VERSION ""

NS_ :

BS_:

BU_: GWM SCMB_PSM HVAC_RCCM GENERIC_GWMWakeup SOBDMD_AHCM_FOH TRM _delete SODL RTM PDM SCMH SCMG RSM SODR DDM RGTM DSM SCME TSTR

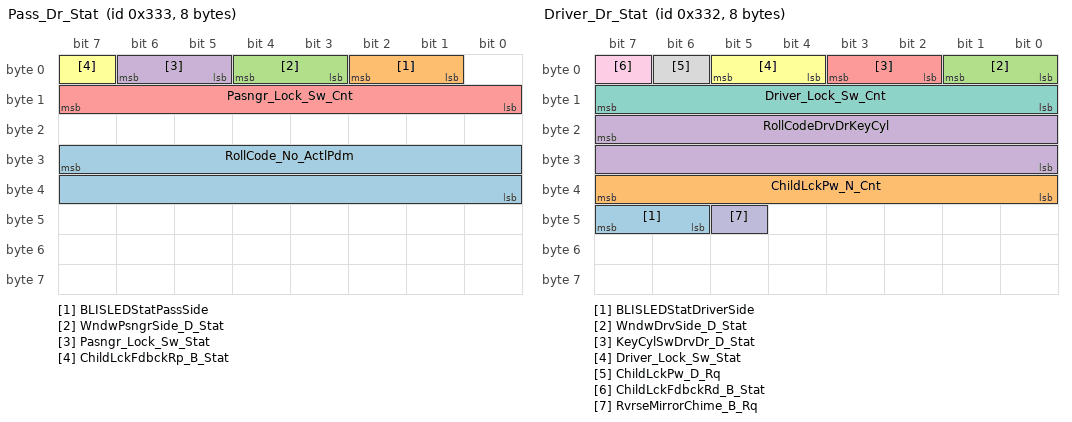
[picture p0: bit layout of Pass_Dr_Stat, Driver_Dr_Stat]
BO_ 819 Pass_Dr_Stat: 8 PDM
 SG_ RollCode_No_ActlPdm : 31|16@0+ (1,0) [0|65535] "Unitless"  GWM
 SG_ BLISLEDStatPassSide : 2|2@0+ (1,0) [0|3] "SED"  GWM,SODL,SODR
 SG_ WndwPsngrSide_D_Stat : 4|2@0+ (1,0) [0|3] "SED"  GWM
 SG_ Pasngr_Lock_Sw_Stat : 6|2@0+ (1,0) [0|3] "SED"  GWM
 SG_ Pasngr_Lock_Sw_Cnt : 15|8@0+ (1,0) [0|255] "Cnt"  GWM
 SG_ ChildLckFdbckRp_B_Stat : 7|1@0+ (1,0) [0|1] "SED"  GWM

BO_ 818 Driver_Dr_Stat: 8 DDM
 SG_ BLISLEDStatDriverSide : 47|2@0+ (1,0) [0|3] "SED"  GWM,SODL,SODR
 SG_ ChildLckPw_N_Cnt : 39|8@0+ (1,0) [0|255] "unitless"  GWM
 SG_ WndwDrvSide_D_Stat : 1|2@0+ (1,0) [0|3] "SED"  GWM
 SG_ RollCodeDrvDrKeyCyl : 23|16@0+ (1,0) [0|65535] "Unitless"  GWM
 SG_ KeyCylSwDrvDr_D_Stat : 3|2@0+ (1,0) [0|3] "SED"  GWM
 SG_ Driver_Lock_Sw_Stat : 5|2@0+ (1,0) [0|3] "SED"  GWM
 SG_ Driver_Lock_Sw_Cnt : 15|8@0+ (1,0) [0|255] "Cnt"  GWM
 SG_ ChildLckPw_D_Rq : 6|1@0+ (1,0) [0|1] "SED"  GWM
 SG_ ChildLckFdbckRd_B_Stat : 7|1@0+ (1,0) [0|1] "SED"  GWM
 SG_ RvrseMirrorChime_B_Rq : 45|1@0+ (1,0) [0|1] "SED"  DSM,GWM

BO_ 817 Locking_Systems_2_MS1: 8 GWM
 SG_ ChildLckMde_B_Stat : 56|1@0+ (1,0) [0|1] "SED" Vector__XXX
 SG_ VehLckInd_D_Rq : 58|2@0+ (1,0) [0|3] "SED"  DDM,PDM
 SG_ DrTgateOpen_B_Rq : 59|1@0+ (1,0) [0|1] "SED"  RGTM
 SG_ DrTgateExtSwMde_B_Stat : 32|1@0+ (1,0) [0|1] "SED"  RGTM
 SG_ Remote_Device_Feedback : 50|3@0+ (1,0) [0|7] "SED"  RSM,RTM
 SG_ Power_Liftgate_Rqst : 0|1@0+ (1,0) [0|1] "SED"  RGTM
 SG_ Power_Decklid_Rqst : 1|1@0+ (1,0) [0|1] "SED"  RGTM
 SG_ Keyfob_Pad_Msg_Count : 15|8@0+ (1,0) [0|255] "Counts"  RGTM
 SG_ Veh_Lock_Requestor : 55|5@0+ (1,0) [0|31] "SED"  HVAC_RCCM,RSM,DDM,PDM
 SG_ Veh_Lock_EvNum : 47|8@0+ (1,0) [0|255] "unitless"  HVAC_RCCM,RSM,DDM,PDM
 SG_ Veh_Lock_Sub_Id : 63|4@0+ (1,0) [0|15] "SED"  RSM,DDM,PDM
 SG_ ChildLck_D_Dsply : 7|2@0+ (1,0) [0|3] "SED"  DDM
 SG_ RollCodeUnlock : 23|16@0+ (1,0) [0|65535] "Unitless"  PDM,RSM,DDM
 SG_ Lockmsgtxt_D_Rq : 39|3@0+ (1,0) [0|7] "SED" Vector__XXX
 SG_ LockInhibit : 2|1@0+ (1,0) [0|1] "SED"  RGTM
 SG_ Veh_Lock_Status : 34|2@0+ (1,0) [0|3] "SED"  HVAC_RCCM,RSM,DDM,PDM,RGTM
 SG_ FobComm_D_Stat : 5|2@0+ (1,0) [0|3] "SED"  RTM
 SG_ WindowLockout_B_Stat : 35|1@0+ (1,0) [0|1] "SED"  SCMG,SCMH,SCMB_PSM,DDM

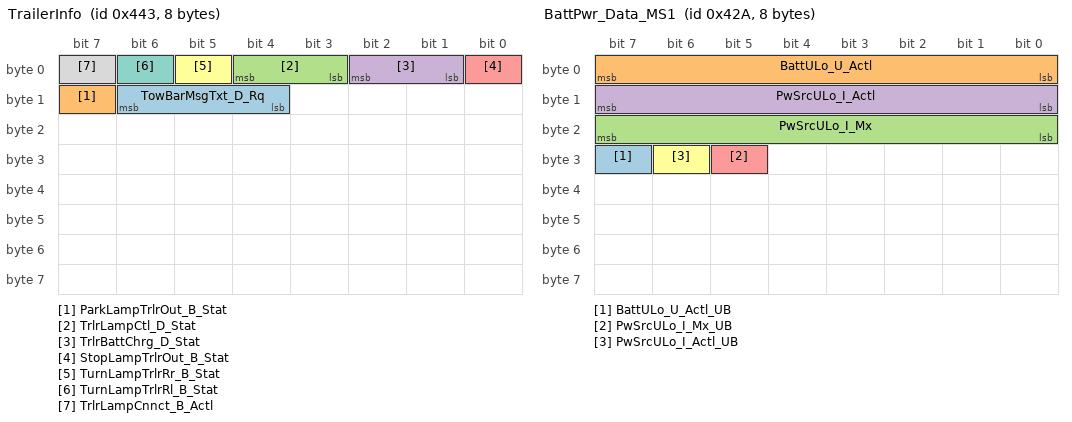
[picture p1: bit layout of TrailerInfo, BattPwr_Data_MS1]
BO_ 1091 TrailerInfo: 8 TRM
 SG_ TowBarMsgTxt_D_Rq : 14|3@0+ (1,0) [0|7] "SED"  GWM
 SG_ ParkLampTrlrOut_B_Stat : 15|1@0+ (1,0) [0|1] "SED"  GWM
 SG_ TrlrLampCtl_D_Stat : 4|2@0+ (1,0) [0|3] "SED"  GWM
 SG_ TrlrBattChrg_D_Stat : 2|2@0+ (1,0) [0|3] "SED"  GWM
 SG_ StopLampTrlrOut_B_Stat : 0|1@0+ (1,0) [0|1] "SED"  GWM
 SG_ TurnLampTrlrRr_B_Stat : 5|1@0+ (1,0) [0|1] "SED"  GWM
 SG_ TurnLampTrlrRl_B_Stat : 6|1@0+ (1,0) [0|1] "SED"  GWM
 SG_ TrlrLampCnnct_B_Actl : 7|1@0+ (1,0) [0|1] "SED"  SODR,SODL,GWM

BO_ 1865 TesterPhysicalResPDM: 8 PDM
 SG_ TesterPhysicalResPDM : 7|64@0+ (1,0) [0|1.84467E+019] "unitless"  TSTR

BO_ 1857 TesterPhysicalReqPDM: 8 TSTR
 SG_ TesterPhysicalReqPDM : 7|64@0+ (1,0) [0|1.84467E+019] "unitless"  PDM

BO_ 1819 TesterPhysicalResSCMH: 8 SCMH
 SG_ TesterPhysicalResSCMH : 7|64@0+ (1,0) [0|1.84467E+019] "unitless"  TSTR

BO_ 1818 TesterPhysicalResSCMG: 8 SCMG
 SG_ TesterPhysicalResSCMG : 7|64@0+ (1,0) [0|1.84467E+019] "unitless"  TSTR

BO_ 1811 TesterPhysicalReqSCMH: 8 TSTR
 SG_ TesterPhysicalReqSCMH : 7|64@0+ (1,0) [0|1.84467E+019] "unitless"  SCMH

BO_ 1810 TesterPhysicalReqSCMG: 8 TSTR
 SG_ TesterPhysicalReqSCMG : 7|64@0+ (1,0) [0|1.84467E+019] "unitless"  SCMG

BO_ 1310 GWM_Network_MgmtM_MS1: 8 GWM
 SG_ GWM_Network_Mgmt_MS1 : 7|64@0+ (1,0) [0|1.844674407371E+019] "unitless"  RSM,DDM

BO_ 1066 BattPwr_Data_MS1: 8 GWM
 SG_ BattULo_U_Actl_UB : 31|1@0+ (1,0) [0|1] "SED"  HVAC_RCCM
 SG_ BattULo_U_Actl : 7|8@0+ (0.0625,0) [0|15.875] "volt"  HVAC_RCCM
 SG_ PwSrcULo_I_Mx : 23|8@0+ (1,0) [0|254] "ampere"  HVAC_RCCM
 SG_ PwSrcULo_I_Actl : 15|8@0+ (1,0) [0|254] "ampere"  HVAC_RCCM
 SG_ PwSrcULo_I_Mx_UB : 29|1@0+ (1,0) [0|1] "SED"  HVAC_RCCM
 SG_ PwSrcULo_I_Actl_UB : 30|1@0+ (1,0) [0|1] "SED"  HVAC_RCCM

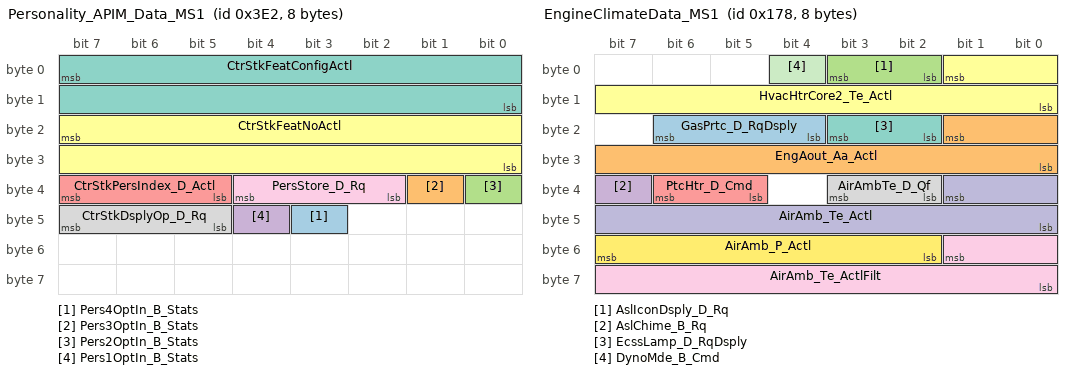
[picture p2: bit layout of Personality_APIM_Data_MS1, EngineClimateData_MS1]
BO_ 994 Personality_APIM_Data_MS1: 8 GWM
 SG_ Pers4OptIn_B_Stats : 43|1@0+ (1,0) [0|1] "SED" Vector__XXX
 SG_ Pers3OptIn_B_Stats : 33|1@0+ (1,0) [0|1] "SED" Vector__XXX
 SG_ Pers2OptIn_B_Stats : 32|1@0+ (1,0) [0|1] "SED" Vector__XXX
 SG_ Pers1OptIn_B_Stats : 44|1@0+ (1,0) [0|1] "SED" Vector__XXX
 SG_ CtrStkPersIndex_D_Actl : 39|3@0+ (1,0) [0|7] "SED"  HVAC_RCCM,PDM,DDM,DSM,SCMG,SCMH
 SG_ CtrStkFeatNoActl : 23|16@0+ (1,0) [0|65535] "Undefined"  HVAC_RCCM,PDM,DDM,DSM
 SG_ CtrStkFeatConfigActl : 7|16@0+ (1,0) [0|65535] "Undefined"  HVAC_RCCM,PDM,DDM,DSM
 SG_ CtrStkDsplyOp_D_Rq : 47|3@0+ (1,0) [0|7] "SED"  HVAC_RCCM,PDM,DDM,DSM,SCMG,SCMH
 SG_ PersStore_D_Rq : 36|3@0+ (1,0) [0|7] "SED"  DSM

BO_ 376 EngineClimateData_MS1: 8 GWM
 SG_ GasPrtc_D_RqDsply : 22|3@0+ (1,0) [0|7] "SED" Vector__XXX
 SG_ EngAout_Aa_Actl : 17|10@0+ (0.05,-25.6) [-25.6|25.55] "rpm/ms" Vector__XXX
 SG_ AslIconDsply_D_Rq : 3|2@0+ (1,0) [0|3] "SED" Vector__XXX
 SG_ AslChime_B_Rq : 39|1@0+ (1,0) [0|1] "SED" Vector__XXX
 SG_ PtcHtr_D_Cmd : 38|2@0+ (1,0) [0|3] "SED" Vector__XXX
 SG_ HvacHtrCore2_Te_Actl : 1|10@0+ (0.25,-50) [-50|205.5] "degC"  HVAC_RCCM
 SG_ EcssLamp_D_RqDsply : 19|2@0+ (1,0) [0|3] "SED" Vector__XXX
 SG_ AirAmbTe_D_Qf : 35|2@0+ (1,0) [0|3] "SED"  HVAC_RCCM
 SG_ AirAmb_Te_ActlFilt : 49|10@0+ (0.25,-128) [-128|127.75] "deg C"  HVAC_RCCM
 SG_ AirAmb_Te_Actl : 33|10@0+ (0.25,-128) [-128|127.75] "degC"  HVAC_RCCM
 SG_ DynoMde_B_Cmd : 4|1@0+ (1,0) [0|1] "SED" Vector__XXX
 SG_ AirAmb_P_Actl : 55|6@0+ (10,500) [500|1110] "mbar"  SOBDMD_AHCM_FOH

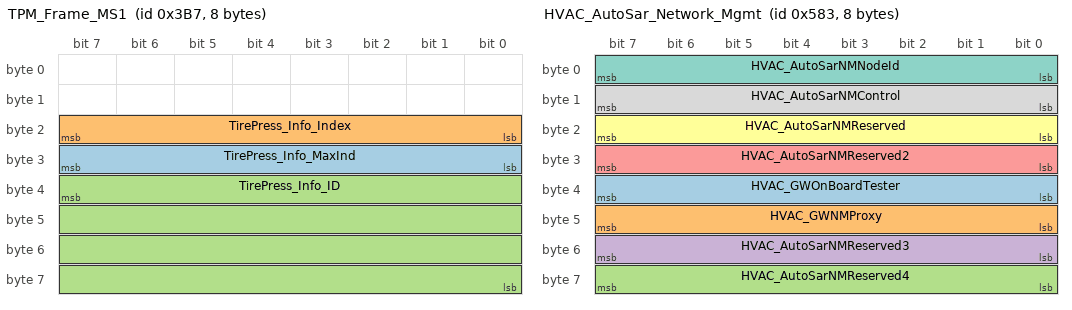
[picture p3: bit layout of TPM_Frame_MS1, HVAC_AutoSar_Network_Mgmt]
BO_ 951 TPM_Frame_MS1: 8 GWM
 SG_ TirePress_Info_MaxInd : 31|8@0+ (1,0) [0|255] "Unitless"  RTM
 SG_ TirePress_Info_Index : 23|8@0+ (1,0) [0|255] "Unitless"  RTM
 SG_ TirePress_Info_ID : 39|32@0+ (1,0) [0|4294967295] "Unitless"  RTM

BO_ 1068 Batt_Mgmt_Data_MS1: 8 GWM
 SG_ HvacAirFullOut_B_Rq_UB : 60|1@0+ (1,0) [0|1] "SED"  HVAC_RCCM
 SG_ HvacAirFullOut_B_Rq : 61|1@0+ (1,0) [0|1] "SED"  HVAC_RCCM
 SG_ HvacCmprLim_D_Stat_UB : 56|1@0+ (1,0) [0|1] "SED"  HVAC_RCCM
 SG_ HvacCmprLim_D_Stat : 59|3@0+ (1,0) [0|7] "SED"  HVAC_RCCM
 SG_ HvacAirFlw_B_RqBatt_UB : 62|1@0+ (1,0) [0|1] "SED"  HVAC_RCCM
 SG_ HvacAirFlw_B_RqBatt : 63|1@0+ (1,0) [0|1] "SED"  HVAC_RCCM
 SG_ HvacRec_D_RqMxBatt_UB : 21|1@0+ (1,0) [0|1] "SED"  HVAC_RCCM
 SG_ HvacRec_D_RqMxBatt : 20|4@0+ (1,0) [0|15] "SED"  HVAC_RCCM
 SG_ Batt_Lo_SoC_B_UB : 22|1@0+ (1,0) [0|1] "SED"  HVAC_RCCM,TRM
 SG_ Batt_Lo_SoC_B : 23|1@0+ (1,0) [0|1] "SED"  HVAC_RCCM,TRM
 SG_ Batt_Crit_SoC_B_UB : 14|1@0+ (1,0) [0|1] "SED"  HVAC_RCCM,TRM
 SG_ Batt_Crit_SoC_B : 15|1@0+ (1,0) [0|1] "SED"  HVAC_RCCM,TRM
 SG_ Shed_T_Eng_Off_B_UB : 12|1@0+ (1,0) [0|1] "SED"  HVAC_RCCM,TRM
 SG_ Shed_T_Eng_Off_B : 13|1@0+ (1,0) [0|1] "SED"  HVAC_RCCM,TRM
 SG_ Shed_Level_Req_UB : 8|1@0+ (1,0) [0|1] "SED"  HVAC_RCCM,DDM,PDM,TRM
 SG_ Shed_Level_Req : 11|3@0+ (1,0) [0|7] "SED"  HVAC_RCCM,DDM,PDM,TRM
 SG_ Shed_Feature_Group_ID_UB : 2|1@0+ (1,0) [0|1] "SED"  HVAC_RCCM,TRM
 SG_ Shed_Feature_Group_ID : 7|5@0+ (1,0) [0|31] "SED"  HVAC_RCCM,TRM
 SG_ Shed_Drain_Eng_Off_B_UB : 0|1@0+ (1,0) [0|1] "SED"  HVAC_RCCM,TRM
 SG_ Shed_Drain_Eng_Off_B : 1|1@0+ (1,0) [0|1] "SED"  HVAC_RCCM,TRM
 SG_ AirCondRec_B_Rq_UB : 44|1@0+ (1,0) [0|1] "SED"  HVAC_RCCM
 SG_ AirCondFluidHi_P_Actl_UB : 45|1@0+ (1,0) [0|1] "SED"  HVAC_RCCM
 SG_ AirCondFluidHi_P_Actl : 39|8@0+ (0.125,0) [0|31.625] "bar"  HVAC_RCCM
 SG_ AirCondClutch_B_Stats : 46|1@0+ (1,0) [0|1] "SED"  HVAC_RCCM
 SG_ AirCondClutch_B_Stats_UB : 43|1@0+ (1,0) [0|1] "SED"  HVAC_RCCM
 SG_ AirCondRec_B_Rq : 47|1@0+ (1,0) [0|1] "SED"  HVAC_RCCM

BO_ 963 BCM_Lamp_Stat_MS1: 8 GWM
 SG_ Illuminated_Entry_Stat : 63|2@0+ (1,0) [0|3] "SED" Vector__XXX
 SG_ Dr_Courtesy_Light_Stat : 49|2@0+ (1,0) [0|3] "SED" Vector__XXX
 SG_ ImpactEvntFdbck_D_Stat : 53|2@0+ (1,0) [0|3] "SED" Vector__XXX
 SG_ PudLampPsngr_D_Rq : 57|2@0+ (1,0) [0|3] "SED"  PDM
 SG_ HeadLampLoOut_B_Stat : 32|1@0+ (1,0) [0|1] "SED" Vector__XXX
 SG_ CrnrLghtRight_Pc_Rq : 47|7@0+ (1,0) [0|100] "percent" Vector__XXX
 SG_ CrnrLghtLeft_Pc_Rq : 39|7@0+ (1,0) [0|100] "percent" Vector__XXX
 SG_ HeadLghtHiFdbck_D_Stat : 55|2@0+ (1,0) [0|3] "SED" Vector__XXX
 SG_ PrkLightChime_B_Rq : 25|1@0+ (1,0) [0|1] "SED" Vector__XXX
 SG_ TrnNotInPrkChime_B_Rq : 24|1@0+ (1,0) [0|1] "SED" Vector__XXX
 SG_ HomeSafeLtChime_B_Rq : 28|1@0+ (1,0) [0|1] "SED" Vector__XXX
 SG_ StopLghtOn_B_Stat : 8|1@0+ (1,0) [0|1] "SED"  RSM,TRM
 SG_ RvrseLghtOn_B_Stat : 9|1@0+ (1,0) [0|1] "SED"  TRM
 SG_ PrkLght_D_Stat : 13|2@0+ (1,0) [0|3] "SED"  TRM
 SG_ HeadLghtSwtch_D_Stat : 15|2@0+ (1,0) [0|3] "SED" Vector__XXX
 SG_ KeyInIgnWarn_B_Cmd : 27|1@0+ (1,0) [0|1] "SED" Vector__XXX
 SG_ HeadLampLoFrOn_B_Stat : 2|1@0+ (1,0) [0|1] "SED" Vector__XXX
 SG_ HeadLampLoFlOn_B_Stat : 3|1@0+ (1,0) [0|1] "SED" Vector__XXX
 SG_ Headlamp_On_Wrning_Cmd : 29|1@0+ (1,0) [0|1] "SED" Vector__XXX
 SG_ HeadLampLoActv_B_Stat : 4|1@0+ (1,0) [0|1] "SED" Vector__XXX
 SG_ HeadLghtHiOn_B_Stat : 1|1@0+ (1,0) [0|1] "SED" Vector__XXX
 SG_ Park_Brake_Chime_Rqst : 26|1@0+ (1,0) [0|1] "SED" Vector__XXX
 SG_ BrkWarnInd_B_Rq : 20|1@0+ (1,0) [0|1] "SED" Vector__XXX
 SG_ Brk_Fluid_Lvl_Low : 31|2@0+ (1,0) [0|3] "SED" Vector__XXX
 SG_ ReducedGuard_D_Stat : 19|2@0+ (1,0) [0|3] "SED" Vector__XXX
 SG_ Courtesy_BSave_Stat : 7|2@0+ (1,0) [0|3] "SED"  DDM,PDM
 SG_ DayRnngLampOn_B_Stat : 5|1@0+ (1,0) [0|1] "SED" Vector__XXX
 SG_ PerimeterAlarmChimeRq : 0|1@0+ (1,0) [0|1] "SED" Vector__XXX
 SG_ PudLampDrv_D_Rq : 59|2@0+ (1,0) [0|3] "SED"  DDM
 SG_ Courtesy_Delay_Status : 51|2@0+ (1,0) [0|3] "SED" Vector__XXX
 SG_ Perimeter_Alarm_Status : 17|2@0+ (1,0) [0|3] "SED"  RSM
 SG_ WndwGlbl_D_Cmd : 23|3@0+ (1,0) [0|7] "SED"  DDM,PDM
 SG_ PudLamp_D_Rq : 11|2@0+ (1,0) [0|3] "SED"  DDM,PDM

BO_ 964 BodyInfo_MS1: 8 GWM
 SG_ FohEng_D_Rq_UB : 60|1@0+ (1,0) [0|1] "SED"  SOBDMD_AHCM_FOH
 SG_ FohEng_D_Rq : 62|2@0+ (1,0) [0|3] "SED"  SOBDMD_AHCM_FOH
 SG_ EcoMode_B_Stat_UB : 56|1@0+ (1,0) [0|1] "SED" Vector__XXX
 SG_ Cta_D_Rq_UB : 57|1@0+ (1,0) [0|1] "SED"  SODL,SODR
 SG_ Cta_D_Rq : 59|2@0+ (1,0) [0|3] "SED"  SODL,SODR
 SG_ GearRvrse_D_Actl_UB : 48|1@0+ (1,0) [0|1] "SED"  PDM,SODL,SODR,DDM
 SG_ GearRvrse_D_Actl : 51|3@0+ (1,0) [0|7] "SED"  PDM,SODL,SODR,DDM
 SG_ TurnLghtSwtch_D_Stat_UB : 52|1@0+ (1,0) [0|1] "SED"  SODL,SODR
 SG_ TurnLghtSwtch_D_Stat : 54|2@0+ (1,0) [0|3] "SED"  SODL,SODR
 SG_ Power_Liftgate_Mode_Cmd_UB : 6|1@0+ (1,0) [0|1] "SED"  RGTM
 SG_ Power_Liftgate_Mode_Cmd : 7|1@0+ (1,0) [0|1] "SED"  RGTM
 SG_ EcoMode_B_Stat : 20|1@0+ (1,0) [0|1] "SED" Vector__XXX
 SG_ MetricActvTe_B_Actl_UB : 2|1@0+ (1,0) [0|1] "SED"  HVAC_RCCM
 SG_ MetricActvTe_B_Actl : 3|1@0+ (1,0) [0|1] "SED"  HVAC_RCCM
 SG_ EngClntTe_D_Qf : 22|2@0+ (1,0) [0|3] "SED"  HVAC_RCCM
 SG_ Sod_D_Rq : 1|2@0+ (1,0) [0|3] "SED"  SODL,SODR
 SG_ MetricActv_B_Actl : 5|1@0+ (1,0) [0|1] "SED"  HVAC_RCCM
 SG_ EngClnt_Te_Actl : 15|8@0+ (1,-60) [-60|195] "degC"  HVAC_RCCM,SOBDMD_AHCM_FOH
 SG_ MetricActv_B_Actl_UB : 4|1@0+ (1,0) [0|1] "SED"  HVAC_RCCM
 SG_ EngClnt_Te_Actl_UB : 23|1@0+ (1,0) [0|1] "SED"  HVAC_RCCM,SOBDMD_AHCM_FOH
 SG_ OCSSensrDataUpperLim_UB : 28|1@0+ (1,0) [0|1] "SED"  HVAC_RCCM,SCMG,SCMH
 SG_ OCSSensrDataUpperLim : 47|8@0+ (1,0) [0|254] "SED"  HVAC_RCCM,SCMG,SCMH
 SG_ OCSSensrDataLowerLim_UB : 29|1@0+ (1,0) [0|1] "SED"  HVAC_RCCM,SCMG,SCMH
 SG_ PrkAid_D_Falt : 18|3@0+ (1,0) [0|7] "SED" Vector__XXX
 SG_ OCSSensrDataLowerLim : 39|8@0+ (1,0) [0|254] "SED"  HVAC_RCCM,SCMG,SCMH
 SG_ PrkAid_D_Falt_UB : 63|1@0+ (1,0) [0|1] "SED" Vector__XXX
 SG_ WiprFront_D_Stat_UB : 55|1@0+ (1,0) [0|1] "SED"  HVAC_RCCM,SODL,SODR
 SG_ WiprFront_D_Stat : 27|4@0+ (1,0) [0|15] "SED"  HVAC_RCCM,SODL,SODR
 SG_ CamraDefog_B_Req_UB : 30|1@0+ (1,0) [0|1] "SED"  HVAC_RCCM
 SG_ Sod_D_Rq_UB : 19|1@0+ (1,0) [0|1] "SED"  SODL,SODR
 SG_ CamraDefog_B_Req : 31|1@0+ (1,0) [0|1] "SED"  HVAC_RCCM

BO_ 1843 TesterPhysicalReqHVAC_RCCM: 8 TSTR
 SG_ TesterPhysicalReqHVAC_RCCM : 7|64@0+ (1,0) [0|1.84467E+019] "unitless"  HVAC_RCCM

BO_ 1851 TesterPhysicalResHVAC_RCCM: 8 HVAC_RCCM
 SG_ TesterPhysicalResHVAC_RCCM : 7|64@0+ (1,0) [0|1.84467E+019] "unitless"  TSTR

BO_ 1411 HVAC_AutoSar_Network_Mgmt: 8 HVAC_RCCM
 SG_ HVAC_GWOnBoardTester : 39|8@0+ (1,0) [0|255] "unitless"  GWM
 SG_ HVAC_GWNMProxy : 47|8@0+ (1,0) [0|255] "unitless"  GWM
 SG_ HVAC_AutoSarNMReserved4 : 63|8@0+ (1,0) [0|255] "unitless"  GWM
 SG_ HVAC_AutoSarNMReserved3 : 55|8@0+ (1,0) [0|255] "unitless"  GWM
 SG_ HVAC_AutoSarNMReserved2 : 31|8@0+ (1,0) [0|255] "unitless"  GWM
 SG_ HVAC_AutoSarNMReserved : 23|8@0+ (1,0) [0|255] "unitless"  GWM
 SG_ HVAC_AutoSarNMNodeId : 7|8@0+ (1,0) [0|255] "unitless"  GWM
 SG_ HVAC_AutoSarNMControl : 15|8@0+ (1,0) [0|255] "unitless"  GWM

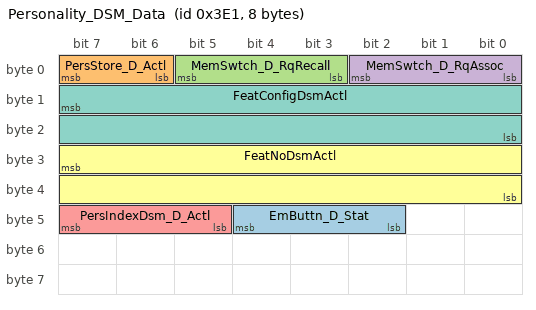
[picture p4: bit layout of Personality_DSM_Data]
BO_ 993 Personality_DSM_Data: 8 DSM
 SG_ EmButtn_D_Stat : 44|3@0+ (1,0) [0|7] "SED"  GWM
 SG_ PersStore_D_Actl : 7|2@0+ (1,0) [0|3] "SED"  GWM
 SG_ MemSwtch_D_RqRecall : 5|3@0+ (1,0) [0|7] "SED"  GWM
 SG_ MemSwtch_D_RqAssoc : 2|3@0+ (1,0) [0|7] "SED"  GWM
 SG_ PersIndexDsm_D_Actl : 47|3@0+ (1,0) [0|7] "SED"  GWM
 SG_ FeatNoDsmActl : 31|16@0+ (1,0) [0|65535] "Number"  GWM
 SG_ FeatConfigDsmActl : 15|16@0+ (1,0) [0|65535] "Undefined"  GWM

BO_ 1881 TesterPhysicalResRTM: 8 RTM
 SG_ TesterPhysicalResRTM : 7|64@0+ (1,0) [0|1.84467E+019] "unitless"  TSTR

BO_ 1873 TesterPhysicalReqRTM: 8 TSTR
 SG_ TesterPhysicalReqRTM : 7|64@0+ (1,0) [0|1.84467E+019] "unitless"  RTM

BO_ 2015 TesterFunctionalReq_M1: 8 TSTR
 SG_ TesterFunctionalReq : 7|64@0+ (1,0) [0|1.84467E+019] ""  SODR,SODL,SCMB_PSM,HVAC_RCCM,TSTR,SOBDMD_AHCM_FOH,PDM,SCMG,SCMH,TRM,RSM,RTM,GWM,DDM,DSM,RGTM,SCME

BO_ 320 LPwrSlideDr_Stat: 8 GENERIC_GWMWakeup
 SG_ PwSldDrIntSwL_B_Stat : 6|1@0+ (1,0) [0|1] "SED"  GWM
 SG_ LPwrSlideDr_Unlock_Rq : 7|1@0+ (1,0) [0|1] "SED"  GWM

BO_ 313 RPwrSlideDr_Stat: 8 GENERIC_GWMWakeup
 SG_ PwSldDrIntSwR_B_Stat : 6|1@0+ (1,0) [0|1] "SED"  GWM
 SG_ RPwrSlideDr_Unlock_Rq : 7|1@0+ (1,0) [0|1] "SED"  GWM

CM_ SG_ 376 EngAout_Aa_Actl "Signal not transmitted on HEV variants.";
CM_ SG_ 1068 AirCondClutch_B_Stats "Signal not transmitted on diesel variants.";
CM_ SG_ 1068 AirCondRec_B_Rq "Signal not transmitted on diesel variants.";
CM_ SG_ 964 FohEng_D_Rq "Signal not transmitted on vehicles that do not have the fuel operated heater feature.";
CM_ SG_ 964 GearRvrse_D_Actl "Do not implement GearRvrse_D_Actl  until eTracker 8804151 is approved, 11/24/09";
CM_ SG_ 964 MetricActv_B_Actl "0 =Inactive(English), 1=Active(Metric)";
CM_ BO_ 2015 "OBDII Request ($7DF) messages are for FNOS 1.0.1 only.
Diagnostic Functional Addressing ($7DF) and Dual Rate Periodic messages are for FNOS I3 only.";
CM_ SG_ 320 PwSldDrIntSwL_B_Stat "Signal not transmitted on vehicles without power sliding doors.";
CM_ SG_ 320 LPwrSlideDr_Unlock_Rq "Signal not transmitted on vehicles without power sliding doors.";
CM_ SG_ 313 PwSldDrIntSwR_B_Stat "Signal not transmitted on vehicles without power sliding doors.";
CM_ SG_ 313 RPwrSlideDr_Unlock_Rq "Signal not transmitted on vehicles without power sliding doors.";
BA_DEF_ BO_  "FrameGatewayNetwork" STRING ;
BA_DEF_ BO_  "FrameGatewayMS1" HEX 0 1407;
BA_DEF_ BO_  "NetworkInitialization" ENUM  "No","Yes";
BA_DEF_ BO_  "FrameGatewayId" HEX 0 1407;
BA_DEF_ BO_  "EventRateOfChange" INT 10 10000;
BA_DEF_ BO_  "GenMsgStartDelayTime" INT 0 10000;
BA_DEF_ BO_  "GenMsgNrOfRepetition" INT 0 100;
BA_DEF_ BO_  "GenMsgDelayTime" INT 0 1000;
BA_DEF_ BO_  "GenMsgCycleTime" INT 0 100000;
BA_DEF_ BO_  "GenMsgSendType" ENUM  "FixedPeriodic","Event","EnabledPeriodic","NotUsed","NotUsed","EventPeriodic","NotUsed","NotUsed","NoMsgSendType";
BA_DEF_ SG_  "U_P702_MY2021_Tx" ENUM  "No","Yes";
BA_DEF_ SG_  "U_CX727_MY2021_Tx" ENUM  "No","Yes";
BA_DEF_ SG_  "U_VN127_MY20_Tx" ENUM  "No","Yes";
BA_DEF_ SG_  "U_H567_MY20_Tx" ENUM  "No","Yes";
BA_DEF_ SG_  "U_CX430_MY2021_Tx" ENUM  "No","Yes";
BA_DEF_ SG_  "U_U611_U625_MY20_Phev_Tx" ENUM  "No","Yes";
BA_DEF_ SG_  "U_B562_MY18_Diesel_Tx" ENUM  "No","Yes";
BA_DEF_ SG_  "U_CX482_CX483_MY20_Tx" ENUM  "No","Yes";
BA_DEF_ SG_  "U_U611_U625_MY20_Hev_Tx" ENUM  "No","Yes";
BA_DEF_ SG_  "U_U611_U625_MY20_Gas_Tx" ENUM  "No","Yes";
BA_DEF_ SG_  "U_B500_MY18_Diesel_Tx" ENUM  "No","Yes";
BA_DEF_ SG_  "U_B500_MY18_Gas_Tx" ENUM  "No","Yes";
BA_DEF_ SG_  "U_C490_MY18_Tx" ENUM  "No","Yes";
BA_DEF_ SG_  "U_B562_MY18_Gas_Tx" ENUM  "No","Yes";
BA_DEF_ SG_  "U_C519_MY18_5_Gas_Tx" ENUM  "No","Yes";
BA_DEF_ SG_  "U_C519_MY18_5_Diesel_Tx" ENUM  "No","Yes";
BA_DEF_ SG_  "U_B515_MCA_MY17_Gas_Tx" ENUM  "No","Yes";
BA_DEF_ SG_  "U_B515_MCA_MY17_Diesel_Tx" ENUM  "No","Yes";
BA_DEF_ SG_  "U_B479_MY17_Diesel_Tx" ENUM  "No","Yes";
BA_DEF_ SG_  "U_B479_MY17_Gas_Tx" ENUM  "No","Yes";
BA_DEF_ SG_  "U_P702_MY2021_Rx" ENUM  "No","Yes";
BA_DEF_ SG_  "U_CX727_MY2021_Rx" ENUM  "No","Yes";
BA_DEF_ SG_  "U_VN127_MY20_Rx" ENUM  "No","Yes";
BA_DEF_ SG_  "U_H567_MY20_Rx" ENUM  "No","Yes";
BA_DEF_ SG_  "U_CX430_MY2021_Rx" ENUM  "No","Yes";
BA_DEF_ SG_  "U_U611_U625_MY20_Phev_Rx" ENUM  "No","Yes";
BA_DEF_ SG_  "U_B562_MY18_Diesel_Rx" ENUM  "No","Yes";
BA_DEF_ SG_  "U_CX482_CX483_MY20_Rx" ENUM  "No","Yes";
BA_DEF_ SG_  "U_U611_U625_MY20_Hev_Rx" ENUM  "No","Yes";
BA_DEF_ SG_  "U_U611_U625_MY20_Gas_Rx" ENUM  "No","Yes";
BA_DEF_ SG_  "U_B500_MY18_Diesel_Rx" ENUM  "No","Yes";
BA_DEF_ SG_  "U_B500_MY18_Gas_Rx" ENUM  "No","Yes";
BA_DEF_ SG_  "U_C490_MY18_Rx" ENUM  "No","Yes";
BA_DEF_ SG_  "U_B562_MY18_Gas_Rx" ENUM  "No","Yes";
BA_DEF_ SG_  "U_LC1_B515_MY17_Gas_Rx" ENUM  "No","Yes";
BA_DEF_ SG_  "U_LC1_B515_MY17_Diesel_Rx" ENUM  "No","Yes";
BA_DEF_ SG_  "U_C519_MY18_5_Gas_Rx" ENUM  "No","Yes";
BA_DEF_ SG_  "U_C519_MY18_5_Diesel_Rx" ENUM  "No","Yes";
BA_DEF_ SG_  "U_B515_MCA_MY17_Gas_Rx" ENUM  "No","Yes";
BA_DEF_ SG_  "U_B515_MCA_MY17_Diesel_Rx" ENUM  "No","Yes";
BA_DEF_ SG_  "U_B479_MY17_Diesel_Rx" ENUM  "No","Yes";
BA_DEF_ SG_  "U_B479_MY17_Gas_Rx" ENUM  "No","Yes";
BA_DEF_ SG_  "U_B562LC_MY15_Gas_Rx" ENUM  "No","Yes";
BA_DEF_ SG_  "U_B562LC_MY15_Diesel_Rx" ENUM  "No","Yes";
BA_DEF_ SG_  "GenSigStartValue" HEX 0 268435455;
BA_DEF_ SG_  "MetaData" ENUM  "No","Yes";
BA_DEF_ SG_  "ContentDependant" ENUM  "No","Yes";
BA_DEF_ SG_  "GenSigStartValueInteger" INT 0 1000000000;
BA_DEF_ SG_  "UsedOnPgmDBC" ENUM  "No","Yes";
BA_DEF_ SG_  "CrossOver_InfoCAN" ENUM  "No","Yes";
BA_DEF_ SG_  "WakeupSignal" ENUM  "No","Yes";
BA_DEF_ SG_  "GenSigInactiveValue" INT 0 100000;
BA_DEF_ SG_  "GenSigSendType" ENUM  "Cyclic","OnWrite","vector_leerstring","OnChange","vector_leerstring","IfActive","vector_leerstring","NoSigSendType";
BA_DEF_ BO_  "AuthFreshnessCounterSyncAttempt" INT 0 2;
BA_DEF_ BO_  "GenMsgRoutingTimeoutTime" INT 0 5000;
BA_DEF_ BO_  "MessageGateway" ENUM  "No","Yes";
BA_DEF_ BO_  "NmAsrMessage" ENUM  "No","Yes";
BA_DEF_ BO_  "DiagState" ENUM  "No","Yes";
BA_DEF_ BO_  "DiagRequest" ENUM  "No","Yes";
BA_DEF_ BO_  "DiagResponse" ENUM  "No","Yes";
BA_DEF_ BO_  "NmMessage" ENUM  "No","Yes";
BA_DEF_ BO_  "GenMsgILSupport" ENUM  "No","Yes";
BA_DEF_DEF_  "FrameGatewayNetwork" "NONE";
BA_DEF_DEF_  "FrameGatewayMS1" 0;
BA_DEF_DEF_  "NetworkInitialization" "Yes";
BA_DEF_DEF_  "FrameGatewayId" 0;
BA_DEF_DEF_  "EventRateOfChange" 10000;
BA_DEF_DEF_  "GenMsgStartDelayTime" 0;
BA_DEF_DEF_  "GenMsgNrOfRepetition" 1;
BA_DEF_DEF_  "GenMsgDelayTime" 20;
BA_DEF_DEF_  "GenMsgCycleTime" 0;
BA_DEF_DEF_  "GenMsgSendType" "NoMsgSendType";
BA_DEF_DEF_  "U_P702_MY2021_Tx" "No";
BA_DEF_DEF_  "U_CX727_MY2021_Tx" "No";
BA_DEF_DEF_  "U_VN127_MY20_Tx" "No";
BA_DEF_DEF_  "U_H567_MY20_Tx" "No";
BA_DEF_DEF_  "U_CX430_MY2021_Tx" "No";
BA_DEF_DEF_  "U_U611_U625_MY20_Phev_Tx" "No";
BA_DEF_DEF_  "U_B562_MY18_Diesel_Tx" "No";
BA_DEF_DEF_  "U_CX482_CX483_MY20_Tx" "No";
BA_DEF_DEF_  "U_U611_U625_MY20_Hev_Tx" "No";
BA_DEF_DEF_  "U_U611_U625_MY20_Gas_Tx" "No";
BA_DEF_DEF_  "U_B500_MY18_Diesel_Tx" "No";
BA_DEF_DEF_  "U_B500_MY18_Gas_Tx" "No";
BA_DEF_DEF_  "U_C490_MY18_Tx" "No";
BA_DEF_DEF_  "U_B562_MY18_Gas_Tx" "No";
BA_DEF_DEF_  "U_C519_MY18_5_Gas_Tx" "No";
BA_DEF_DEF_  "U_C519_MY18_5_Diesel_Tx" "No";
BA_DEF_DEF_  "U_B515_MCA_MY17_Gas_Tx" "No";
BA_DEF_DEF_  "U_B515_MCA_MY17_Diesel_Tx" "No";
BA_DEF_DEF_  "U_B479_MY17_Diesel_Tx" "No";
BA_DEF_DEF_  "U_B479_MY17_Gas_Tx" "No";
BA_DEF_DEF_  "U_P702_MY2021_Rx" "No";
BA_DEF_DEF_  "U_CX727_MY2021_Rx" "No";
BA_DEF_DEF_  "U_VN127_MY20_Rx" "No";
BA_DEF_DEF_  "U_H567_MY20_Rx" "No";
BA_DEF_DEF_  "U_CX430_MY2021_Rx" "No";
BA_DEF_DEF_  "U_U611_U625_MY20_Phev_Rx" "No";
BA_DEF_DEF_  "U_B562_MY18_Diesel_Rx" "No";
BA_DEF_DEF_  "U_CX482_CX483_MY20_Rx" "No";
BA_DEF_DEF_  "U_U611_U625_MY20_Hev_Rx" "No";
BA_DEF_DEF_  "U_U611_U625_MY20_Gas_Rx" "No";
BA_DEF_DEF_  "U_B500_MY18_Diesel_Rx" "No";
BA_DEF_DEF_  "U_B500_MY18_Gas_Rx" "No";
BA_DEF_DEF_  "U_C490_MY18_Rx" "No";
BA_DEF_DEF_  "U_B562_MY18_Gas_Rx" "No";
BA_DEF_DEF_  "U_LC1_B515_MY17_Gas_Rx" "No";
BA_DEF_DEF_  "U_LC1_B515_MY17_Diesel_Rx" "No";
BA_DEF_DEF_  "U_C519_MY18_5_Gas_Rx" "No";
BA_DEF_DEF_  "U_C519_MY18_5_Diesel_Rx" "No";
BA_DEF_DEF_  "U_B515_MCA_MY17_Gas_Rx" "No";
BA_DEF_DEF_  "U_B515_MCA_MY17_Diesel_Rx" "No";
BA_DEF_DEF_  "U_B479_MY17_Diesel_Rx" "No";
BA_DEF_DEF_  "U_B479_MY17_Gas_Rx" "No";
BA_DEF_DEF_  "U_B562LC_MY15_Gas_Rx" "No";
BA_DEF_DEF_  "U_B562LC_MY15_Diesel_Rx" "No";
BA_DEF_DEF_  "GenSigStartValue" 0;
BA_DEF_DEF_  "MetaData" "No";
BA_DEF_DEF_  "ContentDependant" "No";
BA_DEF_DEF_  "GenSigStartValueInteger" 0;
BA_DEF_DEF_  "UsedOnPgmDBC" "Yes";
BA_DEF_DEF_  "CrossOver_InfoCAN" "No";
BA_DEF_DEF_  "WakeupSignal" "No";
BA_DEF_DEF_  "GenSigInactiveValue" 0;
BA_DEF_DEF_  "GenSigSendType" "NoSigSendType";
BA_DEF_DEF_  "AuthFreshnessCounterSyncAttempt" 2;
BA_DEF_DEF_  "GenMsgRoutingTimeoutTime" 0;
BA_DEF_DEF_  "MessageGateway" "No";
BA_DEF_DEF_  "NmAsrMessage" "No";
BA_DEF_DEF_  "DiagState" "No";
BA_DEF_DEF_  "DiagRequest" "No";
BA_DEF_DEF_  "DiagResponse" "No";
BA_DEF_DEF_  "NmMessage" "No";
BA_DEF_DEF_  "GenMsgILSupport" "Yes";
BA_ "GenMsgStartDelayTime" BO_ 819 100;
BA_ "GenMsgCycleTime" BO_ 819 100;
BA_ "GenMsgSendType" BO_ 819 5;
BA_ "GenMsgStartDelayTime" BO_ 818 100;
BA_ "GenMsgCycleTime" BO_ 818 100;
BA_ "GenMsgSendType" BO_ 818 5;
BA_ "GenMsgSendType" BO_ 817 5;
BA_ "GenMsgCycleTime" BO_ 817 1000;
BA_ "FrameGatewayNetwork" BO_ 817 "HS1_CAN";
BA_ "FrameGatewayId" BO_ 817 817;
BA_ "GenMsgCycleTime" BO_ 1091 1000;
BA_ "GenMsgSendType" BO_ 1091 5;
BA_ "NetworkInitialization" BO_ 1865 0;
BA_ "GenMsgDelayTime" BO_ 1865 0;
BA_ "GenMsgSendType" BO_ 1865 1;
BA_ "DiagResponse" BO_ 1865 1;
BA_ "GenMsgILSupport" BO_ 1865 0;
BA_ "NetworkInitialization" BO_ 1857 0;
BA_ "GenMsgDelayTime" BO_ 1857 0;
BA_ "GenMsgSendType" BO_ 1857 1;
BA_ "DiagRequest" BO_ 1857 1;
BA_ "GenMsgILSupport" BO_ 1857 0;
BA_ "NetworkInitialization" BO_ 1819 0;
BA_ "GenMsgDelayTime" BO_ 1819 0;
BA_ "GenMsgSendType" BO_ 1819 1;
BA_ "DiagResponse" BO_ 1819 1;
BA_ "GenMsgILSupport" BO_ 1819 0;
BA_ "NetworkInitialization" BO_ 1818 0;
BA_ "GenMsgDelayTime" BO_ 1818 0;
BA_ "GenMsgSendType" BO_ 1818 1;
BA_ "DiagResponse" BO_ 1818 1;
BA_ "GenMsgILSupport" BO_ 1818 0;
BA_ "NetworkInitialization" BO_ 1811 0;
BA_ "GenMsgDelayTime" BO_ 1811 0;
BA_ "GenMsgSendType" BO_ 1811 1;
BA_ "DiagRequest" BO_ 1811 1;
BA_ "GenMsgILSupport" BO_ 1811 0;
BA_ "NetworkInitialization" BO_ 1810 0;
BA_ "GenMsgDelayTime" BO_ 1810 0;
BA_ "GenMsgSendType" BO_ 1810 1;
BA_ "DiagRequest" BO_ 1810 1;
BA_ "GenMsgILSupport" BO_ 1810 0;
BA_ "GenMsgSendType" BO_ 1310 1;
BA_ "NmMessage" BO_ 1310 1;
BA_ "GenMsgILSupport" BO_ 1310 0;
BA_ "GenMsgCycleTime" BO_ 1066 50;
BA_ "GenMsgSendType" BO_ 1066 5;
BA_ "GenMsgSendType" BO_ 994 5;
BA_ "GenMsgCycleTime" BO_ 994 1000;
BA_ "FrameGatewayId" BO_ 994 994;
BA_ "FrameGatewayNetwork" BO_ 994 "HS1_CAN";
BA_ "GenMsgSendType" BO_ 376 5;
BA_ "GenMsgCycleTime" BO_ 376 1000;
BA_ "FrameGatewayNetwork" BO_ 376 "HS1_CAN";
BA_ "FrameGatewayId" BO_ 376 376;
BA_ "FrameGatewayNetwork" BO_ 951 "HS1_CAN";
BA_ "FrameGatewayId" BO_ 951 951;
BA_ "GenMsgCycleTime" BO_ 1068 50;
BA_ "GenMsgSendType" BO_ 1068 5;
BA_ "FrameGatewayNetwork" BO_ 963 "HS1_CAN";
BA_ "FrameGatewayId" BO_ 963 963;
BA_ "GenMsgCycleTime" BO_ 964 200;
BA_ "GenMsgSendType" BO_ 964 5;
BA_ "NetworkInitialization" BO_ 1843 0;
BA_ "GenMsgDelayTime" BO_ 1843 0;
BA_ "GenMsgSendType" BO_ 1843 1;
BA_ "DiagRequest" BO_ 1843 1;
BA_ "GenMsgILSupport" BO_ 1843 0;
BA_ "NetworkInitialization" BO_ 1851 0;
BA_ "GenMsgDelayTime" BO_ 1851 0;
BA_ "GenMsgSendType" BO_ 1851 1;
BA_ "DiagResponse" BO_ 1851 1;
BA_ "GenMsgILSupport" BO_ 1851 0;
BA_ "NetworkInitialization" BO_ 1411 0;
BA_ "GenMsgCycleTime" BO_ 1411 1000;
BA_ "GenMsgSendType" BO_ 1411 0;
BA_ "NmAsrMessage" BO_ 1411 1;
BA_ "GenMsgILSupport" BO_ 1411 0;
BA_ "GenMsgStartDelayTime" BO_ 993 100;
BA_ "GenMsgCycleTime" BO_ 993 1000;
BA_ "GenMsgSendType" BO_ 993 5;
BA_ "NetworkInitialization" BO_ 1881 0;
BA_ "GenMsgDelayTime" BO_ 1881 0;
BA_ "GenMsgSendType" BO_ 1881 1;
BA_ "DiagResponse" BO_ 1881 1;
BA_ "GenMsgILSupport" BO_ 1881 0;
BA_ "NetworkInitialization" BO_ 1873 0;
BA_ "GenMsgDelayTime" BO_ 1873 0;
BA_ "GenMsgSendType" BO_ 1873 1;
BA_ "DiagRequest" BO_ 1873 1;
BA_ "GenMsgILSupport" BO_ 1873 0;
BA_ "NetworkInitialization" BO_ 2015 0;
BA_ "GenMsgDelayTime" BO_ 2015 0;
BA_ "GenMsgSendType" BO_ 2015 1;
BA_ "DiagState" BO_ 2015 1;
BA_ "GenMsgILSupport" BO_ 2015 0;
BA_ "U_P702_MY2021_Tx" SG_ 819 RollCode_No_ActlPdm 1;
BA_ "U_CX430_MY2021_Tx" SG_ 819 RollCode_No_ActlPdm 1;
BA_ "U_U611_U625_MY20_Phev_Tx" SG_ 819 RollCode_No_ActlPdm 1;
BA_ "U_CX482_CX483_MY20_Tx" SG_ 819 RollCode_No_ActlPdm 1;
BA_ "U_U611_U625_MY20_Hev_Tx" SG_ 819 RollCode_No_ActlPdm 1;
BA_ "U_U611_U625_MY20_Gas_Tx" SG_ 819 RollCode_No_ActlPdm 1;
BA_ "U_C519_MY18_5_Gas_Tx" SG_ 819 RollCode_No_ActlPdm 1;
BA_ "U_C519_MY18_5_Diesel_Tx" SG_ 819 RollCode_No_ActlPdm 1;
BA_ "U_B479_MY17_Diesel_Tx" SG_ 819 RollCode_No_ActlPdm 1;
BA_ "U_B479_MY17_Gas_Tx" SG_ 819 RollCode_No_ActlPdm 1;
BA_ "U_P702_MY2021_Tx" SG_ 819 BLISLEDStatPassSide 1;
BA_ "U_CX430_MY2021_Tx" SG_ 819 BLISLEDStatPassSide 1;
BA_ "U_U611_U625_MY20_Phev_Tx" SG_ 819 BLISLEDStatPassSide 1;
BA_ "U_CX482_CX483_MY20_Tx" SG_ 819 BLISLEDStatPassSide 1;
BA_ "U_U611_U625_MY20_Hev_Tx" SG_ 819 BLISLEDStatPassSide 1;
BA_ "U_U611_U625_MY20_Gas_Tx" SG_ 819 BLISLEDStatPassSide 1;
BA_ "U_C490_MY18_Tx" SG_ 819 BLISLEDStatPassSide 1;
BA_ "U_C519_MY18_5_Gas_Tx" SG_ 819 BLISLEDStatPassSide 1;
BA_ "U_C519_MY18_5_Diesel_Tx" SG_ 819 BLISLEDStatPassSide 1;
BA_ "U_B515_MCA_MY17_Gas_Tx" SG_ 819 BLISLEDStatPassSide 1;
BA_ "U_B515_MCA_MY17_Diesel_Tx" SG_ 819 BLISLEDStatPassSide 1;
BA_ "U_B479_MY17_Diesel_Tx" SG_ 819 BLISLEDStatPassSide 1;
BA_ "U_B479_MY17_Gas_Tx" SG_ 819 BLISLEDStatPassSide 1;
BA_ "U_CX727_MY2021_Rx" SG_ 819 BLISLEDStatPassSide 1;
BA_ "U_CX430_MY2021_Rx" SG_ 819 BLISLEDStatPassSide 1;
BA_ "U_U611_U625_MY20_Phev_Rx" SG_ 819 BLISLEDStatPassSide 1;
BA_ "U_CX482_CX483_MY20_Rx" SG_ 819 BLISLEDStatPassSide 1;
BA_ "U_U611_U625_MY20_Hev_Rx" SG_ 819 BLISLEDStatPassSide 1;
BA_ "U_U611_U625_MY20_Gas_Rx" SG_ 819 BLISLEDStatPassSide 1;
BA_ "U_C519_MY18_5_Gas_Rx" SG_ 819 BLISLEDStatPassSide 1;
BA_ "U_C519_MY18_5_Diesel_Rx" SG_ 819 BLISLEDStatPassSide 1;
BA_ "U_B515_MCA_MY17_Gas_Rx" SG_ 819 BLISLEDStatPassSide 1;
BA_ "U_B515_MCA_MY17_Diesel_Rx" SG_ 819 BLISLEDStatPassSide 1;
BA_ "U_B479_MY17_Diesel_Rx" SG_ 819 BLISLEDStatPassSide 1;
BA_ "U_B479_MY17_Gas_Rx" SG_ 819 BLISLEDStatPassSide 1;
BA_ "U_B562LC_MY15_Gas_Rx" SG_ 819 BLISLEDStatPassSide 1;
BA_ "GenSigSendType" SG_ 819 BLISLEDStatPassSide 3;
BA_ "U_P702_MY2021_Tx" SG_ 819 WndwPsngrSide_D_Stat 1;
BA_ "U_CX430_MY2021_Tx" SG_ 819 WndwPsngrSide_D_Stat 1;
BA_ "U_U611_U625_MY20_Phev_Tx" SG_ 819 WndwPsngrSide_D_Stat 1;
BA_ "U_CX482_CX483_MY20_Tx" SG_ 819 WndwPsngrSide_D_Stat 1;
BA_ "U_U611_U625_MY20_Hev_Tx" SG_ 819 WndwPsngrSide_D_Stat 1;
BA_ "U_U611_U625_MY20_Gas_Tx" SG_ 819 WndwPsngrSide_D_Stat 1;
BA_ "U_C490_MY18_Tx" SG_ 819 WndwPsngrSide_D_Stat 1;
BA_ "U_C519_MY18_5_Gas_Tx" SG_ 819 WndwPsngrSide_D_Stat 1;
BA_ "U_C519_MY18_5_Diesel_Tx" SG_ 819 WndwPsngrSide_D_Stat 1;
BA_ "U_B515_MCA_MY17_Gas_Tx" SG_ 819 WndwPsngrSide_D_Stat 1;
BA_ "U_B515_MCA_MY17_Diesel_Tx" SG_ 819 WndwPsngrSide_D_Stat 1;
BA_ "U_B479_MY17_Diesel_Tx" SG_ 819 WndwPsngrSide_D_Stat 1;
BA_ "U_B479_MY17_Gas_Tx" SG_ 819 WndwPsngrSide_D_Stat 1;
BA_ "GenSigSendType" SG_ 819 WndwPsngrSide_D_Stat 3;
BA_ "U_P702_MY2021_Tx" SG_ 819 Pasngr_Lock_Sw_Stat 1;
BA_ "U_CX430_MY2021_Tx" SG_ 819 Pasngr_Lock_Sw_Stat 1;
BA_ "U_U611_U625_MY20_Phev_Tx" SG_ 819 Pasngr_Lock_Sw_Stat 1;
BA_ "U_CX482_CX483_MY20_Tx" SG_ 819 Pasngr_Lock_Sw_Stat 1;
BA_ "U_U611_U625_MY20_Hev_Tx" SG_ 819 Pasngr_Lock_Sw_Stat 1;
BA_ "U_U611_U625_MY20_Gas_Tx" SG_ 819 Pasngr_Lock_Sw_Stat 1;
BA_ "U_C490_MY18_Tx" SG_ 819 Pasngr_Lock_Sw_Stat 1;
BA_ "U_C519_MY18_5_Gas_Tx" SG_ 819 Pasngr_Lock_Sw_Stat 1;
BA_ "U_C519_MY18_5_Diesel_Tx" SG_ 819 Pasngr_Lock_Sw_Stat 1;
BA_ "U_B515_MCA_MY17_Gas_Tx" SG_ 819 Pasngr_Lock_Sw_Stat 1;
BA_ "U_B515_MCA_MY17_Diesel_Tx" SG_ 819 Pasngr_Lock_Sw_Stat 1;
BA_ "U_B479_MY17_Diesel_Tx" SG_ 819 Pasngr_Lock_Sw_Stat 1;
BA_ "U_B479_MY17_Gas_Tx" SG_ 819 Pasngr_Lock_Sw_Stat 1;
BA_ "U_B479_MY17_Gas_Rx" SG_ 819 Pasngr_Lock_Sw_Stat 1;
BA_ "GenSigSendType" SG_ 819 Pasngr_Lock_Sw_Stat 3;
BA_ "WakeupSignal" SG_ 819 Pasngr_Lock_Sw_Stat 1;
BA_ "U_P702_MY2021_Tx" SG_ 819 Pasngr_Lock_Sw_Cnt 1;
BA_ "U_CX430_MY2021_Tx" SG_ 819 Pasngr_Lock_Sw_Cnt 1;
BA_ "U_U611_U625_MY20_Phev_Tx" SG_ 819 Pasngr_Lock_Sw_Cnt 1;
BA_ "U_CX482_CX483_MY20_Tx" SG_ 819 Pasngr_Lock_Sw_Cnt 1;
BA_ "U_U611_U625_MY20_Hev_Tx" SG_ 819 Pasngr_Lock_Sw_Cnt 1;
BA_ "U_U611_U625_MY20_Gas_Tx" SG_ 819 Pasngr_Lock_Sw_Cnt 1;
BA_ "U_C490_MY18_Tx" SG_ 819 Pasngr_Lock_Sw_Cnt 1;
BA_ "U_C519_MY18_5_Gas_Tx" SG_ 819 Pasngr_Lock_Sw_Cnt 1;
BA_ "U_C519_MY18_5_Diesel_Tx" SG_ 819 Pasngr_Lock_Sw_Cnt 1;
BA_ "U_B515_MCA_MY17_Gas_Tx" SG_ 819 Pasngr_Lock_Sw_Cnt 1;
BA_ "U_B515_MCA_MY17_Diesel_Tx" SG_ 819 Pasngr_Lock_Sw_Cnt 1;
BA_ "U_B479_MY17_Diesel_Tx" SG_ 819 Pasngr_Lock_Sw_Cnt 1;
BA_ "U_B479_MY17_Gas_Tx" SG_ 819 Pasngr_Lock_Sw_Cnt 1;
BA_ "U_B479_MY17_Gas_Rx" SG_ 819 Pasngr_Lock_Sw_Cnt 1;
BA_ "GenSigSendType" SG_ 819 Pasngr_Lock_Sw_Cnt 3;
BA_ "MetaData" SG_ 819 Pasngr_Lock_Sw_Cnt 1;
BA_ "WakeupSignal" SG_ 819 Pasngr_Lock_Sw_Cnt 1;
BA_ "U_P702_MY2021_Tx" SG_ 819 ChildLckFdbckRp_B_Stat 1;
BA_ "U_CX430_MY2021_Tx" SG_ 819 ChildLckFdbckRp_B_Stat 1;
BA_ "U_U611_U625_MY20_Phev_Tx" SG_ 819 ChildLckFdbckRp_B_Stat 1;
BA_ "U_CX482_CX483_MY20_Tx" SG_ 819 ChildLckFdbckRp_B_Stat 1;
BA_ "U_U611_U625_MY20_Hev_Tx" SG_ 819 ChildLckFdbckRp_B_Stat 1;
BA_ "U_U611_U625_MY20_Gas_Tx" SG_ 819 ChildLckFdbckRp_B_Stat 1;
BA_ "U_C490_MY18_Tx" SG_ 819 ChildLckFdbckRp_B_Stat 1;
BA_ "U_C519_MY18_5_Gas_Tx" SG_ 819 ChildLckFdbckRp_B_Stat 1;
BA_ "U_C519_MY18_5_Diesel_Tx" SG_ 819 ChildLckFdbckRp_B_Stat 1;
BA_ "U_B515_MCA_MY17_Gas_Tx" SG_ 819 ChildLckFdbckRp_B_Stat 1;
BA_ "U_B515_MCA_MY17_Diesel_Tx" SG_ 819 ChildLckFdbckRp_B_Stat 1;
BA_ "U_B479_MY17_Diesel_Tx" SG_ 819 ChildLckFdbckRp_B_Stat 1;
BA_ "U_B479_MY17_Gas_Tx" SG_ 819 ChildLckFdbckRp_B_Stat 1;
BA_ "U_B479_MY17_Gas_Rx" SG_ 819 ChildLckFdbckRp_B_Stat 1;
BA_ "GenSigSendType" SG_ 819 ChildLckFdbckRp_B_Stat 3;
BA_ "WakeupSignal" SG_ 819 ChildLckFdbckRp_B_Stat 1;
BA_ "U_P702_MY2021_Tx" SG_ 818 BLISLEDStatDriverSide 1;
BA_ "U_CX727_MY2021_Tx" SG_ 818 BLISLEDStatDriverSide 1;
BA_ "U_CX430_MY2021_Tx" SG_ 818 BLISLEDStatDriverSide 1;
BA_ "U_U611_U625_MY20_Phev_Tx" SG_ 818 BLISLEDStatDriverSide 1;
BA_ "U_CX482_CX483_MY20_Tx" SG_ 818 BLISLEDStatDriverSide 1;
BA_ "U_U611_U625_MY20_Hev_Tx" SG_ 818 BLISLEDStatDriverSide 1;
BA_ "U_U611_U625_MY20_Gas_Tx" SG_ 818 BLISLEDStatDriverSide 1;
BA_ "U_C490_MY18_Tx" SG_ 818 BLISLEDStatDriverSide 1;
BA_ "U_C519_MY18_5_Gas_Tx" SG_ 818 BLISLEDStatDriverSide 1;
BA_ "U_C519_MY18_5_Diesel_Tx" SG_ 818 BLISLEDStatDriverSide 1;
BA_ "U_B515_MCA_MY17_Gas_Tx" SG_ 818 BLISLEDStatDriverSide 1;
BA_ "U_B515_MCA_MY17_Diesel_Tx" SG_ 818 BLISLEDStatDriverSide 1;
BA_ "U_B479_MY17_Diesel_Tx" SG_ 818 BLISLEDStatDriverSide 1;
BA_ "U_B479_MY17_Gas_Tx" SG_ 818 BLISLEDStatDriverSide 1;
BA_ "U_CX727_MY2021_Rx" SG_ 818 BLISLEDStatDriverSide 1;
BA_ "U_CX430_MY2021_Rx" SG_ 818 BLISLEDStatDriverSide 1;
BA_ "U_U611_U625_MY20_Phev_Rx" SG_ 818 BLISLEDStatDriverSide 1;
BA_ "U_CX482_CX483_MY20_Rx" SG_ 818 BLISLEDStatDriverSide 1;
BA_ "U_U611_U625_MY20_Hev_Rx" SG_ 818 BLISLEDStatDriverSide 1;
BA_ "U_U611_U625_MY20_Gas_Rx" SG_ 818 BLISLEDStatDriverSide 1;
BA_ "U_C519_MY18_5_Gas_Rx" SG_ 818 BLISLEDStatDriverSide 1;
BA_ "U_C519_MY18_5_Diesel_Rx" SG_ 818 BLISLEDStatDriverSide 1;
BA_ "U_B515_MCA_MY17_Gas_Rx" SG_ 818 BLISLEDStatDriverSide 1;
BA_ "U_B515_MCA_MY17_Diesel_Rx" SG_ 818 BLISLEDStatDriverSide 1;
BA_ "U_B479_MY17_Diesel_Rx" SG_ 818 BLISLEDStatDriverSide 1;
BA_ "U_B479_MY17_Gas_Rx" SG_ 818 BLISLEDStatDriverSide 1;
BA_ "U_B562LC_MY15_Gas_Rx" SG_ 818 BLISLEDStatDriverSide 1;
BA_ "GenSigSendType" SG_ 818 BLISLEDStatDriverSide 3;
BA_ "U_P702_MY2021_Tx" SG_ 818 ChildLckPw_N_Cnt 1;
BA_ "U_CX727_MY2021_Tx" SG_ 818 ChildLckPw_N_Cnt 1;
BA_ "U_CX430_MY2021_Tx" SG_ 818 ChildLckPw_N_Cnt 1;
BA_ "U_U611_U625_MY20_Phev_Tx" SG_ 818 ChildLckPw_N_Cnt 1;
BA_ "U_CX482_CX483_MY20_Tx" SG_ 818 ChildLckPw_N_Cnt 1;
BA_ "U_U611_U625_MY20_Hev_Tx" SG_ 818 ChildLckPw_N_Cnt 1;
BA_ "U_U611_U625_MY20_Gas_Tx" SG_ 818 ChildLckPw_N_Cnt 1;
BA_ "U_C490_MY18_Tx" SG_ 818 ChildLckPw_N_Cnt 1;
BA_ "U_C519_MY18_5_Gas_Tx" SG_ 818 ChildLckPw_N_Cnt 1;
BA_ "U_C519_MY18_5_Diesel_Tx" SG_ 818 ChildLckPw_N_Cnt 1;
BA_ "U_B515_MCA_MY17_Gas_Tx" SG_ 818 ChildLckPw_N_Cnt 1;
BA_ "U_B515_MCA_MY17_Diesel_Tx" SG_ 818 ChildLckPw_N_Cnt 1;
BA_ "U_B479_MY17_Diesel_Tx" SG_ 818 ChildLckPw_N_Cnt 1;
BA_ "U_B479_MY17_Gas_Tx" SG_ 818 ChildLckPw_N_Cnt 1;
BA_ "U_B479_MY17_Gas_Rx" SG_ 818 ChildLckPw_N_Cnt 1;
BA_ "GenSigSendType" SG_ 818 ChildLckPw_N_Cnt 3;
BA_ "WakeupSignal" SG_ 818 ChildLckPw_N_Cnt 1;
BA_ "U_P702_MY2021_Tx" SG_ 818 WndwDrvSide_D_Stat 1;
BA_ "U_CX727_MY2021_Tx" SG_ 818 WndwDrvSide_D_Stat 1;
BA_ "U_CX430_MY2021_Tx" SG_ 818 WndwDrvSide_D_Stat 1;
BA_ "U_U611_U625_MY20_Phev_Tx" SG_ 818 WndwDrvSide_D_Stat 1;
BA_ "U_CX482_CX483_MY20_Tx" SG_ 818 WndwDrvSide_D_Stat 1;
BA_ "U_U611_U625_MY20_Hev_Tx" SG_ 818 WndwDrvSide_D_Stat 1;
BA_ "U_U611_U625_MY20_Gas_Tx" SG_ 818 WndwDrvSide_D_Stat 1;
BA_ "U_C490_MY18_Tx" SG_ 818 WndwDrvSide_D_Stat 1;
BA_ "U_C519_MY18_5_Gas_Tx" SG_ 818 WndwDrvSide_D_Stat 1;
BA_ "U_C519_MY18_5_Diesel_Tx" SG_ 818 WndwDrvSide_D_Stat 1;
BA_ "U_B515_MCA_MY17_Gas_Tx" SG_ 818 WndwDrvSide_D_Stat 1;
BA_ "U_B515_MCA_MY17_Diesel_Tx" SG_ 818 WndwDrvSide_D_Stat 1;
BA_ "U_B479_MY17_Diesel_Tx" SG_ 818 WndwDrvSide_D_Stat 1;
BA_ "U_B479_MY17_Gas_Tx" SG_ 818 WndwDrvSide_D_Stat 1;
BA_ "GenSigSendType" SG_ 818 WndwDrvSide_D_Stat 3;
BA_ "U_P702_MY2021_Tx" SG_ 818 RollCodeDrvDrKeyCyl 1;
BA_ "U_CX727_MY2021_Tx" SG_ 818 RollCodeDrvDrKeyCyl 1;
BA_ "U_CX430_MY2021_Tx" SG_ 818 RollCodeDrvDrKeyCyl 1;
BA_ "U_U611_U625_MY20_Phev_Tx" SG_ 818 RollCodeDrvDrKeyCyl 1;
BA_ "U_CX482_CX483_MY20_Tx" SG_ 818 RollCodeDrvDrKeyCyl 1;
BA_ "U_U611_U625_MY20_Hev_Tx" SG_ 818 RollCodeDrvDrKeyCyl 1;
BA_ "U_U611_U625_MY20_Gas_Tx" SG_ 818 RollCodeDrvDrKeyCyl 1;
BA_ "U_C490_MY18_Tx" SG_ 818 RollCodeDrvDrKeyCyl 1;
BA_ "U_C519_MY18_5_Gas_Tx" SG_ 818 RollCodeDrvDrKeyCyl 1;
BA_ "U_C519_MY18_5_Diesel_Tx" SG_ 818 RollCodeDrvDrKeyCyl 1;
BA_ "U_B515_MCA_MY17_Gas_Tx" SG_ 818 RollCodeDrvDrKeyCyl 1;
BA_ "U_B515_MCA_MY17_Diesel_Tx" SG_ 818 RollCodeDrvDrKeyCyl 1;
BA_ "U_B479_MY17_Diesel_Tx" SG_ 818 RollCodeDrvDrKeyCyl 1;
BA_ "U_B479_MY17_Gas_Tx" SG_ 818 RollCodeDrvDrKeyCyl 1;
BA_ "GenSigSendType" SG_ 818 RollCodeDrvDrKeyCyl 3;
BA_ "U_P702_MY2021_Tx" SG_ 818 KeyCylSwDrvDr_D_Stat 1;
BA_ "U_CX727_MY2021_Tx" SG_ 818 KeyCylSwDrvDr_D_Stat 1;
BA_ "U_CX430_MY2021_Tx" SG_ 818 KeyCylSwDrvDr_D_Stat 1;
BA_ "U_U611_U625_MY20_Phev_Tx" SG_ 818 KeyCylSwDrvDr_D_Stat 1;
BA_ "U_CX482_CX483_MY20_Tx" SG_ 818 KeyCylSwDrvDr_D_Stat 1;
BA_ "U_U611_U625_MY20_Hev_Tx" SG_ 818 KeyCylSwDrvDr_D_Stat 1;
BA_ "U_U611_U625_MY20_Gas_Tx" SG_ 818 KeyCylSwDrvDr_D_Stat 1;
BA_ "U_C490_MY18_Tx" SG_ 818 KeyCylSwDrvDr_D_Stat 1;
BA_ "U_C519_MY18_5_Gas_Tx" SG_ 818 KeyCylSwDrvDr_D_Stat 1;
BA_ "U_C519_MY18_5_Diesel_Tx" SG_ 818 KeyCylSwDrvDr_D_Stat 1;
BA_ "U_B515_MCA_MY17_Gas_Tx" SG_ 818 KeyCylSwDrvDr_D_Stat 1;
BA_ "U_B515_MCA_MY17_Diesel_Tx" SG_ 818 KeyCylSwDrvDr_D_Stat 1;
BA_ "U_B479_MY17_Diesel_Tx" SG_ 818 KeyCylSwDrvDr_D_Stat 1;
BA_ "U_B479_MY17_Gas_Tx" SG_ 818 KeyCylSwDrvDr_D_Stat 1;
BA_ "U_B479_MY17_Gas_Rx" SG_ 818 KeyCylSwDrvDr_D_Stat 1;
BA_ "GenSigSendType" SG_ 818 KeyCylSwDrvDr_D_Stat 3;
BA_ "WakeupSignal" SG_ 818 KeyCylSwDrvDr_D_Stat 1;
BA_ "U_P702_MY2021_Tx" SG_ 818 Driver_Lock_Sw_Stat 1;
BA_ "U_CX727_MY2021_Tx" SG_ 818 Driver_Lock_Sw_Stat 1;
BA_ "U_CX430_MY2021_Tx" SG_ 818 Driver_Lock_Sw_Stat 1;
BA_ "U_U611_U625_MY20_Phev_Tx" SG_ 818 Driver_Lock_Sw_Stat 1;
BA_ "U_CX482_CX483_MY20_Tx" SG_ 818 Driver_Lock_Sw_Stat 1;
BA_ "U_U611_U625_MY20_Hev_Tx" SG_ 818 Driver_Lock_Sw_Stat 1;
BA_ "U_U611_U625_MY20_Gas_Tx" SG_ 818 Driver_Lock_Sw_Stat 1;
BA_ "U_C490_MY18_Tx" SG_ 818 Driver_Lock_Sw_Stat 1;
BA_ "U_C519_MY18_5_Gas_Tx" SG_ 818 Driver_Lock_Sw_Stat 1;
BA_ "U_C519_MY18_5_Diesel_Tx" SG_ 818 Driver_Lock_Sw_Stat 1;
BA_ "U_B515_MCA_MY17_Gas_Tx" SG_ 818 Driver_Lock_Sw_Stat 1;
BA_ "U_B515_MCA_MY17_Diesel_Tx" SG_ 818 Driver_Lock_Sw_Stat 1;
BA_ "U_B479_MY17_Diesel_Tx" SG_ 818 Driver_Lock_Sw_Stat 1;
BA_ "U_B479_MY17_Gas_Tx" SG_ 818 Driver_Lock_Sw_Stat 1;
BA_ "U_B479_MY17_Gas_Rx" SG_ 818 Driver_Lock_Sw_Stat 1;
BA_ "GenSigSendType" SG_ 818 Driver_Lock_Sw_Stat 3;
BA_ "WakeupSignal" SG_ 818 Driver_Lock_Sw_Stat 1;
BA_ "U_P702_MY2021_Tx" SG_ 818 Driver_Lock_Sw_Cnt 1;
BA_ "U_CX727_MY2021_Tx" SG_ 818 Driver_Lock_Sw_Cnt 1;
BA_ "U_CX430_MY2021_Tx" SG_ 818 Driver_Lock_Sw_Cnt 1;
BA_ "U_U611_U625_MY20_Phev_Tx" SG_ 818 Driver_Lock_Sw_Cnt 1;
BA_ "U_CX482_CX483_MY20_Tx" SG_ 818 Driver_Lock_Sw_Cnt 1;
BA_ "U_U611_U625_MY20_Hev_Tx" SG_ 818 Driver_Lock_Sw_Cnt 1;
BA_ "U_U611_U625_MY20_Gas_Tx" SG_ 818 Driver_Lock_Sw_Cnt 1;
BA_ "U_C490_MY18_Tx" SG_ 818 Driver_Lock_Sw_Cnt 1;
BA_ "U_C519_MY18_5_Gas_Tx" SG_ 818 Driver_Lock_Sw_Cnt 1;
BA_ "U_C519_MY18_5_Diesel_Tx" SG_ 818 Driver_Lock_Sw_Cnt 1;
BA_ "U_B515_MCA_MY17_Gas_Tx" SG_ 818 Driver_Lock_Sw_Cnt 1;
BA_ "U_B515_MCA_MY17_Diesel_Tx" SG_ 818 Driver_Lock_Sw_Cnt 1;
BA_ "U_B479_MY17_Diesel_Tx" SG_ 818 Driver_Lock_Sw_Cnt 1;
BA_ "U_B479_MY17_Gas_Tx" SG_ 818 Driver_Lock_Sw_Cnt 1;
BA_ "U_B479_MY17_Gas_Rx" SG_ 818 Driver_Lock_Sw_Cnt 1;
BA_ "GenSigSendType" SG_ 818 Driver_Lock_Sw_Cnt 3;
BA_ "MetaData" SG_ 818 Driver_Lock_Sw_Cnt 1;
BA_ "WakeupSignal" SG_ 818 Driver_Lock_Sw_Cnt 1;
BA_ "U_P702_MY2021_Tx" SG_ 818 ChildLckPw_D_Rq 1;
BA_ "U_CX727_MY2021_Tx" SG_ 818 ChildLckPw_D_Rq 1;
BA_ "U_CX430_MY2021_Tx" SG_ 818 ChildLckPw_D_Rq 1;
BA_ "U_U611_U625_MY20_Phev_Tx" SG_ 818 ChildLckPw_D_Rq 1;
BA_ "U_CX482_CX483_MY20_Tx" SG_ 818 ChildLckPw_D_Rq 1;
BA_ "U_U611_U625_MY20_Hev_Tx" SG_ 818 ChildLckPw_D_Rq 1;
BA_ "U_U611_U625_MY20_Gas_Tx" SG_ 818 ChildLckPw_D_Rq 1;
BA_ "U_C490_MY18_Tx" SG_ 818 ChildLckPw_D_Rq 1;
BA_ "U_C519_MY18_5_Gas_Tx" SG_ 818 ChildLckPw_D_Rq 1;
BA_ "U_C519_MY18_5_Diesel_Tx" SG_ 818 ChildLckPw_D_Rq 1;
BA_ "U_B515_MCA_MY17_Gas_Tx" SG_ 818 ChildLckPw_D_Rq 1;
BA_ "U_B515_MCA_MY17_Diesel_Tx" SG_ 818 ChildLckPw_D_Rq 1;
BA_ "U_B479_MY17_Diesel_Tx" SG_ 818 ChildLckPw_D_Rq 1;
BA_ "U_B479_MY17_Gas_Tx" SG_ 818 ChildLckPw_D_Rq 1;
BA_ "U_B479_MY17_Gas_Rx" SG_ 818 ChildLckPw_D_Rq 1;
BA_ "GenSigSendType" SG_ 818 ChildLckPw_D_Rq 3;
BA_ "WakeupSignal" SG_ 818 ChildLckPw_D_Rq 1;
BA_ "U_P702_MY2021_Tx" SG_ 818 ChildLckFdbckRd_B_Stat 1;
BA_ "U_CX727_MY2021_Tx" SG_ 818 ChildLckFdbckRd_B_Stat 1;
BA_ "U_CX430_MY2021_Tx" SG_ 818 ChildLckFdbckRd_B_Stat 1;
BA_ "U_U611_U625_MY20_Phev_Tx" SG_ 818 ChildLckFdbckRd_B_Stat 1;
BA_ "U_CX482_CX483_MY20_Tx" SG_ 818 ChildLckFdbckRd_B_Stat 1;
BA_ "U_U611_U625_MY20_Hev_Tx" SG_ 818 ChildLckFdbckRd_B_Stat 1;
BA_ "U_U611_U625_MY20_Gas_Tx" SG_ 818 ChildLckFdbckRd_B_Stat 1;
BA_ "U_C490_MY18_Tx" SG_ 818 ChildLckFdbckRd_B_Stat 1;
BA_ "U_C519_MY18_5_Gas_Tx" SG_ 818 ChildLckFdbckRd_B_Stat 1;
BA_ "U_C519_MY18_5_Diesel_Tx" SG_ 818 ChildLckFdbckRd_B_Stat 1;
BA_ "U_B515_MCA_MY17_Gas_Tx" SG_ 818 ChildLckFdbckRd_B_Stat 1;
BA_ "U_B515_MCA_MY17_Diesel_Tx" SG_ 818 ChildLckFdbckRd_B_Stat 1;
BA_ "U_B479_MY17_Diesel_Tx" SG_ 818 ChildLckFdbckRd_B_Stat 1;
BA_ "U_B479_MY17_Gas_Tx" SG_ 818 ChildLckFdbckRd_B_Stat 1;
BA_ "U_B479_MY17_Gas_Rx" SG_ 818 ChildLckFdbckRd_B_Stat 1;
BA_ "GenSigSendType" SG_ 818 ChildLckFdbckRd_B_Stat 3;
BA_ "WakeupSignal" SG_ 818 ChildLckFdbckRd_B_Stat 1;
BA_ "U_P702_MY2021_Tx" SG_ 818 RvrseMirrorChime_B_Rq 1;
BA_ "U_CX727_MY2021_Tx" SG_ 818 RvrseMirrorChime_B_Rq 1;
BA_ "U_CX430_MY2021_Tx" SG_ 818 RvrseMirrorChime_B_Rq 1;
BA_ "U_U611_U625_MY20_Phev_Tx" SG_ 818 RvrseMirrorChime_B_Rq 1;
BA_ "U_CX482_CX483_MY20_Tx" SG_ 818 RvrseMirrorChime_B_Rq 1;
BA_ "U_U611_U625_MY20_Hev_Tx" SG_ 818 RvrseMirrorChime_B_Rq 1;
BA_ "U_U611_U625_MY20_Gas_Tx" SG_ 818 RvrseMirrorChime_B_Rq 1;
BA_ "U_C490_MY18_Tx" SG_ 818 RvrseMirrorChime_B_Rq 1;
BA_ "U_C519_MY18_5_Gas_Tx" SG_ 818 RvrseMirrorChime_B_Rq 1;
BA_ "U_C519_MY18_5_Diesel_Tx" SG_ 818 RvrseMirrorChime_B_Rq 1;
BA_ "U_B515_MCA_MY17_Gas_Tx" SG_ 818 RvrseMirrorChime_B_Rq 1;
BA_ "U_B515_MCA_MY17_Diesel_Tx" SG_ 818 RvrseMirrorChime_B_Rq 1;
BA_ "U_B479_MY17_Diesel_Tx" SG_ 818 RvrseMirrorChime_B_Rq 1;
BA_ "U_B479_MY17_Gas_Tx" SG_ 818 RvrseMirrorChime_B_Rq 1;
BA_ "U_P702_MY2021_Rx" SG_ 818 RvrseMirrorChime_B_Rq 1;
BA_ "U_CX727_MY2021_Rx" SG_ 818 RvrseMirrorChime_B_Rq 1;
BA_ "U_CX430_MY2021_Rx" SG_ 818 RvrseMirrorChime_B_Rq 1;
BA_ "U_U611_U625_MY20_Phev_Rx" SG_ 818 RvrseMirrorChime_B_Rq 1;
BA_ "U_CX482_CX483_MY20_Rx" SG_ 818 RvrseMirrorChime_B_Rq 1;
BA_ "U_U611_U625_MY20_Hev_Rx" SG_ 818 RvrseMirrorChime_B_Rq 1;
BA_ "U_U611_U625_MY20_Gas_Rx" SG_ 818 RvrseMirrorChime_B_Rq 1;
BA_ "GenSigSendType" SG_ 818 RvrseMirrorChime_B_Rq 3;
BA_ "CrossOver_InfoCAN" SG_ 818 RvrseMirrorChime_B_Rq 1;
BA_ "U_CX727_MY2021_Rx" SG_ 817 VehLckInd_D_Rq 1;
BA_ "U_C490_MY18_Rx" SG_ 817 VehLckInd_D_Rq 1;
BA_ "U_P702_MY2021_Rx" SG_ 817 VehLckInd_D_Rq 1;
BA_ "U_CX430_MY2021_Rx" SG_ 817 VehLckInd_D_Rq 1;
BA_ "U_U611_U625_MY20_Phev_Rx" SG_ 817 VehLckInd_D_Rq 1;
BA_ "U_CX482_CX483_MY20_Rx" SG_ 817 VehLckInd_D_Rq 1;
BA_ "U_U611_U625_MY20_Hev_Rx" SG_ 817 VehLckInd_D_Rq 1;
BA_ "U_U611_U625_MY20_Gas_Rx" SG_ 817 VehLckInd_D_Rq 1;
BA_ "U_C519_MY18_5_Gas_Rx" SG_ 817 VehLckInd_D_Rq 1;
BA_ "U_C519_MY18_5_Diesel_Rx" SG_ 817 VehLckInd_D_Rq 1;
BA_ "U_B515_MCA_MY17_Gas_Rx" SG_ 817 VehLckInd_D_Rq 1;
BA_ "U_B515_MCA_MY17_Diesel_Rx" SG_ 817 VehLckInd_D_Rq 1;
BA_ "U_B479_MY17_Diesel_Rx" SG_ 817 VehLckInd_D_Rq 1;
BA_ "U_B479_MY17_Gas_Rx" SG_ 817 VehLckInd_D_Rq 1;
BA_ "U_CX727_MY2021_Rx" SG_ 817 DrTgateOpen_B_Rq 1;
BA_ "U_U611_U625_MY20_Phev_Rx" SG_ 817 DrTgateOpen_B_Rq 1;
BA_ "U_CX482_CX483_MY20_Rx" SG_ 817 DrTgateOpen_B_Rq 1;
BA_ "U_U611_U625_MY20_Hev_Rx" SG_ 817 DrTgateOpen_B_Rq 1;
BA_ "U_U611_U625_MY20_Gas_Rx" SG_ 817 DrTgateOpen_B_Rq 1;
BA_ "U_C519_MY18_5_Gas_Rx" SG_ 817 DrTgateOpen_B_Rq 1;
BA_ "U_C519_MY18_5_Diesel_Rx" SG_ 817 DrTgateOpen_B_Rq 1;
BA_ "WakeupSignal" SG_ 817 DrTgateOpen_B_Rq 1;
BA_ "U_CX727_MY2021_Rx" SG_ 817 DrTgateExtSwMde_B_Stat 1;
BA_ "U_U611_U625_MY20_Phev_Rx" SG_ 817 DrTgateExtSwMde_B_Stat 1;
BA_ "U_CX482_CX483_MY20_Rx" SG_ 817 DrTgateExtSwMde_B_Stat 1;
BA_ "U_U611_U625_MY20_Hev_Rx" SG_ 817 DrTgateExtSwMde_B_Stat 1;
BA_ "U_U611_U625_MY20_Gas_Rx" SG_ 817 DrTgateExtSwMde_B_Stat 1;
BA_ "U_C519_MY18_5_Gas_Rx" SG_ 817 DrTgateExtSwMde_B_Stat 1;
BA_ "U_C519_MY18_5_Diesel_Rx" SG_ 817 DrTgateExtSwMde_B_Stat 1;
BA_ "WakeupSignal" SG_ 817 DrTgateExtSwMde_B_Stat 1;
BA_ "U_P702_MY2021_Rx" SG_ 817 Remote_Device_Feedback 1;
BA_ "U_CX727_MY2021_Rx" SG_ 817 Remote_Device_Feedback 1;
BA_ "U_VN127_MY20_Rx" SG_ 817 Remote_Device_Feedback 1;
BA_ "U_H567_MY20_Rx" SG_ 817 Remote_Device_Feedback 1;
BA_ "U_CX430_MY2021_Rx" SG_ 817 Remote_Device_Feedback 1;
BA_ "U_U611_U625_MY20_Phev_Rx" SG_ 817 Remote_Device_Feedback 1;
BA_ "U_CX482_CX483_MY20_Rx" SG_ 817 Remote_Device_Feedback 1;
BA_ "U_U611_U625_MY20_Hev_Rx" SG_ 817 Remote_Device_Feedback 1;
BA_ "U_U611_U625_MY20_Gas_Rx" SG_ 817 Remote_Device_Feedback 1;
BA_ "U_C519_MY18_5_Gas_Rx" SG_ 817 Remote_Device_Feedback 1;
BA_ "U_C519_MY18_5_Diesel_Rx" SG_ 817 Remote_Device_Feedback 1;
BA_ "U_B515_MCA_MY17_Gas_Rx" SG_ 817 Remote_Device_Feedback 1;
BA_ "U_B515_MCA_MY17_Diesel_Rx" SG_ 817 Remote_Device_Feedback 1;
BA_ "U_B479_MY17_Diesel_Rx" SG_ 817 Remote_Device_Feedback 1;
BA_ "U_B479_MY17_Gas_Rx" SG_ 817 Remote_Device_Feedback 1;
BA_ "WakeupSignal" SG_ 817 Remote_Device_Feedback 1;
BA_ "U_CX727_MY2021_Rx" SG_ 817 Power_Liftgate_Rqst 1;
BA_ "U_U611_U625_MY20_Phev_Rx" SG_ 817 Power_Liftgate_Rqst 1;
BA_ "U_CX482_CX483_MY20_Rx" SG_ 817 Power_Liftgate_Rqst 1;
BA_ "U_U611_U625_MY20_Hev_Rx" SG_ 817 Power_Liftgate_Rqst 1;
BA_ "U_U611_U625_MY20_Gas_Rx" SG_ 817 Power_Liftgate_Rqst 1;
BA_ "U_C519_MY18_5_Gas_Rx" SG_ 817 Power_Liftgate_Rqst 1;
BA_ "U_C519_MY18_5_Diesel_Rx" SG_ 817 Power_Liftgate_Rqst 1;
BA_ "WakeupSignal" SG_ 817 Power_Liftgate_Rqst 1;
BA_ "U_CX727_MY2021_Rx" SG_ 817 Power_Decklid_Rqst 1;
BA_ "U_U611_U625_MY20_Phev_Rx" SG_ 817 Power_Decklid_Rqst 1;
BA_ "U_CX482_CX483_MY20_Rx" SG_ 817 Power_Decklid_Rqst 1;
BA_ "U_U611_U625_MY20_Hev_Rx" SG_ 817 Power_Decklid_Rqst 1;
BA_ "U_U611_U625_MY20_Gas_Rx" SG_ 817 Power_Decklid_Rqst 1;
BA_ "U_C519_MY18_5_Gas_Rx" SG_ 817 Power_Decklid_Rqst 1;
BA_ "U_C519_MY18_5_Diesel_Rx" SG_ 817 Power_Decklid_Rqst 1;
BA_ "WakeupSignal" SG_ 817 Power_Decklid_Rqst 1;
BA_ "U_CX727_MY2021_Rx" SG_ 817 Keyfob_Pad_Msg_Count 1;
BA_ "U_U611_U625_MY20_Phev_Rx" SG_ 817 Keyfob_Pad_Msg_Count 1;
BA_ "U_CX482_CX483_MY20_Rx" SG_ 817 Keyfob_Pad_Msg_Count 1;
BA_ "U_U611_U625_MY20_Hev_Rx" SG_ 817 Keyfob_Pad_Msg_Count 1;
BA_ "U_U611_U625_MY20_Gas_Rx" SG_ 817 Keyfob_Pad_Msg_Count 1;
BA_ "U_C519_MY18_5_Gas_Rx" SG_ 817 Keyfob_Pad_Msg_Count 1;
BA_ "U_C519_MY18_5_Diesel_Rx" SG_ 817 Keyfob_Pad_Msg_Count 1;
BA_ "WakeupSignal" SG_ 817 Keyfob_Pad_Msg_Count 1;
BA_ "GenSigSendType" SG_ 817 Veh_Lock_Requestor 3;
BA_ "U_CX727_MY2021_Rx" SG_ 817 Veh_Lock_Requestor 1;
BA_ "U_P702_MY2021_Rx" SG_ 817 Veh_Lock_Requestor 1;
BA_ "U_CX430_MY2021_Rx" SG_ 817 Veh_Lock_Requestor 1;
BA_ "U_U611_U625_MY20_Phev_Rx" SG_ 817 Veh_Lock_Requestor 1;
BA_ "U_CX482_CX483_MY20_Rx" SG_ 817 Veh_Lock_Requestor 1;
BA_ "U_U611_U625_MY20_Hev_Rx" SG_ 817 Veh_Lock_Requestor 1;
BA_ "U_U611_U625_MY20_Gas_Rx" SG_ 817 Veh_Lock_Requestor 1;
BA_ "U_C490_MY18_Rx" SG_ 817 Veh_Lock_Requestor 1;
BA_ "U_C519_MY18_5_Gas_Rx" SG_ 817 Veh_Lock_Requestor 1;
BA_ "U_C519_MY18_5_Diesel_Rx" SG_ 817 Veh_Lock_Requestor 1;
BA_ "U_B515_MCA_MY17_Gas_Rx" SG_ 817 Veh_Lock_Requestor 1;
BA_ "U_B515_MCA_MY17_Diesel_Rx" SG_ 817 Veh_Lock_Requestor 1;
BA_ "U_B479_MY17_Diesel_Rx" SG_ 817 Veh_Lock_Requestor 1;
BA_ "U_B479_MY17_Gas_Rx" SG_ 817 Veh_Lock_Requestor 1;
BA_ "WakeupSignal" SG_ 817 Veh_Lock_Requestor 1;
BA_ "GenSigSendType" SG_ 817 Veh_Lock_EvNum 3;
BA_ "U_CX727_MY2021_Rx" SG_ 817 Veh_Lock_EvNum 1;
BA_ "U_P702_MY2021_Rx" SG_ 817 Veh_Lock_EvNum 1;
BA_ "U_CX430_MY2021_Rx" SG_ 817 Veh_Lock_EvNum 1;
BA_ "U_U611_U625_MY20_Phev_Rx" SG_ 817 Veh_Lock_EvNum 1;
BA_ "U_CX482_CX483_MY20_Rx" SG_ 817 Veh_Lock_EvNum 1;
BA_ "U_U611_U625_MY20_Hev_Rx" SG_ 817 Veh_Lock_EvNum 1;
BA_ "U_U611_U625_MY20_Gas_Rx" SG_ 817 Veh_Lock_EvNum 1;
BA_ "U_C490_MY18_Rx" SG_ 817 Veh_Lock_EvNum 1;
BA_ "U_C519_MY18_5_Gas_Rx" SG_ 817 Veh_Lock_EvNum 1;
BA_ "U_C519_MY18_5_Diesel_Rx" SG_ 817 Veh_Lock_EvNum 1;
BA_ "U_B515_MCA_MY17_Gas_Rx" SG_ 817 Veh_Lock_EvNum 1;
BA_ "U_B515_MCA_MY17_Diesel_Rx" SG_ 817 Veh_Lock_EvNum 1;
BA_ "U_B479_MY17_Diesel_Rx" SG_ 817 Veh_Lock_EvNum 1;
BA_ "U_B479_MY17_Gas_Rx" SG_ 817 Veh_Lock_EvNum 1;
BA_ "WakeupSignal" SG_ 817 Veh_Lock_EvNum 1;
BA_ "U_CX727_MY2021_Rx" SG_ 817 Veh_Lock_Sub_Id 1;
BA_ "U_CX430_MY2021_Rx" SG_ 817 Veh_Lock_Sub_Id 1;
BA_ "U_U611_U625_MY20_Phev_Rx" SG_ 817 Veh_Lock_Sub_Id 1;
BA_ "U_CX482_CX483_MY20_Rx" SG_ 817 Veh_Lock_Sub_Id 1;
BA_ "U_U611_U625_MY20_Hev_Rx" SG_ 817 Veh_Lock_Sub_Id 1;
BA_ "U_U611_U625_MY20_Gas_Rx" SG_ 817 Veh_Lock_Sub_Id 1;
BA_ "U_C490_MY18_Rx" SG_ 817 Veh_Lock_Sub_Id 1;
BA_ "U_C519_MY18_5_Gas_Rx" SG_ 817 Veh_Lock_Sub_Id 1;
BA_ "U_C519_MY18_5_Diesel_Rx" SG_ 817 Veh_Lock_Sub_Id 1;
BA_ "U_B515_MCA_MY17_Gas_Rx" SG_ 817 Veh_Lock_Sub_Id 1;
BA_ "U_B515_MCA_MY17_Diesel_Rx" SG_ 817 Veh_Lock_Sub_Id 1;
BA_ "U_B479_MY17_Diesel_Rx" SG_ 817 Veh_Lock_Sub_Id 1;
BA_ "U_B479_MY17_Gas_Rx" SG_ 817 Veh_Lock_Sub_Id 1;
BA_ "U_P702_MY2021_Rx" SG_ 817 ChildLck_D_Dsply 1;
BA_ "U_CX727_MY2021_Rx" SG_ 817 ChildLck_D_Dsply 1;
BA_ "U_CX430_MY2021_Rx" SG_ 817 ChildLck_D_Dsply 1;
BA_ "U_U611_U625_MY20_Phev_Rx" SG_ 817 ChildLck_D_Dsply 1;
BA_ "U_CX482_CX483_MY20_Rx" SG_ 817 ChildLck_D_Dsply 1;
BA_ "U_U611_U625_MY20_Hev_Rx" SG_ 817 ChildLck_D_Dsply 1;
BA_ "U_U611_U625_MY20_Gas_Rx" SG_ 817 ChildLck_D_Dsply 1;
BA_ "U_C490_MY18_Rx" SG_ 817 ChildLck_D_Dsply 1;
BA_ "U_C519_MY18_5_Gas_Rx" SG_ 817 ChildLck_D_Dsply 1;
BA_ "U_C519_MY18_5_Diesel_Rx" SG_ 817 ChildLck_D_Dsply 1;
BA_ "U_B515_MCA_MY17_Gas_Rx" SG_ 817 ChildLck_D_Dsply 1;
BA_ "U_B515_MCA_MY17_Diesel_Rx" SG_ 817 ChildLck_D_Dsply 1;
BA_ "U_B479_MY17_Diesel_Rx" SG_ 817 ChildLck_D_Dsply 1;
BA_ "U_B479_MY17_Gas_Rx" SG_ 817 ChildLck_D_Dsply 1;
BA_ "GenSigStartValue" SG_ 817 ChildLck_D_Dsply 1;
BA_ "GenSigStartValueInteger" SG_ 817 ChildLck_D_Dsply 1;
BA_ "WakeupSignal" SG_ 817 ChildLck_D_Dsply 1;
BA_ "U_P702_MY2021_Rx" SG_ 817 RollCodeUnlock 1;
BA_ "U_CX727_MY2021_Rx" SG_ 817 RollCodeUnlock 1;
BA_ "U_CX430_MY2021_Rx" SG_ 817 RollCodeUnlock 1;
BA_ "U_U611_U625_MY20_Phev_Rx" SG_ 817 RollCodeUnlock 1;
BA_ "U_CX482_CX483_MY20_Rx" SG_ 817 RollCodeUnlock 1;
BA_ "U_U611_U625_MY20_Hev_Rx" SG_ 817 RollCodeUnlock 1;
BA_ "U_U611_U625_MY20_Gas_Rx" SG_ 817 RollCodeUnlock 1;
BA_ "U_C490_MY18_Rx" SG_ 817 RollCodeUnlock 1;
BA_ "U_C519_MY18_5_Gas_Rx" SG_ 817 RollCodeUnlock 1;
BA_ "U_C519_MY18_5_Diesel_Rx" SG_ 817 RollCodeUnlock 1;
BA_ "U_B515_MCA_MY17_Gas_Rx" SG_ 817 RollCodeUnlock 1;
BA_ "U_B515_MCA_MY17_Diesel_Rx" SG_ 817 RollCodeUnlock 1;
BA_ "U_B479_MY17_Diesel_Rx" SG_ 817 RollCodeUnlock 1;
BA_ "U_B479_MY17_Gas_Rx" SG_ 817 RollCodeUnlock 1;
BA_ "CrossOver_InfoCAN" SG_ 817 RollCodeUnlock 1;
BA_ "CrossOver_InfoCAN" SG_ 817 Lockmsgtxt_D_Rq 1;
BA_ "WakeupSignal" SG_ 817 Lockmsgtxt_D_Rq 1;
BA_ "U_CX727_MY2021_Rx" SG_ 817 LockInhibit 1;
BA_ "U_U611_U625_MY20_Phev_Rx" SG_ 817 LockInhibit 1;
BA_ "U_CX482_CX483_MY20_Rx" SG_ 817 LockInhibit 1;
BA_ "U_U611_U625_MY20_Hev_Rx" SG_ 817 LockInhibit 1;
BA_ "U_U611_U625_MY20_Gas_Rx" SG_ 817 LockInhibit 1;
BA_ "U_C519_MY18_5_Gas_Rx" SG_ 817 LockInhibit 1;
BA_ "U_C519_MY18_5_Diesel_Rx" SG_ 817 LockInhibit 1;
BA_ "WakeupSignal" SG_ 817 LockInhibit 1;
BA_ "GenSigSendType" SG_ 817 Veh_Lock_Status 3;
BA_ "U_CX727_MY2021_Rx" SG_ 817 Veh_Lock_Status 1;
BA_ "U_P702_MY2021_Rx" SG_ 817 Veh_Lock_Status 1;
BA_ "U_CX430_MY2021_Rx" SG_ 817 Veh_Lock_Status 1;
BA_ "U_U611_U625_MY20_Phev_Rx" SG_ 817 Veh_Lock_Status 1;
BA_ "U_CX482_CX483_MY20_Rx" SG_ 817 Veh_Lock_Status 1;
BA_ "U_U611_U625_MY20_Hev_Rx" SG_ 817 Veh_Lock_Status 1;
BA_ "U_U611_U625_MY20_Gas_Rx" SG_ 817 Veh_Lock_Status 1;
BA_ "U_C490_MY18_Rx" SG_ 817 Veh_Lock_Status 1;
BA_ "U_C519_MY18_5_Gas_Rx" SG_ 817 Veh_Lock_Status 1;
BA_ "U_C519_MY18_5_Diesel_Rx" SG_ 817 Veh_Lock_Status 1;
BA_ "U_B515_MCA_MY17_Gas_Rx" SG_ 817 Veh_Lock_Status 1;
BA_ "U_B515_MCA_MY17_Diesel_Rx" SG_ 817 Veh_Lock_Status 1;
BA_ "U_B479_MY17_Diesel_Rx" SG_ 817 Veh_Lock_Status 1;
BA_ "U_B479_MY17_Gas_Rx" SG_ 817 Veh_Lock_Status 1;
BA_ "GenSigStartValue" SG_ 817 Veh_Lock_Status 1;
BA_ "GenSigStartValueInteger" SG_ 817 Veh_Lock_Status 1;
BA_ "WakeupSignal" SG_ 817 Veh_Lock_Status 1;
BA_ "U_P702_MY2021_Rx" SG_ 817 FobComm_D_Stat 1;
BA_ "U_CX727_MY2021_Rx" SG_ 817 FobComm_D_Stat 1;
BA_ "U_VN127_MY20_Rx" SG_ 817 FobComm_D_Stat 1;
BA_ "U_H567_MY20_Rx" SG_ 817 FobComm_D_Stat 1;
BA_ "U_CX430_MY2021_Rx" SG_ 817 FobComm_D_Stat 1;
BA_ "U_U611_U625_MY20_Phev_Rx" SG_ 817 FobComm_D_Stat 1;
BA_ "U_CX482_CX483_MY20_Rx" SG_ 817 FobComm_D_Stat 1;
BA_ "U_U611_U625_MY20_Hev_Rx" SG_ 817 FobComm_D_Stat 1;
BA_ "U_U611_U625_MY20_Gas_Rx" SG_ 817 FobComm_D_Stat 1;
BA_ "U_C519_MY18_5_Gas_Rx" SG_ 817 FobComm_D_Stat 1;
BA_ "U_C519_MY18_5_Diesel_Rx" SG_ 817 FobComm_D_Stat 1;
BA_ "U_B515_MCA_MY17_Gas_Rx" SG_ 817 FobComm_D_Stat 1;
BA_ "U_B515_MCA_MY17_Diesel_Rx" SG_ 817 FobComm_D_Stat 1;
BA_ "U_B479_MY17_Diesel_Rx" SG_ 817 FobComm_D_Stat 1;
BA_ "U_B479_MY17_Gas_Rx" SG_ 817 FobComm_D_Stat 1;
BA_ "U_P702_MY2021_Rx" SG_ 817 WindowLockout_B_Stat 1;
BA_ "U_CX727_MY2021_Rx" SG_ 817 WindowLockout_B_Stat 1;
BA_ "U_CX430_MY2021_Rx" SG_ 817 WindowLockout_B_Stat 1;
BA_ "U_U611_U625_MY20_Phev_Rx" SG_ 817 WindowLockout_B_Stat 1;
BA_ "U_CX482_CX483_MY20_Rx" SG_ 817 WindowLockout_B_Stat 1;
BA_ "U_U611_U625_MY20_Hev_Rx" SG_ 817 WindowLockout_B_Stat 1;
BA_ "U_U611_U625_MY20_Gas_Rx" SG_ 817 WindowLockout_B_Stat 1;
BA_ "U_C490_MY18_Rx" SG_ 817 WindowLockout_B_Stat 1;
BA_ "U_C519_MY18_5_Gas_Rx" SG_ 817 WindowLockout_B_Stat 1;
BA_ "U_C519_MY18_5_Diesel_Rx" SG_ 817 WindowLockout_B_Stat 1;
BA_ "U_B515_MCA_MY17_Gas_Rx" SG_ 817 WindowLockout_B_Stat 1;
BA_ "U_B515_MCA_MY17_Diesel_Rx" SG_ 817 WindowLockout_B_Stat 1;
BA_ "U_B479_MY17_Diesel_Rx" SG_ 817 WindowLockout_B_Stat 1;
BA_ "U_B479_MY17_Gas_Rx" SG_ 817 WindowLockout_B_Stat 1;
BA_ "U_CX430_MY2021_Tx" SG_ 1091 TowBarMsgTxt_D_Rq 1;
BA_ "U_U611_U625_MY20_Phev_Tx" SG_ 1091 TowBarMsgTxt_D_Rq 1;
BA_ "U_CX482_CX483_MY20_Tx" SG_ 1091 TowBarMsgTxt_D_Rq 1;
BA_ "U_U611_U625_MY20_Gas_Tx" SG_ 1091 TowBarMsgTxt_D_Rq 1;
BA_ "U_C519_MY18_5_Gas_Tx" SG_ 1091 TowBarMsgTxt_D_Rq 1;
BA_ "U_C519_MY18_5_Diesel_Tx" SG_ 1091 TowBarMsgTxt_D_Rq 1;
BA_ "U_B515_MCA_MY17_Gas_Tx" SG_ 1091 TowBarMsgTxt_D_Rq 1;
BA_ "U_B515_MCA_MY17_Diesel_Tx" SG_ 1091 TowBarMsgTxt_D_Rq 1;
BA_ "U_B479_MY17_Diesel_Tx" SG_ 1091 TowBarMsgTxt_D_Rq 1;
BA_ "U_B479_MY17_Gas_Tx" SG_ 1091 TowBarMsgTxt_D_Rq 1;
BA_ "GenSigSendType" SG_ 1091 TowBarMsgTxt_D_Rq 3;
BA_ "U_P702_MY2021_Tx" SG_ 1091 ParkLampTrlrOut_B_Stat 1;
BA_ "U_CX430_MY2021_Tx" SG_ 1091 ParkLampTrlrOut_B_Stat 1;
BA_ "U_U611_U625_MY20_Phev_Tx" SG_ 1091 ParkLampTrlrOut_B_Stat 1;
BA_ "U_CX482_CX483_MY20_Tx" SG_ 1091 ParkLampTrlrOut_B_Stat 1;
BA_ "U_U611_U625_MY20_Gas_Tx" SG_ 1091 ParkLampTrlrOut_B_Stat 1;
BA_ "U_C519_MY18_5_Gas_Tx" SG_ 1091 ParkLampTrlrOut_B_Stat 1;
BA_ "U_C519_MY18_5_Diesel_Tx" SG_ 1091 ParkLampTrlrOut_B_Stat 1;
BA_ "U_B515_MCA_MY17_Gas_Tx" SG_ 1091 ParkLampTrlrOut_B_Stat 1;
BA_ "U_B515_MCA_MY17_Diesel_Tx" SG_ 1091 ParkLampTrlrOut_B_Stat 1;
BA_ "U_B479_MY17_Diesel_Tx" SG_ 1091 ParkLampTrlrOut_B_Stat 1;
BA_ "U_B479_MY17_Gas_Tx" SG_ 1091 ParkLampTrlrOut_B_Stat 1;
BA_ "GenSigSendType" SG_ 1091 ParkLampTrlrOut_B_Stat 3;
BA_ "CrossOver_InfoCAN" SG_ 1091 ParkLampTrlrOut_B_Stat 1;
BA_ "U_P702_MY2021_Tx" SG_ 1091 TrlrLampCtl_D_Stat 1;
BA_ "U_CX430_MY2021_Tx" SG_ 1091 TrlrLampCtl_D_Stat 1;
BA_ "U_U611_U625_MY20_Phev_Tx" SG_ 1091 TrlrLampCtl_D_Stat 1;
BA_ "U_CX482_CX483_MY20_Tx" SG_ 1091 TrlrLampCtl_D_Stat 1;
BA_ "U_U611_U625_MY20_Gas_Tx" SG_ 1091 TrlrLampCtl_D_Stat 1;
BA_ "U_C519_MY18_5_Gas_Tx" SG_ 1091 TrlrLampCtl_D_Stat 1;
BA_ "U_C519_MY18_5_Diesel_Tx" SG_ 1091 TrlrLampCtl_D_Stat 1;
BA_ "U_B515_MCA_MY17_Gas_Tx" SG_ 1091 TrlrLampCtl_D_Stat 1;
BA_ "U_B515_MCA_MY17_Diesel_Tx" SG_ 1091 TrlrLampCtl_D_Stat 1;
BA_ "U_B479_MY17_Diesel_Tx" SG_ 1091 TrlrLampCtl_D_Stat 1;
BA_ "U_B479_MY17_Gas_Tx" SG_ 1091 TrlrLampCtl_D_Stat 1;
BA_ "GenSigSendType" SG_ 1091 TrlrLampCtl_D_Stat 3;
BA_ "CrossOver_InfoCAN" SG_ 1091 TrlrLampCtl_D_Stat 1;
BA_ "U_P702_MY2021_Tx" SG_ 1091 TrlrBattChrg_D_Stat 1;
BA_ "U_CX430_MY2021_Tx" SG_ 1091 TrlrBattChrg_D_Stat 1;
BA_ "U_U611_U625_MY20_Phev_Tx" SG_ 1091 TrlrBattChrg_D_Stat 1;
BA_ "U_CX482_CX483_MY20_Tx" SG_ 1091 TrlrBattChrg_D_Stat 1;
BA_ "U_U611_U625_MY20_Gas_Tx" SG_ 1091 TrlrBattChrg_D_Stat 1;
BA_ "U_C519_MY18_5_Gas_Tx" SG_ 1091 TrlrBattChrg_D_Stat 1;
BA_ "U_C519_MY18_5_Diesel_Tx" SG_ 1091 TrlrBattChrg_D_Stat 1;
BA_ "U_B515_MCA_MY17_Gas_Tx" SG_ 1091 TrlrBattChrg_D_Stat 1;
BA_ "U_B515_MCA_MY17_Diesel_Tx" SG_ 1091 TrlrBattChrg_D_Stat 1;
BA_ "U_B479_MY17_Diesel_Tx" SG_ 1091 TrlrBattChrg_D_Stat 1;
BA_ "U_B479_MY17_Gas_Tx" SG_ 1091 TrlrBattChrg_D_Stat 1;
BA_ "GenSigSendType" SG_ 1091 TrlrBattChrg_D_Stat 3;
BA_ "CrossOver_InfoCAN" SG_ 1091 TrlrBattChrg_D_Stat 1;
BA_ "U_P702_MY2021_Tx" SG_ 1091 StopLampTrlrOut_B_Stat 1;
BA_ "U_CX430_MY2021_Tx" SG_ 1091 StopLampTrlrOut_B_Stat 1;
BA_ "U_U611_U625_MY20_Phev_Tx" SG_ 1091 StopLampTrlrOut_B_Stat 1;
BA_ "U_CX482_CX483_MY20_Tx" SG_ 1091 StopLampTrlrOut_B_Stat 1;
BA_ "U_U611_U625_MY20_Gas_Tx" SG_ 1091 StopLampTrlrOut_B_Stat 1;
BA_ "U_C519_MY18_5_Gas_Tx" SG_ 1091 StopLampTrlrOut_B_Stat 1;
BA_ "U_C519_MY18_5_Diesel_Tx" SG_ 1091 StopLampTrlrOut_B_Stat 1;
BA_ "U_B515_MCA_MY17_Gas_Tx" SG_ 1091 StopLampTrlrOut_B_Stat 1;
BA_ "U_B515_MCA_MY17_Diesel_Tx" SG_ 1091 StopLampTrlrOut_B_Stat 1;
BA_ "U_B479_MY17_Diesel_Tx" SG_ 1091 StopLampTrlrOut_B_Stat 1;
BA_ "U_B479_MY17_Gas_Tx" SG_ 1091 StopLampTrlrOut_B_Stat 1;
BA_ "GenSigSendType" SG_ 1091 StopLampTrlrOut_B_Stat 3;
BA_ "CrossOver_InfoCAN" SG_ 1091 StopLampTrlrOut_B_Stat 1;
BA_ "U_P702_MY2021_Tx" SG_ 1091 TurnLampTrlrRr_B_Stat 1;
BA_ "U_CX430_MY2021_Tx" SG_ 1091 TurnLampTrlrRr_B_Stat 1;
BA_ "U_U611_U625_MY20_Phev_Tx" SG_ 1091 TurnLampTrlrRr_B_Stat 1;
BA_ "U_CX482_CX483_MY20_Tx" SG_ 1091 TurnLampTrlrRr_B_Stat 1;
BA_ "U_U611_U625_MY20_Gas_Tx" SG_ 1091 TurnLampTrlrRr_B_Stat 1;
BA_ "U_C519_MY18_5_Gas_Tx" SG_ 1091 TurnLampTrlrRr_B_Stat 1;
BA_ "U_C519_MY18_5_Diesel_Tx" SG_ 1091 TurnLampTrlrRr_B_Stat 1;
BA_ "U_B515_MCA_MY17_Gas_Tx" SG_ 1091 TurnLampTrlrRr_B_Stat 1;
BA_ "U_B515_MCA_MY17_Diesel_Tx" SG_ 1091 TurnLampTrlrRr_B_Stat 1;
BA_ "U_B479_MY17_Diesel_Tx" SG_ 1091 TurnLampTrlrRr_B_Stat 1;
BA_ "U_B479_MY17_Gas_Tx" SG_ 1091 TurnLampTrlrRr_B_Stat 1;
BA_ "GenSigSendType" SG_ 1091 TurnLampTrlrRr_B_Stat 3;
BA_ "CrossOver_InfoCAN" SG_ 1091 TurnLampTrlrRr_B_Stat 1;
BA_ "U_P702_MY2021_Tx" SG_ 1091 TurnLampTrlrRl_B_Stat 1;
BA_ "U_CX430_MY2021_Tx" SG_ 1091 TurnLampTrlrRl_B_Stat 1;
BA_ "U_U611_U625_MY20_Phev_Tx" SG_ 1091 TurnLampTrlrRl_B_Stat 1;
BA_ "U_CX482_CX483_MY20_Tx" SG_ 1091 TurnLampTrlrRl_B_Stat 1;
BA_ "U_U611_U625_MY20_Gas_Tx" SG_ 1091 TurnLampTrlrRl_B_Stat 1;
BA_ "U_C519_MY18_5_Gas_Tx" SG_ 1091 TurnLampTrlrRl_B_Stat 1;
BA_ "U_C519_MY18_5_Diesel_Tx" SG_ 1091 TurnLampTrlrRl_B_Stat 1;
BA_ "U_B515_MCA_MY17_Gas_Tx" SG_ 1091 TurnLampTrlrRl_B_Stat 1;
BA_ "U_B515_MCA_MY17_Diesel_Tx" SG_ 1091 TurnLampTrlrRl_B_Stat 1;
BA_ "U_B479_MY17_Diesel_Tx" SG_ 1091 TurnLampTrlrRl_B_Stat 1;
BA_ "U_B479_MY17_Gas_Tx" SG_ 1091 TurnLampTrlrRl_B_Stat 1;
BA_ "GenSigSendType" SG_ 1091 TurnLampTrlrRl_B_Stat 3;
BA_ "CrossOver_InfoCAN" SG_ 1091 TurnLampTrlrRl_B_Stat 1;
BA_ "U_P702_MY2021_Tx" SG_ 1091 TrlrLampCnnct_B_Actl 1;
BA_ "U_CX430_MY2021_Tx" SG_ 1091 TrlrLampCnnct_B_Actl 1;
BA_ "U_U611_U625_MY20_Phev_Tx" SG_ 1091 TrlrLampCnnct_B_Actl 1;
BA_ "U_CX482_CX483_MY20_Tx" SG_ 1091 TrlrLampCnnct_B_Actl 1;
BA_ "U_U611_U625_MY20_Gas_Tx" SG_ 1091 TrlrLampCnnct_B_Actl 1;
BA_ "U_C519_MY18_5_Gas_Tx" SG_ 1091 TrlrLampCnnct_B_Actl 1;
BA_ "U_C519_MY18_5_Diesel_Tx" SG_ 1091 TrlrLampCnnct_B_Actl 1;
BA_ "U_B515_MCA_MY17_Gas_Tx" SG_ 1091 TrlrLampCnnct_B_Actl 1;
BA_ "U_B515_MCA_MY17_Diesel_Tx" SG_ 1091 TrlrLampCnnct_B_Actl 1;
BA_ "U_B479_MY17_Diesel_Tx" SG_ 1091 TrlrLampCnnct_B_Actl 1;
BA_ "U_B479_MY17_Gas_Tx" SG_ 1091 TrlrLampCnnct_B_Actl 1;
BA_ "GenSigSendType" SG_ 1091 TrlrLampCnnct_B_Actl 3;
BA_ "CrossOver_InfoCAN" SG_ 1091 TrlrLampCnnct_B_Actl 1;
BA_ "U_P702_MY2021_Tx" SG_ 1865 TesterPhysicalResPDM 1;
BA_ "U_CX430_MY2021_Tx" SG_ 1865 TesterPhysicalResPDM 1;
BA_ "U_U611_U625_MY20_Phev_Tx" SG_ 1865 TesterPhysicalResPDM 1;
BA_ "U_CX482_CX483_MY20_Tx" SG_ 1865 TesterPhysicalResPDM 1;
BA_ "U_U611_U625_MY20_Hev_Tx" SG_ 1865 TesterPhysicalResPDM 1;
BA_ "U_U611_U625_MY20_Gas_Tx" SG_ 1865 TesterPhysicalResPDM 1;
BA_ "U_C490_MY18_Tx" SG_ 1865 TesterPhysicalResPDM 1;
BA_ "U_C519_MY18_5_Gas_Tx" SG_ 1865 TesterPhysicalResPDM 1;
BA_ "U_C519_MY18_5_Diesel_Tx" SG_ 1865 TesterPhysicalResPDM 1;
BA_ "U_B515_MCA_MY17_Gas_Tx" SG_ 1865 TesterPhysicalResPDM 1;
BA_ "U_B515_MCA_MY17_Diesel_Tx" SG_ 1865 TesterPhysicalResPDM 1;
BA_ "U_B479_MY17_Diesel_Tx" SG_ 1865 TesterPhysicalResPDM 1;
BA_ "U_B479_MY17_Gas_Tx" SG_ 1865 TesterPhysicalResPDM 1;
BA_ "GenSigSendType" SG_ 1865 TesterPhysicalResPDM 3;
BA_ "U_P702_MY2021_Rx" SG_ 1857 TesterPhysicalReqPDM 1;
BA_ "U_CX430_MY2021_Rx" SG_ 1857 TesterPhysicalReqPDM 1;
BA_ "U_U611_U625_MY20_Phev_Rx" SG_ 1857 TesterPhysicalReqPDM 1;
BA_ "U_CX482_CX483_MY20_Rx" SG_ 1857 TesterPhysicalReqPDM 1;
BA_ "U_U611_U625_MY20_Hev_Rx" SG_ 1857 TesterPhysicalReqPDM 1;
BA_ "U_U611_U625_MY20_Gas_Rx" SG_ 1857 TesterPhysicalReqPDM 1;
BA_ "U_C490_MY18_Rx" SG_ 1857 TesterPhysicalReqPDM 1;
BA_ "U_C519_MY18_5_Gas_Rx" SG_ 1857 TesterPhysicalReqPDM 1;
BA_ "U_C519_MY18_5_Diesel_Rx" SG_ 1857 TesterPhysicalReqPDM 1;
BA_ "U_B515_MCA_MY17_Gas_Rx" SG_ 1857 TesterPhysicalReqPDM 1;
BA_ "U_B515_MCA_MY17_Diesel_Rx" SG_ 1857 TesterPhysicalReqPDM 1;
BA_ "U_B479_MY17_Diesel_Rx" SG_ 1857 TesterPhysicalReqPDM 1;
BA_ "U_B479_MY17_Gas_Rx" SG_ 1857 TesterPhysicalReqPDM 1;
BA_ "GenSigSendType" SG_ 1857 TesterPhysicalReqPDM 3;
BA_ "U_P702_MY2021_Tx" SG_ 1819 TesterPhysicalResSCMH 1;
BA_ "U_U611_U625_MY20_Phev_Tx" SG_ 1819 TesterPhysicalResSCMH 1;
BA_ "U_CX482_CX483_MY20_Tx" SG_ 1819 TesterPhysicalResSCMH 1;
BA_ "U_U611_U625_MY20_Hev_Tx" SG_ 1819 TesterPhysicalResSCMH 1;
BA_ "U_U611_U625_MY20_Gas_Tx" SG_ 1819 TesterPhysicalResSCMH 1;
BA_ "GenSigSendType" SG_ 1819 TesterPhysicalResSCMH 3;
BA_ "U_P702_MY2021_Tx" SG_ 1818 TesterPhysicalResSCMG 1;
BA_ "U_U611_U625_MY20_Phev_Tx" SG_ 1818 TesterPhysicalResSCMG 1;
BA_ "U_CX482_CX483_MY20_Tx" SG_ 1818 TesterPhysicalResSCMG 1;
BA_ "U_U611_U625_MY20_Hev_Tx" SG_ 1818 TesterPhysicalResSCMG 1;
BA_ "U_U611_U625_MY20_Gas_Tx" SG_ 1818 TesterPhysicalResSCMG 1;
BA_ "GenSigSendType" SG_ 1818 TesterPhysicalResSCMG 3;
BA_ "U_P702_MY2021_Rx" SG_ 1811 TesterPhysicalReqSCMH 1;
BA_ "U_U611_U625_MY20_Phev_Rx" SG_ 1811 TesterPhysicalReqSCMH 1;
BA_ "U_CX482_CX483_MY20_Rx" SG_ 1811 TesterPhysicalReqSCMH 1;
BA_ "U_U611_U625_MY20_Hev_Rx" SG_ 1811 TesterPhysicalReqSCMH 1;
BA_ "U_U611_U625_MY20_Gas_Rx" SG_ 1811 TesterPhysicalReqSCMH 1;
BA_ "GenSigSendType" SG_ 1811 TesterPhysicalReqSCMH 3;
BA_ "U_P702_MY2021_Rx" SG_ 1810 TesterPhysicalReqSCMG 1;
BA_ "U_U611_U625_MY20_Phev_Rx" SG_ 1810 TesterPhysicalReqSCMG 1;
BA_ "U_CX482_CX483_MY20_Rx" SG_ 1810 TesterPhysicalReqSCMG 1;
BA_ "U_U611_U625_MY20_Hev_Rx" SG_ 1810 TesterPhysicalReqSCMG 1;
BA_ "U_U611_U625_MY20_Gas_Rx" SG_ 1810 TesterPhysicalReqSCMG 1;
BA_ "GenSigSendType" SG_ 1810 TesterPhysicalReqSCMG 3;
BA_ "U_CX482_CX483_MY20_Rx" SG_ 1310 GWM_Network_Mgmt_MS1 1;
BA_ "GenSigSendType" SG_ 1310 GWM_Network_Mgmt_MS1 3;
BA_ "GenSigSendType" SG_ 1066 BattULo_U_Actl_UB 3;
BA_ "U_P702_MY2021_Rx" SG_ 1066 BattULo_U_Actl_UB 1;
BA_ "U_CX727_MY2021_Rx" SG_ 1066 BattULo_U_Actl_UB 1;
BA_ "U_CX430_MY2021_Rx" SG_ 1066 BattULo_U_Actl_UB 1;
BA_ "U_U611_U625_MY20_Phev_Rx" SG_ 1066 BattULo_U_Actl_UB 1;
BA_ "U_B562_MY18_Diesel_Rx" SG_ 1066 BattULo_U_Actl_UB 1;
BA_ "U_CX482_CX483_MY20_Rx" SG_ 1066 BattULo_U_Actl_UB 1;
BA_ "U_U611_U625_MY20_Hev_Rx" SG_ 1066 BattULo_U_Actl_UB 1;
BA_ "U_U611_U625_MY20_Gas_Rx" SG_ 1066 BattULo_U_Actl_UB 1;
BA_ "U_B500_MY18_Diesel_Rx" SG_ 1066 BattULo_U_Actl_UB 1;
BA_ "U_B500_MY18_Gas_Rx" SG_ 1066 BattULo_U_Actl_UB 1;
BA_ "U_C490_MY18_Rx" SG_ 1066 BattULo_U_Actl_UB 1;
BA_ "U_B562_MY18_Gas_Rx" SG_ 1066 BattULo_U_Actl_UB 1;
BA_ "U_C519_MY18_5_Gas_Rx" SG_ 1066 BattULo_U_Actl_UB 1;
BA_ "U_C519_MY18_5_Diesel_Rx" SG_ 1066 BattULo_U_Actl_UB 1;
BA_ "U_B515_MCA_MY17_Gas_Rx" SG_ 1066 BattULo_U_Actl_UB 1;
BA_ "U_B515_MCA_MY17_Diesel_Rx" SG_ 1066 BattULo_U_Actl_UB 1;
BA_ "U_B479_MY17_Diesel_Rx" SG_ 1066 BattULo_U_Actl_UB 1;
BA_ "U_B479_MY17_Gas_Rx" SG_ 1066 BattULo_U_Actl_UB 1;
BA_ "GenSigSendType" SG_ 1066 BattULo_U_Actl 3;
BA_ "U_P702_MY2021_Rx" SG_ 1066 BattULo_U_Actl 1;
BA_ "U_CX727_MY2021_Rx" SG_ 1066 BattULo_U_Actl 1;
BA_ "U_CX430_MY2021_Rx" SG_ 1066 BattULo_U_Actl 1;
BA_ "U_U611_U625_MY20_Phev_Rx" SG_ 1066 BattULo_U_Actl 1;
BA_ "U_B562_MY18_Diesel_Rx" SG_ 1066 BattULo_U_Actl 1;
BA_ "U_CX482_CX483_MY20_Rx" SG_ 1066 BattULo_U_Actl 1;
BA_ "U_U611_U625_MY20_Hev_Rx" SG_ 1066 BattULo_U_Actl 1;
BA_ "U_U611_U625_MY20_Gas_Rx" SG_ 1066 BattULo_U_Actl 1;
BA_ "U_B500_MY18_Diesel_Rx" SG_ 1066 BattULo_U_Actl 1;
BA_ "U_B500_MY18_Gas_Rx" SG_ 1066 BattULo_U_Actl 1;
BA_ "U_C490_MY18_Rx" SG_ 1066 BattULo_U_Actl 1;
BA_ "U_B562_MY18_Gas_Rx" SG_ 1066 BattULo_U_Actl 1;
BA_ "U_C519_MY18_5_Gas_Rx" SG_ 1066 BattULo_U_Actl 1;
BA_ "U_C519_MY18_5_Diesel_Rx" SG_ 1066 BattULo_U_Actl 1;
BA_ "U_B515_MCA_MY17_Gas_Rx" SG_ 1066 BattULo_U_Actl 1;
BA_ "U_B515_MCA_MY17_Diesel_Rx" SG_ 1066 BattULo_U_Actl 1;
BA_ "U_B479_MY17_Diesel_Rx" SG_ 1066 BattULo_U_Actl 1;
BA_ "U_B479_MY17_Gas_Rx" SG_ 1066 BattULo_U_Actl 1;
BA_ "GenSigStartValue" SG_ 1066 BattULo_U_Actl 255;
BA_ "GenSigStartValueInteger" SG_ 1066 BattULo_U_Actl 255;
BA_ "GenSigSendType" SG_ 1066 PwSrcULo_I_Mx 3;
BA_ "U_P702_MY2021_Rx" SG_ 1066 PwSrcULo_I_Mx 1;
BA_ "U_CX727_MY2021_Rx" SG_ 1066 PwSrcULo_I_Mx 1;
BA_ "U_CX430_MY2021_Rx" SG_ 1066 PwSrcULo_I_Mx 1;
BA_ "U_U611_U625_MY20_Phev_Rx" SG_ 1066 PwSrcULo_I_Mx 1;
BA_ "U_B562_MY18_Diesel_Rx" SG_ 1066 PwSrcULo_I_Mx 1;
BA_ "U_CX482_CX483_MY20_Rx" SG_ 1066 PwSrcULo_I_Mx 1;
BA_ "U_U611_U625_MY20_Hev_Rx" SG_ 1066 PwSrcULo_I_Mx 1;
BA_ "U_U611_U625_MY20_Gas_Rx" SG_ 1066 PwSrcULo_I_Mx 1;
BA_ "U_B500_MY18_Diesel_Rx" SG_ 1066 PwSrcULo_I_Mx 1;
BA_ "U_B500_MY18_Gas_Rx" SG_ 1066 PwSrcULo_I_Mx 1;
BA_ "U_C490_MY18_Rx" SG_ 1066 PwSrcULo_I_Mx 1;
BA_ "U_B562_MY18_Gas_Rx" SG_ 1066 PwSrcULo_I_Mx 1;
BA_ "U_C519_MY18_5_Gas_Rx" SG_ 1066 PwSrcULo_I_Mx 1;
BA_ "U_C519_MY18_5_Diesel_Rx" SG_ 1066 PwSrcULo_I_Mx 1;
BA_ "U_B515_MCA_MY17_Gas_Rx" SG_ 1066 PwSrcULo_I_Mx 1;
BA_ "U_B515_MCA_MY17_Diesel_Rx" SG_ 1066 PwSrcULo_I_Mx 1;
BA_ "U_B479_MY17_Diesel_Rx" SG_ 1066 PwSrcULo_I_Mx 1;
BA_ "U_B479_MY17_Gas_Rx" SG_ 1066 PwSrcULo_I_Mx 1;
BA_ "GenSigSendType" SG_ 1066 PwSrcULo_I_Actl 3;
BA_ "U_P702_MY2021_Rx" SG_ 1066 PwSrcULo_I_Actl 1;
BA_ "U_CX727_MY2021_Rx" SG_ 1066 PwSrcULo_I_Actl 1;
BA_ "U_CX430_MY2021_Rx" SG_ 1066 PwSrcULo_I_Actl 1;
BA_ "U_U611_U625_MY20_Phev_Rx" SG_ 1066 PwSrcULo_I_Actl 1;
BA_ "U_B562_MY18_Diesel_Rx" SG_ 1066 PwSrcULo_I_Actl 1;
BA_ "U_CX482_CX483_MY20_Rx" SG_ 1066 PwSrcULo_I_Actl 1;
BA_ "U_U611_U625_MY20_Hev_Rx" SG_ 1066 PwSrcULo_I_Actl 1;
BA_ "U_U611_U625_MY20_Gas_Rx" SG_ 1066 PwSrcULo_I_Actl 1;
BA_ "U_B500_MY18_Diesel_Rx" SG_ 1066 PwSrcULo_I_Actl 1;
BA_ "U_B500_MY18_Gas_Rx" SG_ 1066 PwSrcULo_I_Actl 1;
BA_ "U_C490_MY18_Rx" SG_ 1066 PwSrcULo_I_Actl 1;
BA_ "U_B562_MY18_Gas_Rx" SG_ 1066 PwSrcULo_I_Actl 1;
BA_ "U_C519_MY18_5_Gas_Rx" SG_ 1066 PwSrcULo_I_Actl 1;
BA_ "U_C519_MY18_5_Diesel_Rx" SG_ 1066 PwSrcULo_I_Actl 1;
BA_ "U_B515_MCA_MY17_Gas_Rx" SG_ 1066 PwSrcULo_I_Actl 1;
BA_ "U_B515_MCA_MY17_Diesel_Rx" SG_ 1066 PwSrcULo_I_Actl 1;
BA_ "U_B479_MY17_Diesel_Rx" SG_ 1066 PwSrcULo_I_Actl 1;
BA_ "U_B479_MY17_Gas_Rx" SG_ 1066 PwSrcULo_I_Actl 1;
BA_ "GenSigSendType" SG_ 1066 PwSrcULo_I_Mx_UB 3;
BA_ "U_P702_MY2021_Rx" SG_ 1066 PwSrcULo_I_Mx_UB 1;
BA_ "U_CX727_MY2021_Rx" SG_ 1066 PwSrcULo_I_Mx_UB 1;
BA_ "U_CX430_MY2021_Rx" SG_ 1066 PwSrcULo_I_Mx_UB 1;
BA_ "U_U611_U625_MY20_Phev_Rx" SG_ 1066 PwSrcULo_I_Mx_UB 1;
BA_ "U_B562_MY18_Diesel_Rx" SG_ 1066 PwSrcULo_I_Mx_UB 1;
BA_ "U_CX482_CX483_MY20_Rx" SG_ 1066 PwSrcULo_I_Mx_UB 1;
BA_ "U_U611_U625_MY20_Hev_Rx" SG_ 1066 PwSrcULo_I_Mx_UB 1;
BA_ "U_U611_U625_MY20_Gas_Rx" SG_ 1066 PwSrcULo_I_Mx_UB 1;
BA_ "U_B500_MY18_Diesel_Rx" SG_ 1066 PwSrcULo_I_Mx_UB 1;
BA_ "U_B500_MY18_Gas_Rx" SG_ 1066 PwSrcULo_I_Mx_UB 1;
BA_ "U_C490_MY18_Rx" SG_ 1066 PwSrcULo_I_Mx_UB 1;
BA_ "U_B562_MY18_Gas_Rx" SG_ 1066 PwSrcULo_I_Mx_UB 1;
BA_ "U_C519_MY18_5_Gas_Rx" SG_ 1066 PwSrcULo_I_Mx_UB 1;
BA_ "U_C519_MY18_5_Diesel_Rx" SG_ 1066 PwSrcULo_I_Mx_UB 1;
BA_ "U_B515_MCA_MY17_Gas_Rx" SG_ 1066 PwSrcULo_I_Mx_UB 1;
BA_ "U_B515_MCA_MY17_Diesel_Rx" SG_ 1066 PwSrcULo_I_Mx_UB 1;
BA_ "U_B479_MY17_Diesel_Rx" SG_ 1066 PwSrcULo_I_Mx_UB 1;
BA_ "U_B479_MY17_Gas_Rx" SG_ 1066 PwSrcULo_I_Mx_UB 1;
BA_ "GenSigSendType" SG_ 1066 PwSrcULo_I_Actl_UB 3;
BA_ "U_P702_MY2021_Rx" SG_ 1066 PwSrcULo_I_Actl_UB 1;
BA_ "U_CX727_MY2021_Rx" SG_ 1066 PwSrcULo_I_Actl_UB 1;
BA_ "U_CX430_MY2021_Rx" SG_ 1066 PwSrcULo_I_Actl_UB 1;
BA_ "U_U611_U625_MY20_Phev_Rx" SG_ 1066 PwSrcULo_I_Actl_UB 1;
BA_ "U_B562_MY18_Diesel_Rx" SG_ 1066 PwSrcULo_I_Actl_UB 1;
BA_ "U_CX482_CX483_MY20_Rx" SG_ 1066 PwSrcULo_I_Actl_UB 1;
BA_ "U_U611_U625_MY20_Hev_Rx" SG_ 1066 PwSrcULo_I_Actl_UB 1;
BA_ "U_U611_U625_MY20_Gas_Rx" SG_ 1066 PwSrcULo_I_Actl_UB 1;
BA_ "U_B500_MY18_Diesel_Rx" SG_ 1066 PwSrcULo_I_Actl_UB 1;
BA_ "U_B500_MY18_Gas_Rx" SG_ 1066 PwSrcULo_I_Actl_UB 1;
BA_ "U_C490_MY18_Rx" SG_ 1066 PwSrcULo_I_Actl_UB 1;
BA_ "U_B562_MY18_Gas_Rx" SG_ 1066 PwSrcULo_I_Actl_UB 1;
BA_ "U_C519_MY18_5_Gas_Rx" SG_ 1066 PwSrcULo_I_Actl_UB 1;
BA_ "U_C519_MY18_5_Diesel_Rx" SG_ 1066 PwSrcULo_I_Actl_UB 1;
BA_ "U_B515_MCA_MY17_Gas_Rx" SG_ 1066 PwSrcULo_I_Actl_UB 1;
BA_ "U_B515_MCA_MY17_Diesel_Rx" SG_ 1066 PwSrcULo_I_Actl_UB 1;
BA_ "U_B479_MY17_Diesel_Rx" SG_ 1066 PwSrcULo_I_Actl_UB 1;
BA_ "U_B479_MY17_Gas_Rx" SG_ 1066 PwSrcULo_I_Actl_UB 1;
BA_ "CrossOver_InfoCAN" SG_ 994 Pers4OptIn_B_Stats 1;
BA_ "WakeupSignal" SG_ 994 Pers4OptIn_B_Stats 1;
BA_ "CrossOver_InfoCAN" SG_ 994 Pers3OptIn_B_Stats 1;
BA_ "WakeupSignal" SG_ 994 Pers3OptIn_B_Stats 1;
BA_ "CrossOver_InfoCAN" SG_ 994 Pers2OptIn_B_Stats 1;
BA_ "WakeupSignal" SG_ 994 Pers2OptIn_B_Stats 1;
BA_ "CrossOver_InfoCAN" SG_ 994 Pers1OptIn_B_Stats 1;
BA_ "WakeupSignal" SG_ 994 Pers1OptIn_B_Stats 1;
BA_ "U_B500_MY18_Diesel_Rx" SG_ 994 CtrStkPersIndex_D_Actl 1;
BA_ "U_B500_MY18_Gas_Rx" SG_ 994 CtrStkPersIndex_D_Actl 1;
BA_ "U_C519_MY18_5_Gas_Rx" SG_ 994 CtrStkPersIndex_D_Actl 1;
BA_ "U_C519_MY18_5_Diesel_Rx" SG_ 994 CtrStkPersIndex_D_Actl 1;
BA_ "U_B515_MCA_MY17_Gas_Rx" SG_ 994 CtrStkPersIndex_D_Actl 1;
BA_ "U_B515_MCA_MY17_Diesel_Rx" SG_ 994 CtrStkPersIndex_D_Actl 1;
BA_ "U_B479_MY17_Diesel_Rx" SG_ 994 CtrStkPersIndex_D_Actl 1;
BA_ "U_B479_MY17_Gas_Rx" SG_ 994 CtrStkPersIndex_D_Actl 1;
BA_ "U_CX727_MY2021_Rx" SG_ 994 CtrStkPersIndex_D_Actl 1;
BA_ "U_CX430_MY2021_Rx" SG_ 994 CtrStkPersIndex_D_Actl 1;
BA_ "U_P702_MY2021_Rx" SG_ 994 CtrStkPersIndex_D_Actl 1;
BA_ "U_U611_U625_MY20_Phev_Rx" SG_ 994 CtrStkPersIndex_D_Actl 1;
BA_ "U_CX482_CX483_MY20_Rx" SG_ 994 CtrStkPersIndex_D_Actl 1;
BA_ "U_U611_U625_MY20_Hev_Rx" SG_ 994 CtrStkPersIndex_D_Actl 1;
BA_ "U_U611_U625_MY20_Gas_Rx" SG_ 994 CtrStkPersIndex_D_Actl 1;
BA_ "GenSigSendType" SG_ 994 CtrStkPersIndex_D_Actl 3;
BA_ "GenSigStartValue" SG_ 994 CtrStkPersIndex_D_Actl 4;
BA_ "GenSigStartValueInteger" SG_ 994 CtrStkPersIndex_D_Actl 4;
BA_ "CrossOver_InfoCAN" SG_ 994 CtrStkPersIndex_D_Actl 1;
BA_ "U_B500_MY18_Diesel_Rx" SG_ 994 CtrStkFeatNoActl 1;
BA_ "U_B500_MY18_Gas_Rx" SG_ 994 CtrStkFeatNoActl 1;
BA_ "U_C519_MY18_5_Gas_Rx" SG_ 994 CtrStkFeatNoActl 1;
BA_ "U_C519_MY18_5_Diesel_Rx" SG_ 994 CtrStkFeatNoActl 1;
BA_ "U_B515_MCA_MY17_Gas_Rx" SG_ 994 CtrStkFeatNoActl 1;
BA_ "U_B515_MCA_MY17_Diesel_Rx" SG_ 994 CtrStkFeatNoActl 1;
BA_ "U_B479_MY17_Diesel_Rx" SG_ 994 CtrStkFeatNoActl 1;
BA_ "U_B479_MY17_Gas_Rx" SG_ 994 CtrStkFeatNoActl 1;
BA_ "U_P702_MY2021_Rx" SG_ 994 CtrStkFeatNoActl 1;
BA_ "U_CX727_MY2021_Rx" SG_ 994 CtrStkFeatNoActl 1;
BA_ "U_CX430_MY2021_Rx" SG_ 994 CtrStkFeatNoActl 1;
BA_ "U_U611_U625_MY20_Phev_Rx" SG_ 994 CtrStkFeatNoActl 1;
BA_ "U_CX482_CX483_MY20_Rx" SG_ 994 CtrStkFeatNoActl 1;
BA_ "U_U611_U625_MY20_Hev_Rx" SG_ 994 CtrStkFeatNoActl 1;
BA_ "U_U611_U625_MY20_Gas_Rx" SG_ 994 CtrStkFeatNoActl 1;
BA_ "GenSigSendType" SG_ 994 CtrStkFeatNoActl 3;
BA_ "CrossOver_InfoCAN" SG_ 994 CtrStkFeatNoActl 1;
BA_ "U_B500_MY18_Diesel_Rx" SG_ 994 CtrStkFeatConfigActl 1;
BA_ "U_B500_MY18_Gas_Rx" SG_ 994 CtrStkFeatConfigActl 1;
BA_ "U_C519_MY18_5_Gas_Rx" SG_ 994 CtrStkFeatConfigActl 1;
BA_ "U_C519_MY18_5_Diesel_Rx" SG_ 994 CtrStkFeatConfigActl 1;
BA_ "U_B515_MCA_MY17_Gas_Rx" SG_ 994 CtrStkFeatConfigActl 1;
BA_ "U_B515_MCA_MY17_Diesel_Rx" SG_ 994 CtrStkFeatConfigActl 1;
BA_ "U_B479_MY17_Diesel_Rx" SG_ 994 CtrStkFeatConfigActl 1;
BA_ "U_B479_MY17_Gas_Rx" SG_ 994 CtrStkFeatConfigActl 1;
BA_ "U_P702_MY2021_Rx" SG_ 994 CtrStkFeatConfigActl 1;
BA_ "U_CX727_MY2021_Rx" SG_ 994 CtrStkFeatConfigActl 1;
BA_ "U_CX430_MY2021_Rx" SG_ 994 CtrStkFeatConfigActl 1;
BA_ "U_U611_U625_MY20_Phev_Rx" SG_ 994 CtrStkFeatConfigActl 1;
BA_ "U_CX482_CX483_MY20_Rx" SG_ 994 CtrStkFeatConfigActl 1;
BA_ "U_U611_U625_MY20_Hev_Rx" SG_ 994 CtrStkFeatConfigActl 1;
BA_ "U_U611_U625_MY20_Gas_Rx" SG_ 994 CtrStkFeatConfigActl 1;
BA_ "GenSigSendType" SG_ 994 CtrStkFeatConfigActl 3;
BA_ "CrossOver_InfoCAN" SG_ 994 CtrStkFeatConfigActl 1;
BA_ "U_B500_MY18_Diesel_Rx" SG_ 994 CtrStkDsplyOp_D_Rq 1;
BA_ "U_B500_MY18_Gas_Rx" SG_ 994 CtrStkDsplyOp_D_Rq 1;
BA_ "U_C519_MY18_5_Gas_Rx" SG_ 994 CtrStkDsplyOp_D_Rq 1;
BA_ "U_C519_MY18_5_Diesel_Rx" SG_ 994 CtrStkDsplyOp_D_Rq 1;
BA_ "U_B515_MCA_MY17_Gas_Rx" SG_ 994 CtrStkDsplyOp_D_Rq 1;
BA_ "U_B515_MCA_MY17_Diesel_Rx" SG_ 994 CtrStkDsplyOp_D_Rq 1;
BA_ "U_B479_MY17_Diesel_Rx" SG_ 994 CtrStkDsplyOp_D_Rq 1;
BA_ "U_B479_MY17_Gas_Rx" SG_ 994 CtrStkDsplyOp_D_Rq 1;
BA_ "U_CX727_MY2021_Rx" SG_ 994 CtrStkDsplyOp_D_Rq 1;
BA_ "U_CX430_MY2021_Rx" SG_ 994 CtrStkDsplyOp_D_Rq 1;
BA_ "U_P702_MY2021_Rx" SG_ 994 CtrStkDsplyOp_D_Rq 1;
BA_ "U_U611_U625_MY20_Phev_Rx" SG_ 994 CtrStkDsplyOp_D_Rq 1;
BA_ "U_CX482_CX483_MY20_Rx" SG_ 994 CtrStkDsplyOp_D_Rq 1;
BA_ "U_U611_U625_MY20_Hev_Rx" SG_ 994 CtrStkDsplyOp_D_Rq 1;
BA_ "U_U611_U625_MY20_Gas_Rx" SG_ 994 CtrStkDsplyOp_D_Rq 1;
BA_ "GenSigSendType" SG_ 994 CtrStkDsplyOp_D_Rq 3;
BA_ "CrossOver_InfoCAN" SG_ 994 CtrStkDsplyOp_D_Rq 1;
BA_ "U_P702_MY2021_Rx" SG_ 994 PersStore_D_Rq 1;
BA_ "U_CX727_MY2021_Rx" SG_ 994 PersStore_D_Rq 1;
BA_ "U_CX430_MY2021_Rx" SG_ 994 PersStore_D_Rq 1;
BA_ "U_U611_U625_MY20_Phev_Rx" SG_ 994 PersStore_D_Rq 1;
BA_ "U_CX482_CX483_MY20_Rx" SG_ 994 PersStore_D_Rq 1;
BA_ "U_U611_U625_MY20_Hev_Rx" SG_ 994 PersStore_D_Rq 1;
BA_ "U_U611_U625_MY20_Gas_Rx" SG_ 994 PersStore_D_Rq 1;
BA_ "CrossOver_InfoCAN" SG_ 994 PersStore_D_Rq 1;
BA_ "ContentDependant" SG_ 376 EngAout_Aa_Actl 1;
BA_ "CrossOver_InfoCAN" SG_ 376 EngAout_Aa_Actl 1;
BA_ "GenSigSendType" SG_ 376 HvacHtrCore2_Te_Actl 3;
BA_ "U_P702_MY2021_Rx" SG_ 376 HvacHtrCore2_Te_Actl 1;
BA_ "U_CX727_MY2021_Rx" SG_ 376 HvacHtrCore2_Te_Actl 1;
BA_ "U_CX430_MY2021_Rx" SG_ 376 HvacHtrCore2_Te_Actl 1;
BA_ "U_U611_U625_MY20_Phev_Rx" SG_ 376 HvacHtrCore2_Te_Actl 1;
BA_ "U_B562_MY18_Diesel_Rx" SG_ 376 HvacHtrCore2_Te_Actl 1;
BA_ "U_CX482_CX483_MY20_Rx" SG_ 376 HvacHtrCore2_Te_Actl 1;
BA_ "U_U611_U625_MY20_Hev_Rx" SG_ 376 HvacHtrCore2_Te_Actl 1;
BA_ "U_U611_U625_MY20_Gas_Rx" SG_ 376 HvacHtrCore2_Te_Actl 1;
BA_ "U_B562_MY18_Gas_Rx" SG_ 376 HvacHtrCore2_Te_Actl 1;
BA_ "GenSigStartValueInteger" SG_ 376 HvacHtrCore2_Te_Actl 200;
BA_ "GenSigSendType" SG_ 376 AirAmbTe_D_Qf 3;
BA_ "U_P702_MY2021_Rx" SG_ 376 AirAmbTe_D_Qf 1;
BA_ "U_CX727_MY2021_Rx" SG_ 376 AirAmbTe_D_Qf 1;
BA_ "U_H567_MY20_Rx" SG_ 376 AirAmbTe_D_Qf 1;
BA_ "U_CX430_MY2021_Rx" SG_ 376 AirAmbTe_D_Qf 1;
BA_ "U_U611_U625_MY20_Phev_Rx" SG_ 376 AirAmbTe_D_Qf 1;
BA_ "U_B562_MY18_Diesel_Rx" SG_ 376 AirAmbTe_D_Qf 1;
BA_ "U_CX482_CX483_MY20_Rx" SG_ 376 AirAmbTe_D_Qf 1;
BA_ "U_U611_U625_MY20_Hev_Rx" SG_ 376 AirAmbTe_D_Qf 1;
BA_ "U_U611_U625_MY20_Gas_Rx" SG_ 376 AirAmbTe_D_Qf 1;
BA_ "U_B500_MY18_Diesel_Rx" SG_ 376 AirAmbTe_D_Qf 1;
BA_ "U_B500_MY18_Gas_Rx" SG_ 376 AirAmbTe_D_Qf 1;
BA_ "U_C490_MY18_Rx" SG_ 376 AirAmbTe_D_Qf 1;
BA_ "U_B562_MY18_Gas_Rx" SG_ 376 AirAmbTe_D_Qf 1;
BA_ "U_C519_MY18_5_Gas_Rx" SG_ 376 AirAmbTe_D_Qf 1;
BA_ "U_C519_MY18_5_Diesel_Rx" SG_ 376 AirAmbTe_D_Qf 1;
BA_ "U_B515_MCA_MY17_Gas_Rx" SG_ 376 AirAmbTe_D_Qf 1;
BA_ "U_B515_MCA_MY17_Diesel_Rx" SG_ 376 AirAmbTe_D_Qf 1;
BA_ "U_B479_MY17_Diesel_Rx" SG_ 376 AirAmbTe_D_Qf 1;
BA_ "U_B479_MY17_Gas_Rx" SG_ 376 AirAmbTe_D_Qf 1;
BA_ "GenSigStartValue" SG_ 376 AirAmbTe_D_Qf 1;
BA_ "MetaData" SG_ 376 AirAmbTe_D_Qf 1;
BA_ "GenSigStartValueInteger" SG_ 376 AirAmbTe_D_Qf 1;
BA_ "CrossOver_InfoCAN" SG_ 376 AirAmbTe_D_Qf 1;
BA_ "GenSigSendType" SG_ 376 AirAmb_Te_ActlFilt 3;
BA_ "U_P702_MY2021_Rx" SG_ 376 AirAmb_Te_ActlFilt 1;
BA_ "U_CX727_MY2021_Rx" SG_ 376 AirAmb_Te_ActlFilt 1;
BA_ "U_H567_MY20_Rx" SG_ 376 AirAmb_Te_ActlFilt 1;
BA_ "U_CX430_MY2021_Rx" SG_ 376 AirAmb_Te_ActlFilt 1;
BA_ "U_U611_U625_MY20_Phev_Rx" SG_ 376 AirAmb_Te_ActlFilt 1;
BA_ "U_B562_MY18_Diesel_Rx" SG_ 376 AirAmb_Te_ActlFilt 1;
BA_ "U_CX482_CX483_MY20_Rx" SG_ 376 AirAmb_Te_ActlFilt 1;
BA_ "U_U611_U625_MY20_Hev_Rx" SG_ 376 AirAmb_Te_ActlFilt 1;
BA_ "U_U611_U625_MY20_Gas_Rx" SG_ 376 AirAmb_Te_ActlFilt 1;
BA_ "U_B500_MY18_Diesel_Rx" SG_ 376 AirAmb_Te_ActlFilt 1;
BA_ "U_B500_MY18_Gas_Rx" SG_ 376 AirAmb_Te_ActlFilt 1;
BA_ "U_C490_MY18_Rx" SG_ 376 AirAmb_Te_ActlFilt 1;
BA_ "U_B562_MY18_Gas_Rx" SG_ 376 AirAmb_Te_ActlFilt 1;
BA_ "U_C519_MY18_5_Gas_Rx" SG_ 376 AirAmb_Te_ActlFilt 1;
BA_ "U_C519_MY18_5_Diesel_Rx" SG_ 376 AirAmb_Te_ActlFilt 1;
BA_ "U_B515_MCA_MY17_Gas_Rx" SG_ 376 AirAmb_Te_ActlFilt 1;
BA_ "U_B515_MCA_MY17_Diesel_Rx" SG_ 376 AirAmb_Te_ActlFilt 1;
BA_ "U_B479_MY17_Diesel_Rx" SG_ 376 AirAmb_Te_ActlFilt 1;
BA_ "U_B479_MY17_Gas_Rx" SG_ 376 AirAmb_Te_ActlFilt 1;
BA_ "GenSigStartValueInteger" SG_ 376 AirAmb_Te_ActlFilt 512;
BA_ "CrossOver_InfoCAN" SG_ 376 AirAmb_Te_ActlFilt 1;
BA_ "GenSigSendType" SG_ 376 AirAmb_Te_Actl 3;
BA_ "U_P702_MY2021_Rx" SG_ 376 AirAmb_Te_Actl 1;
BA_ "U_CX727_MY2021_Rx" SG_ 376 AirAmb_Te_Actl 1;
BA_ "U_H567_MY20_Rx" SG_ 376 AirAmb_Te_Actl 1;
BA_ "U_CX430_MY2021_Rx" SG_ 376 AirAmb_Te_Actl 1;
BA_ "U_U611_U625_MY20_Phev_Rx" SG_ 376 AirAmb_Te_Actl 1;
BA_ "U_B562_MY18_Diesel_Rx" SG_ 376 AirAmb_Te_Actl 1;
BA_ "U_CX482_CX483_MY20_Rx" SG_ 376 AirAmb_Te_Actl 1;
BA_ "U_U611_U625_MY20_Hev_Rx" SG_ 376 AirAmb_Te_Actl 1;
BA_ "U_U611_U625_MY20_Gas_Rx" SG_ 376 AirAmb_Te_Actl 1;
BA_ "U_B500_MY18_Diesel_Rx" SG_ 376 AirAmb_Te_Actl 1;
BA_ "U_B500_MY18_Gas_Rx" SG_ 376 AirAmb_Te_Actl 1;
BA_ "U_C490_MY18_Rx" SG_ 376 AirAmb_Te_Actl 1;
BA_ "U_B562_MY18_Gas_Rx" SG_ 376 AirAmb_Te_Actl 1;
BA_ "U_C519_MY18_5_Gas_Rx" SG_ 376 AirAmb_Te_Actl 1;
BA_ "U_C519_MY18_5_Diesel_Rx" SG_ 376 AirAmb_Te_Actl 1;
BA_ "U_B515_MCA_MY17_Gas_Rx" SG_ 376 AirAmb_Te_Actl 1;
BA_ "U_B515_MCA_MY17_Diesel_Rx" SG_ 376 AirAmb_Te_Actl 1;
BA_ "U_B479_MY17_Diesel_Rx" SG_ 376 AirAmb_Te_Actl 1;
BA_ "U_B479_MY17_Gas_Rx" SG_ 376 AirAmb_Te_Actl 1;
BA_ "GenSigStartValueInteger" SG_ 376 AirAmb_Te_Actl 512;
BA_ "CrossOver_InfoCAN" SG_ 376 AirAmb_Te_Actl 1;
BA_ "U_CX482_CX483_MY20_Rx" SG_ 376 AirAmb_P_Actl 1;
BA_ "U_C519_MY18_5_Gas_Rx" SG_ 376 AirAmb_P_Actl 1;
BA_ "U_C519_MY18_5_Diesel_Rx" SG_ 376 AirAmb_P_Actl 1;
BA_ "CrossOver_InfoCAN" SG_ 376 AirAmb_P_Actl 1;
BA_ "U_P702_MY2021_Rx" SG_ 951 TirePress_Info_MaxInd 1;
BA_ "U_CX727_MY2021_Rx" SG_ 951 TirePress_Info_MaxInd 1;
BA_ "U_VN127_MY20_Rx" SG_ 951 TirePress_Info_MaxInd 1;
BA_ "U_H567_MY20_Rx" SG_ 951 TirePress_Info_MaxInd 1;
BA_ "U_CX430_MY2021_Rx" SG_ 951 TirePress_Info_MaxInd 1;
BA_ "U_U611_U625_MY20_Phev_Rx" SG_ 951 TirePress_Info_MaxInd 1;
BA_ "U_CX482_CX483_MY20_Rx" SG_ 951 TirePress_Info_MaxInd 1;
BA_ "U_U611_U625_MY20_Hev_Rx" SG_ 951 TirePress_Info_MaxInd 1;
BA_ "U_U611_U625_MY20_Gas_Rx" SG_ 951 TirePress_Info_MaxInd 1;
BA_ "U_C519_MY18_5_Gas_Rx" SG_ 951 TirePress_Info_MaxInd 1;
BA_ "U_C519_MY18_5_Diesel_Rx" SG_ 951 TirePress_Info_MaxInd 1;
BA_ "U_B515_MCA_MY17_Gas_Rx" SG_ 951 TirePress_Info_MaxInd 1;
BA_ "U_B515_MCA_MY17_Diesel_Rx" SG_ 951 TirePress_Info_MaxInd 1;
BA_ "U_B479_MY17_Diesel_Rx" SG_ 951 TirePress_Info_MaxInd 1;
BA_ "U_B479_MY17_Gas_Rx" SG_ 951 TirePress_Info_MaxInd 1;
BA_ "U_P702_MY2021_Rx" SG_ 951 TirePress_Info_Index 1;
BA_ "U_CX727_MY2021_Rx" SG_ 951 TirePress_Info_Index 1;
BA_ "U_VN127_MY20_Rx" SG_ 951 TirePress_Info_Index 1;
BA_ "U_H567_MY20_Rx" SG_ 951 TirePress_Info_Index 1;
BA_ "U_CX430_MY2021_Rx" SG_ 951 TirePress_Info_Index 1;
BA_ "U_U611_U625_MY20_Phev_Rx" SG_ 951 TirePress_Info_Index 1;
BA_ "U_CX482_CX483_MY20_Rx" SG_ 951 TirePress_Info_Index 1;
BA_ "U_U611_U625_MY20_Hev_Rx" SG_ 951 TirePress_Info_Index 1;
BA_ "U_U611_U625_MY20_Gas_Rx" SG_ 951 TirePress_Info_Index 1;
BA_ "U_C519_MY18_5_Gas_Rx" SG_ 951 TirePress_Info_Index 1;
BA_ "U_C519_MY18_5_Diesel_Rx" SG_ 951 TirePress_Info_Index 1;
BA_ "U_B515_MCA_MY17_Gas_Rx" SG_ 951 TirePress_Info_Index 1;
BA_ "U_B515_MCA_MY17_Diesel_Rx" SG_ 951 TirePress_Info_Index 1;
BA_ "U_B479_MY17_Diesel_Rx" SG_ 951 TirePress_Info_Index 1;
BA_ "U_B479_MY17_Gas_Rx" SG_ 951 TirePress_Info_Index 1;
BA_ "U_P702_MY2021_Rx" SG_ 951 TirePress_Info_ID 1;
BA_ "U_CX727_MY2021_Rx" SG_ 951 TirePress_Info_ID 1;
BA_ "U_VN127_MY20_Rx" SG_ 951 TirePress_Info_ID 1;
BA_ "U_H567_MY20_Rx" SG_ 951 TirePress_Info_ID 1;
BA_ "U_CX430_MY2021_Rx" SG_ 951 TirePress_Info_ID 1;
BA_ "U_U611_U625_MY20_Phev_Rx" SG_ 951 TirePress_Info_ID 1;
BA_ "U_CX482_CX483_MY20_Rx" SG_ 951 TirePress_Info_ID 1;
BA_ "U_U611_U625_MY20_Hev_Rx" SG_ 951 TirePress_Info_ID 1;
BA_ "U_U611_U625_MY20_Gas_Rx" SG_ 951 TirePress_Info_ID 1;
BA_ "U_C519_MY18_5_Gas_Rx" SG_ 951 TirePress_Info_ID 1;
BA_ "U_C519_MY18_5_Diesel_Rx" SG_ 951 TirePress_Info_ID 1;
BA_ "U_B515_MCA_MY17_Gas_Rx" SG_ 951 TirePress_Info_ID 1;
BA_ "U_B515_MCA_MY17_Diesel_Rx" SG_ 951 TirePress_Info_ID 1;
BA_ "U_B479_MY17_Diesel_Rx" SG_ 951 TirePress_Info_ID 1;
BA_ "U_B479_MY17_Gas_Rx" SG_ 951 TirePress_Info_ID 1;
BA_ "GenSigSendType" SG_ 1068 HvacAirFullOut_B_Rq_UB 3;
BA_ "GenSigSendType" SG_ 1068 HvacAirFullOut_B_Rq 3;
BA_ "GenSigSendType" SG_ 1068 HvacCmprLim_D_Stat_UB 3;
BA_ "GenSigSendType" SG_ 1068 HvacCmprLim_D_Stat 3;
BA_ "GenSigSendType" SG_ 1068 HvacAirFlw_B_RqBatt_UB 3;
BA_ "U_CX727_MY2021_Rx" SG_ 1068 HvacAirFlw_B_RqBatt_UB 1;
BA_ "U_CX430_MY2021_Rx" SG_ 1068 HvacAirFlw_B_RqBatt_UB 1;
BA_ "U_U611_U625_MY20_Phev_Rx" SG_ 1068 HvacAirFlw_B_RqBatt_UB 1;
BA_ "U_B562_MY18_Diesel_Rx" SG_ 1068 HvacAirFlw_B_RqBatt_UB 1;
BA_ "U_CX482_CX483_MY20_Rx" SG_ 1068 HvacAirFlw_B_RqBatt_UB 1;
BA_ "U_U611_U625_MY20_Hev_Rx" SG_ 1068 HvacAirFlw_B_RqBatt_UB 1;
BA_ "U_U611_U625_MY20_Gas_Rx" SG_ 1068 HvacAirFlw_B_RqBatt_UB 1;
BA_ "U_B562_MY18_Gas_Rx" SG_ 1068 HvacAirFlw_B_RqBatt_UB 1;
BA_ "U_C519_MY18_5_Gas_Rx" SG_ 1068 HvacAirFlw_B_RqBatt_UB 1;
BA_ "U_C519_MY18_5_Diesel_Rx" SG_ 1068 HvacAirFlw_B_RqBatt_UB 1;
BA_ "GenSigSendType" SG_ 1068 HvacAirFlw_B_RqBatt 3;
BA_ "U_CX727_MY2021_Rx" SG_ 1068 HvacAirFlw_B_RqBatt 1;
BA_ "U_CX430_MY2021_Rx" SG_ 1068 HvacAirFlw_B_RqBatt 1;
BA_ "U_U611_U625_MY20_Phev_Rx" SG_ 1068 HvacAirFlw_B_RqBatt 1;
BA_ "U_B562_MY18_Diesel_Rx" SG_ 1068 HvacAirFlw_B_RqBatt 1;
BA_ "U_CX482_CX483_MY20_Rx" SG_ 1068 HvacAirFlw_B_RqBatt 1;
BA_ "U_U611_U625_MY20_Hev_Rx" SG_ 1068 HvacAirFlw_B_RqBatt 1;
BA_ "U_U611_U625_MY20_Gas_Rx" SG_ 1068 HvacAirFlw_B_RqBatt 1;
BA_ "U_B562_MY18_Gas_Rx" SG_ 1068 HvacAirFlw_B_RqBatt 1;
BA_ "U_C519_MY18_5_Gas_Rx" SG_ 1068 HvacAirFlw_B_RqBatt 1;
BA_ "U_C519_MY18_5_Diesel_Rx" SG_ 1068 HvacAirFlw_B_RqBatt 1;
BA_ "WakeupSignal" SG_ 1068 HvacAirFlw_B_RqBatt 1;
BA_ "GenSigSendType" SG_ 1068 HvacRec_D_RqMxBatt_UB 3;
BA_ "U_CX727_MY2021_Rx" SG_ 1068 HvacRec_D_RqMxBatt_UB 1;
BA_ "U_CX430_MY2021_Rx" SG_ 1068 HvacRec_D_RqMxBatt_UB 1;
BA_ "U_U611_U625_MY20_Phev_Rx" SG_ 1068 HvacRec_D_RqMxBatt_UB 1;
BA_ "U_B562_MY18_Diesel_Rx" SG_ 1068 HvacRec_D_RqMxBatt_UB 1;
BA_ "U_CX482_CX483_MY20_Rx" SG_ 1068 HvacRec_D_RqMxBatt_UB 1;
BA_ "U_U611_U625_MY20_Hev_Rx" SG_ 1068 HvacRec_D_RqMxBatt_UB 1;
BA_ "U_U611_U625_MY20_Gas_Rx" SG_ 1068 HvacRec_D_RqMxBatt_UB 1;
BA_ "U_B562_MY18_Gas_Rx" SG_ 1068 HvacRec_D_RqMxBatt_UB 1;
BA_ "GenSigSendType" SG_ 1068 HvacRec_D_RqMxBatt 3;
BA_ "U_CX727_MY2021_Rx" SG_ 1068 HvacRec_D_RqMxBatt 1;
BA_ "U_CX430_MY2021_Rx" SG_ 1068 HvacRec_D_RqMxBatt 1;
BA_ "U_U611_U625_MY20_Phev_Rx" SG_ 1068 HvacRec_D_RqMxBatt 1;
BA_ "U_B562_MY18_Diesel_Rx" SG_ 1068 HvacRec_D_RqMxBatt 1;
BA_ "U_CX482_CX483_MY20_Rx" SG_ 1068 HvacRec_D_RqMxBatt 1;
BA_ "U_U611_U625_MY20_Hev_Rx" SG_ 1068 HvacRec_D_RqMxBatt 1;
BA_ "U_U611_U625_MY20_Gas_Rx" SG_ 1068 HvacRec_D_RqMxBatt 1;
BA_ "U_B562_MY18_Gas_Rx" SG_ 1068 HvacRec_D_RqMxBatt 1;
BA_ "GenSigStartValue" SG_ 1068 HvacRec_D_RqMxBatt 10;
BA_ "GenSigStartValueInteger" SG_ 1068 HvacRec_D_RqMxBatt 10;
BA_ "GenSigSendType" SG_ 1068 Batt_Lo_SoC_B_UB 3;
BA_ "U_CX727_MY2021_Rx" SG_ 1068 Batt_Lo_SoC_B_UB 1;
BA_ "U_B562_MY18_Diesel_Rx" SG_ 1068 Batt_Lo_SoC_B_UB 1;
BA_ "U_U611_U625_MY20_Hev_Rx" SG_ 1068 Batt_Lo_SoC_B_UB 1;
BA_ "U_B500_MY18_Diesel_Rx" SG_ 1068 Batt_Lo_SoC_B_UB 1;
BA_ "U_B500_MY18_Gas_Rx" SG_ 1068 Batt_Lo_SoC_B_UB 1;
BA_ "U_C490_MY18_Rx" SG_ 1068 Batt_Lo_SoC_B_UB 1;
BA_ "U_B562_MY18_Gas_Rx" SG_ 1068 Batt_Lo_SoC_B_UB 1;
BA_ "U_P702_MY2021_Rx" SG_ 1068 Batt_Lo_SoC_B_UB 1;
BA_ "U_CX430_MY2021_Rx" SG_ 1068 Batt_Lo_SoC_B_UB 1;
BA_ "U_U611_U625_MY20_Phev_Rx" SG_ 1068 Batt_Lo_SoC_B_UB 1;
BA_ "U_CX482_CX483_MY20_Rx" SG_ 1068 Batt_Lo_SoC_B_UB 1;
BA_ "U_U611_U625_MY20_Gas_Rx" SG_ 1068 Batt_Lo_SoC_B_UB 1;
BA_ "U_C519_MY18_5_Gas_Rx" SG_ 1068 Batt_Lo_SoC_B_UB 1;
BA_ "U_C519_MY18_5_Diesel_Rx" SG_ 1068 Batt_Lo_SoC_B_UB 1;
BA_ "U_B515_MCA_MY17_Gas_Rx" SG_ 1068 Batt_Lo_SoC_B_UB 1;
BA_ "U_B515_MCA_MY17_Diesel_Rx" SG_ 1068 Batt_Lo_SoC_B_UB 1;
BA_ "U_B479_MY17_Diesel_Rx" SG_ 1068 Batt_Lo_SoC_B_UB 1;
BA_ "U_B479_MY17_Gas_Rx" SG_ 1068 Batt_Lo_SoC_B_UB 1;
BA_ "CrossOver_InfoCAN" SG_ 1068 Batt_Lo_SoC_B_UB 1;
BA_ "GenSigSendType" SG_ 1068 Batt_Lo_SoC_B 3;
BA_ "U_CX727_MY2021_Rx" SG_ 1068 Batt_Lo_SoC_B 1;
BA_ "U_B562_MY18_Diesel_Rx" SG_ 1068 Batt_Lo_SoC_B 1;
BA_ "U_U611_U625_MY20_Hev_Rx" SG_ 1068 Batt_Lo_SoC_B 1;
BA_ "U_B500_MY18_Diesel_Rx" SG_ 1068 Batt_Lo_SoC_B 1;
BA_ "U_B500_MY18_Gas_Rx" SG_ 1068 Batt_Lo_SoC_B 1;
BA_ "U_C490_MY18_Rx" SG_ 1068 Batt_Lo_SoC_B 1;
BA_ "U_B562_MY18_Gas_Rx" SG_ 1068 Batt_Lo_SoC_B 1;
BA_ "U_P702_MY2021_Rx" SG_ 1068 Batt_Lo_SoC_B 1;
BA_ "U_CX430_MY2021_Rx" SG_ 1068 Batt_Lo_SoC_B 1;
BA_ "U_U611_U625_MY20_Phev_Rx" SG_ 1068 Batt_Lo_SoC_B 1;
BA_ "U_CX482_CX483_MY20_Rx" SG_ 1068 Batt_Lo_SoC_B 1;
BA_ "U_U611_U625_MY20_Gas_Rx" SG_ 1068 Batt_Lo_SoC_B 1;
BA_ "U_C519_MY18_5_Gas_Rx" SG_ 1068 Batt_Lo_SoC_B 1;
BA_ "U_C519_MY18_5_Diesel_Rx" SG_ 1068 Batt_Lo_SoC_B 1;
BA_ "U_B515_MCA_MY17_Gas_Rx" SG_ 1068 Batt_Lo_SoC_B 1;
BA_ "U_B515_MCA_MY17_Diesel_Rx" SG_ 1068 Batt_Lo_SoC_B 1;
BA_ "U_B479_MY17_Diesel_Rx" SG_ 1068 Batt_Lo_SoC_B 1;
BA_ "U_B479_MY17_Gas_Rx" SG_ 1068 Batt_Lo_SoC_B 1;
BA_ "CrossOver_InfoCAN" SG_ 1068 Batt_Lo_SoC_B 1;
BA_ "GenSigSendType" SG_ 1068 Batt_Crit_SoC_B_UB 3;
BA_ "U_CX727_MY2021_Rx" SG_ 1068 Batt_Crit_SoC_B_UB 1;
BA_ "U_B562_MY18_Diesel_Rx" SG_ 1068 Batt_Crit_SoC_B_UB 1;
BA_ "U_U611_U625_MY20_Hev_Rx" SG_ 1068 Batt_Crit_SoC_B_UB 1;
BA_ "U_B500_MY18_Diesel_Rx" SG_ 1068 Batt_Crit_SoC_B_UB 1;
BA_ "U_B500_MY18_Gas_Rx" SG_ 1068 Batt_Crit_SoC_B_UB 1;
BA_ "U_C490_MY18_Rx" SG_ 1068 Batt_Crit_SoC_B_UB 1;
BA_ "U_B562_MY18_Gas_Rx" SG_ 1068 Batt_Crit_SoC_B_UB 1;
BA_ "U_P702_MY2021_Rx" SG_ 1068 Batt_Crit_SoC_B_UB 1;
BA_ "U_CX430_MY2021_Rx" SG_ 1068 Batt_Crit_SoC_B_UB 1;
BA_ "U_U611_U625_MY20_Phev_Rx" SG_ 1068 Batt_Crit_SoC_B_UB 1;
BA_ "U_CX482_CX483_MY20_Rx" SG_ 1068 Batt_Crit_SoC_B_UB 1;
BA_ "U_U611_U625_MY20_Gas_Rx" SG_ 1068 Batt_Crit_SoC_B_UB 1;
BA_ "U_C519_MY18_5_Gas_Rx" SG_ 1068 Batt_Crit_SoC_B_UB 1;
BA_ "U_C519_MY18_5_Diesel_Rx" SG_ 1068 Batt_Crit_SoC_B_UB 1;
BA_ "U_B515_MCA_MY17_Gas_Rx" SG_ 1068 Batt_Crit_SoC_B_UB 1;
BA_ "U_B515_MCA_MY17_Diesel_Rx" SG_ 1068 Batt_Crit_SoC_B_UB 1;
BA_ "U_B479_MY17_Diesel_Rx" SG_ 1068 Batt_Crit_SoC_B_UB 1;
BA_ "U_B479_MY17_Gas_Rx" SG_ 1068 Batt_Crit_SoC_B_UB 1;
BA_ "CrossOver_InfoCAN" SG_ 1068 Batt_Crit_SoC_B_UB 1;
BA_ "GenSigSendType" SG_ 1068 Batt_Crit_SoC_B 3;
BA_ "U_CX727_MY2021_Rx" SG_ 1068 Batt_Crit_SoC_B 1;
BA_ "U_B562_MY18_Diesel_Rx" SG_ 1068 Batt_Crit_SoC_B 1;
BA_ "U_U611_U625_MY20_Hev_Rx" SG_ 1068 Batt_Crit_SoC_B 1;
BA_ "U_B500_MY18_Diesel_Rx" SG_ 1068 Batt_Crit_SoC_B 1;
BA_ "U_B500_MY18_Gas_Rx" SG_ 1068 Batt_Crit_SoC_B 1;
BA_ "U_C490_MY18_Rx" SG_ 1068 Batt_Crit_SoC_B 1;
BA_ "U_B562_MY18_Gas_Rx" SG_ 1068 Batt_Crit_SoC_B 1;
BA_ "U_P702_MY2021_Rx" SG_ 1068 Batt_Crit_SoC_B 1;
BA_ "U_CX430_MY2021_Rx" SG_ 1068 Batt_Crit_SoC_B 1;
BA_ "U_U611_U625_MY20_Phev_Rx" SG_ 1068 Batt_Crit_SoC_B 1;
BA_ "U_CX482_CX483_MY20_Rx" SG_ 1068 Batt_Crit_SoC_B 1;
BA_ "U_U611_U625_MY20_Gas_Rx" SG_ 1068 Batt_Crit_SoC_B 1;
BA_ "U_C519_MY18_5_Gas_Rx" SG_ 1068 Batt_Crit_SoC_B 1;
BA_ "U_C519_MY18_5_Diesel_Rx" SG_ 1068 Batt_Crit_SoC_B 1;
BA_ "U_B515_MCA_MY17_Gas_Rx" SG_ 1068 Batt_Crit_SoC_B 1;
BA_ "U_B515_MCA_MY17_Diesel_Rx" SG_ 1068 Batt_Crit_SoC_B 1;
BA_ "U_B479_MY17_Diesel_Rx" SG_ 1068 Batt_Crit_SoC_B 1;
BA_ "U_B479_MY17_Gas_Rx" SG_ 1068 Batt_Crit_SoC_B 1;
BA_ "CrossOver_InfoCAN" SG_ 1068 Batt_Crit_SoC_B 1;
BA_ "GenSigSendType" SG_ 1068 Shed_T_Eng_Off_B_UB 3;
BA_ "U_CX727_MY2021_Rx" SG_ 1068 Shed_T_Eng_Off_B_UB 1;
BA_ "U_H567_MY20_Rx" SG_ 1068 Shed_T_Eng_Off_B_UB 1;
BA_ "U_B562_MY18_Diesel_Rx" SG_ 1068 Shed_T_Eng_Off_B_UB 1;
BA_ "U_U611_U625_MY20_Hev_Rx" SG_ 1068 Shed_T_Eng_Off_B_UB 1;
BA_ "U_B500_MY18_Diesel_Rx" SG_ 1068 Shed_T_Eng_Off_B_UB 1;
BA_ "U_B500_MY18_Gas_Rx" SG_ 1068 Shed_T_Eng_Off_B_UB 1;
BA_ "U_C490_MY18_Rx" SG_ 1068 Shed_T_Eng_Off_B_UB 1;
BA_ "U_B562_MY18_Gas_Rx" SG_ 1068 Shed_T_Eng_Off_B_UB 1;
BA_ "U_P702_MY2021_Rx" SG_ 1068 Shed_T_Eng_Off_B_UB 1;
BA_ "U_CX430_MY2021_Rx" SG_ 1068 Shed_T_Eng_Off_B_UB 1;
BA_ "U_U611_U625_MY20_Phev_Rx" SG_ 1068 Shed_T_Eng_Off_B_UB 1;
BA_ "U_CX482_CX483_MY20_Rx" SG_ 1068 Shed_T_Eng_Off_B_UB 1;
BA_ "U_U611_U625_MY20_Gas_Rx" SG_ 1068 Shed_T_Eng_Off_B_UB 1;
BA_ "U_C519_MY18_5_Gas_Rx" SG_ 1068 Shed_T_Eng_Off_B_UB 1;
BA_ "U_C519_MY18_5_Diesel_Rx" SG_ 1068 Shed_T_Eng_Off_B_UB 1;
BA_ "U_B515_MCA_MY17_Gas_Rx" SG_ 1068 Shed_T_Eng_Off_B_UB 1;
BA_ "U_B515_MCA_MY17_Diesel_Rx" SG_ 1068 Shed_T_Eng_Off_B_UB 1;
BA_ "U_B479_MY17_Diesel_Rx" SG_ 1068 Shed_T_Eng_Off_B_UB 1;
BA_ "U_B479_MY17_Gas_Rx" SG_ 1068 Shed_T_Eng_Off_B_UB 1;
BA_ "CrossOver_InfoCAN" SG_ 1068 Shed_T_Eng_Off_B_UB 1;
BA_ "GenSigSendType" SG_ 1068 Shed_T_Eng_Off_B 3;
BA_ "U_CX727_MY2021_Rx" SG_ 1068 Shed_T_Eng_Off_B 1;
BA_ "U_H567_MY20_Rx" SG_ 1068 Shed_T_Eng_Off_B 1;
BA_ "U_B562_MY18_Diesel_Rx" SG_ 1068 Shed_T_Eng_Off_B 1;
BA_ "U_U611_U625_MY20_Hev_Rx" SG_ 1068 Shed_T_Eng_Off_B 1;
BA_ "U_B500_MY18_Diesel_Rx" SG_ 1068 Shed_T_Eng_Off_B 1;
BA_ "U_B500_MY18_Gas_Rx" SG_ 1068 Shed_T_Eng_Off_B 1;
BA_ "U_C490_MY18_Rx" SG_ 1068 Shed_T_Eng_Off_B 1;
BA_ "U_B562_MY18_Gas_Rx" SG_ 1068 Shed_T_Eng_Off_B 1;
BA_ "U_P702_MY2021_Rx" SG_ 1068 Shed_T_Eng_Off_B 1;
BA_ "U_CX430_MY2021_Rx" SG_ 1068 Shed_T_Eng_Off_B 1;
BA_ "U_U611_U625_MY20_Phev_Rx" SG_ 1068 Shed_T_Eng_Off_B 1;
BA_ "U_CX482_CX483_MY20_Rx" SG_ 1068 Shed_T_Eng_Off_B 1;
BA_ "U_U611_U625_MY20_Gas_Rx" SG_ 1068 Shed_T_Eng_Off_B 1;
BA_ "U_C519_MY18_5_Gas_Rx" SG_ 1068 Shed_T_Eng_Off_B 1;
BA_ "U_C519_MY18_5_Diesel_Rx" SG_ 1068 Shed_T_Eng_Off_B 1;
BA_ "U_B515_MCA_MY17_Gas_Rx" SG_ 1068 Shed_T_Eng_Off_B 1;
BA_ "U_B515_MCA_MY17_Diesel_Rx" SG_ 1068 Shed_T_Eng_Off_B 1;
BA_ "U_B479_MY17_Diesel_Rx" SG_ 1068 Shed_T_Eng_Off_B 1;
BA_ "U_B479_MY17_Gas_Rx" SG_ 1068 Shed_T_Eng_Off_B 1;
BA_ "CrossOver_InfoCAN" SG_ 1068 Shed_T_Eng_Off_B 1;
BA_ "GenSigSendType" SG_ 1068 Shed_Level_Req_UB 3;
BA_ "U_H567_MY20_Rx" SG_ 1068 Shed_Level_Req_UB 1;
BA_ "U_B562_MY18_Diesel_Rx" SG_ 1068 Shed_Level_Req_UB 1;
BA_ "U_B500_MY18_Diesel_Rx" SG_ 1068 Shed_Level_Req_UB 1;
BA_ "U_B500_MY18_Gas_Rx" SG_ 1068 Shed_Level_Req_UB 1;
BA_ "U_B562_MY18_Gas_Rx" SG_ 1068 Shed_Level_Req_UB 1;
BA_ "U_CX727_MY2021_Rx" SG_ 1068 Shed_Level_Req_UB 1;
BA_ "U_U611_U625_MY20_Hev_Rx" SG_ 1068 Shed_Level_Req_UB 1;
BA_ "U_C490_MY18_Rx" SG_ 1068 Shed_Level_Req_UB 1;
BA_ "U_P702_MY2021_Rx" SG_ 1068 Shed_Level_Req_UB 1;
BA_ "U_CX430_MY2021_Rx" SG_ 1068 Shed_Level_Req_UB 1;
BA_ "U_U611_U625_MY20_Phev_Rx" SG_ 1068 Shed_Level_Req_UB 1;
BA_ "U_CX482_CX483_MY20_Rx" SG_ 1068 Shed_Level_Req_UB 1;
BA_ "U_U611_U625_MY20_Gas_Rx" SG_ 1068 Shed_Level_Req_UB 1;
BA_ "U_C519_MY18_5_Gas_Rx" SG_ 1068 Shed_Level_Req_UB 1;
BA_ "U_C519_MY18_5_Diesel_Rx" SG_ 1068 Shed_Level_Req_UB 1;
BA_ "U_B515_MCA_MY17_Gas_Rx" SG_ 1068 Shed_Level_Req_UB 1;
BA_ "U_B515_MCA_MY17_Diesel_Rx" SG_ 1068 Shed_Level_Req_UB 1;
BA_ "U_B479_MY17_Diesel_Rx" SG_ 1068 Shed_Level_Req_UB 1;
BA_ "U_B479_MY17_Gas_Rx" SG_ 1068 Shed_Level_Req_UB 1;
BA_ "CrossOver_InfoCAN" SG_ 1068 Shed_Level_Req_UB 1;
BA_ "GenSigSendType" SG_ 1068 Shed_Level_Req 3;
BA_ "U_H567_MY20_Rx" SG_ 1068 Shed_Level_Req 1;
BA_ "U_B562_MY18_Diesel_Rx" SG_ 1068 Shed_Level_Req 1;
BA_ "U_B500_MY18_Diesel_Rx" SG_ 1068 Shed_Level_Req 1;
BA_ "U_B500_MY18_Gas_Rx" SG_ 1068 Shed_Level_Req 1;
BA_ "U_B562_MY18_Gas_Rx" SG_ 1068 Shed_Level_Req 1;
BA_ "U_CX727_MY2021_Rx" SG_ 1068 Shed_Level_Req 1;
BA_ "U_U611_U625_MY20_Hev_Rx" SG_ 1068 Shed_Level_Req 1;
BA_ "U_C490_MY18_Rx" SG_ 1068 Shed_Level_Req 1;
BA_ "U_P702_MY2021_Rx" SG_ 1068 Shed_Level_Req 1;
BA_ "U_CX430_MY2021_Rx" SG_ 1068 Shed_Level_Req 1;
BA_ "U_U611_U625_MY20_Phev_Rx" SG_ 1068 Shed_Level_Req 1;
BA_ "U_CX482_CX483_MY20_Rx" SG_ 1068 Shed_Level_Req 1;
BA_ "U_U611_U625_MY20_Gas_Rx" SG_ 1068 Shed_Level_Req 1;
BA_ "U_C519_MY18_5_Gas_Rx" SG_ 1068 Shed_Level_Req 1;
BA_ "U_C519_MY18_5_Diesel_Rx" SG_ 1068 Shed_Level_Req 1;
BA_ "U_B515_MCA_MY17_Gas_Rx" SG_ 1068 Shed_Level_Req 1;
BA_ "U_B515_MCA_MY17_Diesel_Rx" SG_ 1068 Shed_Level_Req 1;
BA_ "U_B479_MY17_Diesel_Rx" SG_ 1068 Shed_Level_Req 1;
BA_ "U_B479_MY17_Gas_Rx" SG_ 1068 Shed_Level_Req 1;
BA_ "CrossOver_InfoCAN" SG_ 1068 Shed_Level_Req 1;
BA_ "WakeupSignal" SG_ 1068 Shed_Level_Req 1;
BA_ "GenSigSendType" SG_ 1068 Shed_Feature_Group_ID_UB 3;
BA_ "U_CX727_MY2021_Rx" SG_ 1068 Shed_Feature_Group_ID_UB 1;
BA_ "U_H567_MY20_Rx" SG_ 1068 Shed_Feature_Group_ID_UB 1;
BA_ "U_B562_MY18_Diesel_Rx" SG_ 1068 Shed_Feature_Group_ID_UB 1;
BA_ "U_U611_U625_MY20_Hev_Rx" SG_ 1068 Shed_Feature_Group_ID_UB 1;
BA_ "U_B500_MY18_Diesel_Rx" SG_ 1068 Shed_Feature_Group_ID_UB 1;
BA_ "U_B500_MY18_Gas_Rx" SG_ 1068 Shed_Feature_Group_ID_UB 1;
BA_ "U_C490_MY18_Rx" SG_ 1068 Shed_Feature_Group_ID_UB 1;
BA_ "U_B562_MY18_Gas_Rx" SG_ 1068 Shed_Feature_Group_ID_UB 1;
BA_ "U_P702_MY2021_Rx" SG_ 1068 Shed_Feature_Group_ID_UB 1;
BA_ "U_CX430_MY2021_Rx" SG_ 1068 Shed_Feature_Group_ID_UB 1;
BA_ "U_U611_U625_MY20_Phev_Rx" SG_ 1068 Shed_Feature_Group_ID_UB 1;
BA_ "U_CX482_CX483_MY20_Rx" SG_ 1068 Shed_Feature_Group_ID_UB 1;
BA_ "U_U611_U625_MY20_Gas_Rx" SG_ 1068 Shed_Feature_Group_ID_UB 1;
BA_ "U_C519_MY18_5_Gas_Rx" SG_ 1068 Shed_Feature_Group_ID_UB 1;
BA_ "U_C519_MY18_5_Diesel_Rx" SG_ 1068 Shed_Feature_Group_ID_UB 1;
BA_ "U_B515_MCA_MY17_Gas_Rx" SG_ 1068 Shed_Feature_Group_ID_UB 1;
BA_ "U_B515_MCA_MY17_Diesel_Rx" SG_ 1068 Shed_Feature_Group_ID_UB 1;
BA_ "U_B479_MY17_Diesel_Rx" SG_ 1068 Shed_Feature_Group_ID_UB 1;
BA_ "U_B479_MY17_Gas_Rx" SG_ 1068 Shed_Feature_Group_ID_UB 1;
BA_ "GenSigSendType" SG_ 1068 Shed_Feature_Group_ID 3;
BA_ "U_CX727_MY2021_Rx" SG_ 1068 Shed_Feature_Group_ID 1;
BA_ "U_H567_MY20_Rx" SG_ 1068 Shed_Feature_Group_ID 1;
BA_ "U_B562_MY18_Diesel_Rx" SG_ 1068 Shed_Feature_Group_ID 1;
BA_ "U_U611_U625_MY20_Hev_Rx" SG_ 1068 Shed_Feature_Group_ID 1;
BA_ "U_B500_MY18_Diesel_Rx" SG_ 1068 Shed_Feature_Group_ID 1;
BA_ "U_B500_MY18_Gas_Rx" SG_ 1068 Shed_Feature_Group_ID 1;
BA_ "U_C490_MY18_Rx" SG_ 1068 Shed_Feature_Group_ID 1;
BA_ "U_B562_MY18_Gas_Rx" SG_ 1068 Shed_Feature_Group_ID 1;
BA_ "U_P702_MY2021_Rx" SG_ 1068 Shed_Feature_Group_ID 1;
BA_ "U_CX430_MY2021_Rx" SG_ 1068 Shed_Feature_Group_ID 1;
BA_ "U_U611_U625_MY20_Phev_Rx" SG_ 1068 Shed_Feature_Group_ID 1;
BA_ "U_CX482_CX483_MY20_Rx" SG_ 1068 Shed_Feature_Group_ID 1;
BA_ "U_U611_U625_MY20_Gas_Rx" SG_ 1068 Shed_Feature_Group_ID 1;
BA_ "U_C519_MY18_5_Gas_Rx" SG_ 1068 Shed_Feature_Group_ID 1;
BA_ "U_C519_MY18_5_Diesel_Rx" SG_ 1068 Shed_Feature_Group_ID 1;
BA_ "U_B515_MCA_MY17_Gas_Rx" SG_ 1068 Shed_Feature_Group_ID 1;
BA_ "U_B515_MCA_MY17_Diesel_Rx" SG_ 1068 Shed_Feature_Group_ID 1;
BA_ "U_B479_MY17_Diesel_Rx" SG_ 1068 Shed_Feature_Group_ID 1;
BA_ "U_B479_MY17_Gas_Rx" SG_ 1068 Shed_Feature_Group_ID 1;
BA_ "WakeupSignal" SG_ 1068 Shed_Feature_Group_ID 1;
BA_ "GenSigSendType" SG_ 1068 Shed_Drain_Eng_Off_B_UB 3;
BA_ "U_CX727_MY2021_Rx" SG_ 1068 Shed_Drain_Eng_Off_B_UB 1;
BA_ "U_H567_MY20_Rx" SG_ 1068 Shed_Drain_Eng_Off_B_UB 1;
BA_ "U_B562_MY18_Diesel_Rx" SG_ 1068 Shed_Drain_Eng_Off_B_UB 1;
BA_ "U_U611_U625_MY20_Hev_Rx" SG_ 1068 Shed_Drain_Eng_Off_B_UB 1;
BA_ "U_B500_MY18_Diesel_Rx" SG_ 1068 Shed_Drain_Eng_Off_B_UB 1;
BA_ "U_B500_MY18_Gas_Rx" SG_ 1068 Shed_Drain_Eng_Off_B_UB 1;
BA_ "U_C490_MY18_Rx" SG_ 1068 Shed_Drain_Eng_Off_B_UB 1;
BA_ "U_B562_MY18_Gas_Rx" SG_ 1068 Shed_Drain_Eng_Off_B_UB 1;
BA_ "U_P702_MY2021_Rx" SG_ 1068 Shed_Drain_Eng_Off_B_UB 1;
BA_ "U_CX430_MY2021_Rx" SG_ 1068 Shed_Drain_Eng_Off_B_UB 1;
BA_ "U_U611_U625_MY20_Phev_Rx" SG_ 1068 Shed_Drain_Eng_Off_B_UB 1;
BA_ "U_CX482_CX483_MY20_Rx" SG_ 1068 Shed_Drain_Eng_Off_B_UB 1;
BA_ "U_U611_U625_MY20_Gas_Rx" SG_ 1068 Shed_Drain_Eng_Off_B_UB 1;
BA_ "U_C519_MY18_5_Gas_Rx" SG_ 1068 Shed_Drain_Eng_Off_B_UB 1;
BA_ "U_C519_MY18_5_Diesel_Rx" SG_ 1068 Shed_Drain_Eng_Off_B_UB 1;
BA_ "U_B515_MCA_MY17_Gas_Rx" SG_ 1068 Shed_Drain_Eng_Off_B_UB 1;
BA_ "U_B515_MCA_MY17_Diesel_Rx" SG_ 1068 Shed_Drain_Eng_Off_B_UB 1;
BA_ "U_B479_MY17_Diesel_Rx" SG_ 1068 Shed_Drain_Eng_Off_B_UB 1;
BA_ "U_B479_MY17_Gas_Rx" SG_ 1068 Shed_Drain_Eng_Off_B_UB 1;
BA_ "CrossOver_InfoCAN" SG_ 1068 Shed_Drain_Eng_Off_B_UB 1;
BA_ "GenSigSendType" SG_ 1068 Shed_Drain_Eng_Off_B 3;
BA_ "U_CX727_MY2021_Rx" SG_ 1068 Shed_Drain_Eng_Off_B 1;
BA_ "U_H567_MY20_Rx" SG_ 1068 Shed_Drain_Eng_Off_B 1;
BA_ "U_B562_MY18_Diesel_Rx" SG_ 1068 Shed_Drain_Eng_Off_B 1;
BA_ "U_U611_U625_MY20_Hev_Rx" SG_ 1068 Shed_Drain_Eng_Off_B 1;
BA_ "U_B500_MY18_Diesel_Rx" SG_ 1068 Shed_Drain_Eng_Off_B 1;
BA_ "U_B500_MY18_Gas_Rx" SG_ 1068 Shed_Drain_Eng_Off_B 1;
BA_ "U_C490_MY18_Rx" SG_ 1068 Shed_Drain_Eng_Off_B 1;
BA_ "U_B562_MY18_Gas_Rx" SG_ 1068 Shed_Drain_Eng_Off_B 1;
BA_ "U_P702_MY2021_Rx" SG_ 1068 Shed_Drain_Eng_Off_B 1;
BA_ "U_CX430_MY2021_Rx" SG_ 1068 Shed_Drain_Eng_Off_B 1;
BA_ "U_U611_U625_MY20_Phev_Rx" SG_ 1068 Shed_Drain_Eng_Off_B 1;
BA_ "U_CX482_CX483_MY20_Rx" SG_ 1068 Shed_Drain_Eng_Off_B 1;
BA_ "U_U611_U625_MY20_Gas_Rx" SG_ 1068 Shed_Drain_Eng_Off_B 1;
BA_ "U_C519_MY18_5_Gas_Rx" SG_ 1068 Shed_Drain_Eng_Off_B 1;
BA_ "U_C519_MY18_5_Diesel_Rx" SG_ 1068 Shed_Drain_Eng_Off_B 1;
BA_ "U_B515_MCA_MY17_Gas_Rx" SG_ 1068 Shed_Drain_Eng_Off_B 1;
BA_ "U_B515_MCA_MY17_Diesel_Rx" SG_ 1068 Shed_Drain_Eng_Off_B 1;
BA_ "U_B479_MY17_Diesel_Rx" SG_ 1068 Shed_Drain_Eng_Off_B 1;
BA_ "U_B479_MY17_Gas_Rx" SG_ 1068 Shed_Drain_Eng_Off_B 1;
BA_ "CrossOver_InfoCAN" SG_ 1068 Shed_Drain_Eng_Off_B 1;
BA_ "GenSigSendType" SG_ 1068 AirCondRec_B_Rq_UB 3;
BA_ "U_P702_MY2021_Rx" SG_ 1068 AirCondRec_B_Rq_UB 1;
BA_ "U_CX727_MY2021_Rx" SG_ 1068 AirCondRec_B_Rq_UB 1;
BA_ "U_H567_MY20_Rx" SG_ 1068 AirCondRec_B_Rq_UB 1;
BA_ "U_CX430_MY2021_Rx" SG_ 1068 AirCondRec_B_Rq_UB 1;
BA_ "U_U611_U625_MY20_Phev_Rx" SG_ 1068 AirCondRec_B_Rq_UB 1;
BA_ "U_B562_MY18_Diesel_Rx" SG_ 1068 AirCondRec_B_Rq_UB 1;
BA_ "U_CX482_CX483_MY20_Rx" SG_ 1068 AirCondRec_B_Rq_UB 1;
BA_ "U_U611_U625_MY20_Hev_Rx" SG_ 1068 AirCondRec_B_Rq_UB 1;
BA_ "U_U611_U625_MY20_Gas_Rx" SG_ 1068 AirCondRec_B_Rq_UB 1;
BA_ "U_B500_MY18_Diesel_Rx" SG_ 1068 AirCondRec_B_Rq_UB 1;
BA_ "U_B500_MY18_Gas_Rx" SG_ 1068 AirCondRec_B_Rq_UB 1;
BA_ "U_C490_MY18_Rx" SG_ 1068 AirCondRec_B_Rq_UB 1;
BA_ "U_B562_MY18_Gas_Rx" SG_ 1068 AirCondRec_B_Rq_UB 1;
BA_ "U_C519_MY18_5_Gas_Rx" SG_ 1068 AirCondRec_B_Rq_UB 1;
BA_ "U_C519_MY18_5_Diesel_Rx" SG_ 1068 AirCondRec_B_Rq_UB 1;
BA_ "U_B515_MCA_MY17_Gas_Rx" SG_ 1068 AirCondRec_B_Rq_UB 1;
BA_ "U_B515_MCA_MY17_Diesel_Rx" SG_ 1068 AirCondRec_B_Rq_UB 1;
BA_ "U_B479_MY17_Diesel_Rx" SG_ 1068 AirCondRec_B_Rq_UB 1;
BA_ "U_B479_MY17_Gas_Rx" SG_ 1068 AirCondRec_B_Rq_UB 1;
BA_ "GenSigSendType" SG_ 1068 AirCondFluidHi_P_Actl_UB 3;
BA_ "U_P702_MY2021_Rx" SG_ 1068 AirCondFluidHi_P_Actl_UB 1;
BA_ "U_CX727_MY2021_Rx" SG_ 1068 AirCondFluidHi_P_Actl_UB 1;
BA_ "U_H567_MY20_Rx" SG_ 1068 AirCondFluidHi_P_Actl_UB 1;
BA_ "U_CX430_MY2021_Rx" SG_ 1068 AirCondFluidHi_P_Actl_UB 1;
BA_ "U_U611_U625_MY20_Phev_Rx" SG_ 1068 AirCondFluidHi_P_Actl_UB 1;
BA_ "U_CX482_CX483_MY20_Rx" SG_ 1068 AirCondFluidHi_P_Actl_UB 1;
BA_ "U_U611_U625_MY20_Hev_Rx" SG_ 1068 AirCondFluidHi_P_Actl_UB 1;
BA_ "U_U611_U625_MY20_Gas_Rx" SG_ 1068 AirCondFluidHi_P_Actl_UB 1;
BA_ "U_B500_MY18_Diesel_Rx" SG_ 1068 AirCondFluidHi_P_Actl_UB 1;
BA_ "U_B500_MY18_Gas_Rx" SG_ 1068 AirCondFluidHi_P_Actl_UB 1;
BA_ "U_C519_MY18_5_Gas_Rx" SG_ 1068 AirCondFluidHi_P_Actl_UB 1;
BA_ "U_C519_MY18_5_Diesel_Rx" SG_ 1068 AirCondFluidHi_P_Actl_UB 1;
BA_ "U_B515_MCA_MY17_Gas_Rx" SG_ 1068 AirCondFluidHi_P_Actl_UB 1;
BA_ "U_B515_MCA_MY17_Diesel_Rx" SG_ 1068 AirCondFluidHi_P_Actl_UB 1;
BA_ "U_B479_MY17_Diesel_Rx" SG_ 1068 AirCondFluidHi_P_Actl_UB 1;
BA_ "U_B479_MY17_Gas_Rx" SG_ 1068 AirCondFluidHi_P_Actl_UB 1;
BA_ "GenSigSendType" SG_ 1068 AirCondFluidHi_P_Actl 3;
BA_ "U_P702_MY2021_Rx" SG_ 1068 AirCondFluidHi_P_Actl 1;
BA_ "U_CX727_MY2021_Rx" SG_ 1068 AirCondFluidHi_P_Actl 1;
BA_ "U_H567_MY20_Rx" SG_ 1068 AirCondFluidHi_P_Actl 1;
BA_ "U_CX430_MY2021_Rx" SG_ 1068 AirCondFluidHi_P_Actl 1;
BA_ "U_U611_U625_MY20_Phev_Rx" SG_ 1068 AirCondFluidHi_P_Actl 1;
BA_ "U_CX482_CX483_MY20_Rx" SG_ 1068 AirCondFluidHi_P_Actl 1;
BA_ "U_U611_U625_MY20_Hev_Rx" SG_ 1068 AirCondFluidHi_P_Actl 1;
BA_ "U_U611_U625_MY20_Gas_Rx" SG_ 1068 AirCondFluidHi_P_Actl 1;
BA_ "U_B500_MY18_Diesel_Rx" SG_ 1068 AirCondFluidHi_P_Actl 1;
BA_ "U_B500_MY18_Gas_Rx" SG_ 1068 AirCondFluidHi_P_Actl 1;
BA_ "U_C519_MY18_5_Gas_Rx" SG_ 1068 AirCondFluidHi_P_Actl 1;
BA_ "U_C519_MY18_5_Diesel_Rx" SG_ 1068 AirCondFluidHi_P_Actl 1;
BA_ "U_B515_MCA_MY17_Gas_Rx" SG_ 1068 AirCondFluidHi_P_Actl 1;
BA_ "U_B515_MCA_MY17_Diesel_Rx" SG_ 1068 AirCondFluidHi_P_Actl 1;
BA_ "U_B479_MY17_Diesel_Rx" SG_ 1068 AirCondFluidHi_P_Actl 1;
BA_ "U_B479_MY17_Gas_Rx" SG_ 1068 AirCondFluidHi_P_Actl 1;
BA_ "CrossOver_InfoCAN" SG_ 1068 AirCondFluidHi_P_Actl 1;
BA_ "GenSigSendType" SG_ 1068 AirCondClutch_B_Stats 3;
BA_ "U_P702_MY2021_Rx" SG_ 1068 AirCondClutch_B_Stats 1;
BA_ "U_CX727_MY2021_Rx" SG_ 1068 AirCondClutch_B_Stats 1;
BA_ "U_H567_MY20_Rx" SG_ 1068 AirCondClutch_B_Stats 1;
BA_ "U_CX430_MY2021_Rx" SG_ 1068 AirCondClutch_B_Stats 1;
BA_ "U_U611_U625_MY20_Phev_Rx" SG_ 1068 AirCondClutch_B_Stats 1;
BA_ "U_B562_MY18_Diesel_Rx" SG_ 1068 AirCondClutch_B_Stats 1;
BA_ "U_CX482_CX483_MY20_Rx" SG_ 1068 AirCondClutch_B_Stats 1;
BA_ "U_U611_U625_MY20_Hev_Rx" SG_ 1068 AirCondClutch_B_Stats 1;
BA_ "U_U611_U625_MY20_Gas_Rx" SG_ 1068 AirCondClutch_B_Stats 1;
BA_ "U_B500_MY18_Diesel_Rx" SG_ 1068 AirCondClutch_B_Stats 1;
BA_ "U_B500_MY18_Gas_Rx" SG_ 1068 AirCondClutch_B_Stats 1;
BA_ "U_C490_MY18_Rx" SG_ 1068 AirCondClutch_B_Stats 1;
BA_ "U_B562_MY18_Gas_Rx" SG_ 1068 AirCondClutch_B_Stats 1;
BA_ "U_C519_MY18_5_Gas_Rx" SG_ 1068 AirCondClutch_B_Stats 1;
BA_ "U_C519_MY18_5_Diesel_Rx" SG_ 1068 AirCondClutch_B_Stats 1;
BA_ "U_B515_MCA_MY17_Gas_Rx" SG_ 1068 AirCondClutch_B_Stats 1;
BA_ "U_B515_MCA_MY17_Diesel_Rx" SG_ 1068 AirCondClutch_B_Stats 1;
BA_ "U_B479_MY17_Diesel_Rx" SG_ 1068 AirCondClutch_B_Stats 1;
BA_ "U_B479_MY17_Gas_Rx" SG_ 1068 AirCondClutch_B_Stats 1;
BA_ "ContentDependant" SG_ 1068 AirCondClutch_B_Stats 1;
BA_ "CrossOver_InfoCAN" SG_ 1068 AirCondClutch_B_Stats 1;
BA_ "GenSigSendType" SG_ 1068 AirCondClutch_B_Stats_UB 3;
BA_ "U_P702_MY2021_Rx" SG_ 1068 AirCondClutch_B_Stats_UB 1;
BA_ "U_CX727_MY2021_Rx" SG_ 1068 AirCondClutch_B_Stats_UB 1;
BA_ "U_H567_MY20_Rx" SG_ 1068 AirCondClutch_B_Stats_UB 1;
BA_ "U_CX430_MY2021_Rx" SG_ 1068 AirCondClutch_B_Stats_UB 1;
BA_ "U_U611_U625_MY20_Phev_Rx" SG_ 1068 AirCondClutch_B_Stats_UB 1;
BA_ "U_B562_MY18_Diesel_Rx" SG_ 1068 AirCondClutch_B_Stats_UB 1;
BA_ "U_CX482_CX483_MY20_Rx" SG_ 1068 AirCondClutch_B_Stats_UB 1;
BA_ "U_U611_U625_MY20_Hev_Rx" SG_ 1068 AirCondClutch_B_Stats_UB 1;
BA_ "U_U611_U625_MY20_Gas_Rx" SG_ 1068 AirCondClutch_B_Stats_UB 1;
BA_ "U_B500_MY18_Diesel_Rx" SG_ 1068 AirCondClutch_B_Stats_UB 1;
BA_ "U_B500_MY18_Gas_Rx" SG_ 1068 AirCondClutch_B_Stats_UB 1;
BA_ "U_C490_MY18_Rx" SG_ 1068 AirCondClutch_B_Stats_UB 1;
BA_ "U_B562_MY18_Gas_Rx" SG_ 1068 AirCondClutch_B_Stats_UB 1;
BA_ "U_C519_MY18_5_Gas_Rx" SG_ 1068 AirCondClutch_B_Stats_UB 1;
BA_ "U_C519_MY18_5_Diesel_Rx" SG_ 1068 AirCondClutch_B_Stats_UB 1;
BA_ "U_B515_MCA_MY17_Gas_Rx" SG_ 1068 AirCondClutch_B_Stats_UB 1;
BA_ "U_B515_MCA_MY17_Diesel_Rx" SG_ 1068 AirCondClutch_B_Stats_UB 1;
BA_ "U_B479_MY17_Diesel_Rx" SG_ 1068 AirCondClutch_B_Stats_UB 1;
BA_ "U_B479_MY17_Gas_Rx" SG_ 1068 AirCondClutch_B_Stats_UB 1;
BA_ "GenSigSendType" SG_ 1068 AirCondRec_B_Rq 3;
BA_ "U_P702_MY2021_Rx" SG_ 1068 AirCondRec_B_Rq 1;
BA_ "U_CX727_MY2021_Rx" SG_ 1068 AirCondRec_B_Rq 1;
BA_ "U_H567_MY20_Rx" SG_ 1068 AirCondRec_B_Rq 1;
BA_ "U_CX430_MY2021_Rx" SG_ 1068 AirCondRec_B_Rq 1;
BA_ "U_U611_U625_MY20_Phev_Rx" SG_ 1068 AirCondRec_B_Rq 1;
BA_ "U_B562_MY18_Diesel_Rx" SG_ 1068 AirCondRec_B_Rq 1;
BA_ "U_CX482_CX483_MY20_Rx" SG_ 1068 AirCondRec_B_Rq 1;
BA_ "U_U611_U625_MY20_Hev_Rx" SG_ 1068 AirCondRec_B_Rq 1;
BA_ "U_U611_U625_MY20_Gas_Rx" SG_ 1068 AirCondRec_B_Rq 1;
BA_ "U_B500_MY18_Diesel_Rx" SG_ 1068 AirCondRec_B_Rq 1;
BA_ "U_B500_MY18_Gas_Rx" SG_ 1068 AirCondRec_B_Rq 1;
BA_ "U_C490_MY18_Rx" SG_ 1068 AirCondRec_B_Rq 1;
BA_ "U_B562_MY18_Gas_Rx" SG_ 1068 AirCondRec_B_Rq 1;
BA_ "U_C519_MY18_5_Gas_Rx" SG_ 1068 AirCondRec_B_Rq 1;
BA_ "U_C519_MY18_5_Diesel_Rx" SG_ 1068 AirCondRec_B_Rq 1;
BA_ "U_B515_MCA_MY17_Gas_Rx" SG_ 1068 AirCondRec_B_Rq 1;
BA_ "U_B515_MCA_MY17_Diesel_Rx" SG_ 1068 AirCondRec_B_Rq 1;
BA_ "U_B479_MY17_Diesel_Rx" SG_ 1068 AirCondRec_B_Rq 1;
BA_ "U_B479_MY17_Gas_Rx" SG_ 1068 AirCondRec_B_Rq 1;
BA_ "ContentDependant" SG_ 1068 AirCondRec_B_Rq 1;
BA_ "CrossOver_InfoCAN" SG_ 1068 AirCondRec_B_Rq 1;
BA_ "CrossOver_InfoCAN" SG_ 963 ImpactEvntFdbck_D_Stat 1;
BA_ "WakeupSignal" SG_ 963 ImpactEvntFdbck_D_Stat 1;
BA_ "U_P702_MY2021_Rx" SG_ 963 PudLampPsngr_D_Rq 1;
BA_ "U_CX430_MY2021_Rx" SG_ 963 PudLampPsngr_D_Rq 1;
BA_ "U_U611_U625_MY20_Phev_Rx" SG_ 963 PudLampPsngr_D_Rq 1;
BA_ "U_CX482_CX483_MY20_Rx" SG_ 963 PudLampPsngr_D_Rq 1;
BA_ "U_U611_U625_MY20_Hev_Rx" SG_ 963 PudLampPsngr_D_Rq 1;
BA_ "U_U611_U625_MY20_Gas_Rx" SG_ 963 PudLampPsngr_D_Rq 1;
BA_ "U_C519_MY18_5_Gas_Rx" SG_ 963 PudLampPsngr_D_Rq 1;
BA_ "U_C519_MY18_5_Diesel_Rx" SG_ 963 PudLampPsngr_D_Rq 1;
BA_ "U_B515_MCA_MY17_Gas_Rx" SG_ 963 PudLampPsngr_D_Rq 1;
BA_ "U_B515_MCA_MY17_Diesel_Rx" SG_ 963 PudLampPsngr_D_Rq 1;
BA_ "U_B479_MY17_Diesel_Rx" SG_ 963 PudLampPsngr_D_Rq 1;
BA_ "U_B479_MY17_Gas_Rx" SG_ 963 PudLampPsngr_D_Rq 1;
BA_ "CrossOver_InfoCAN" SG_ 963 HeadLampLoOut_B_Stat 1;
BA_ "CrossOver_InfoCAN" SG_ 963 CrnrLghtRight_Pc_Rq 1;
BA_ "CrossOver_InfoCAN" SG_ 963 CrnrLghtLeft_Pc_Rq 1;
BA_ "CrossOver_InfoCAN" SG_ 963 HeadLghtHiFdbck_D_Stat 1;
BA_ "CrossOver_InfoCAN" SG_ 963 PrkLightChime_B_Rq 1;
BA_ "CrossOver_InfoCAN" SG_ 963 TrnNotInPrkChime_B_Rq 1;
BA_ "CrossOver_InfoCAN" SG_ 963 HomeSafeLtChime_B_Rq 1;
BA_ "WakeupSignal" SG_ 963 HomeSafeLtChime_B_Rq 1;
BA_ "U_CX727_MY2021_Rx" SG_ 963 StopLghtOn_B_Stat 1;
BA_ "U_P702_MY2021_Rx" SG_ 963 StopLghtOn_B_Stat 1;
BA_ "U_CX430_MY2021_Rx" SG_ 963 StopLghtOn_B_Stat 1;
BA_ "U_U611_U625_MY20_Phev_Rx" SG_ 963 StopLghtOn_B_Stat 1;
BA_ "U_CX482_CX483_MY20_Rx" SG_ 963 StopLghtOn_B_Stat 1;
BA_ "U_U611_U625_MY20_Gas_Rx" SG_ 963 StopLghtOn_B_Stat 1;
BA_ "U_C519_MY18_5_Gas_Rx" SG_ 963 StopLghtOn_B_Stat 1;
BA_ "U_C519_MY18_5_Diesel_Rx" SG_ 963 StopLghtOn_B_Stat 1;
BA_ "U_B515_MCA_MY17_Gas_Rx" SG_ 963 StopLghtOn_B_Stat 1;
BA_ "U_B515_MCA_MY17_Diesel_Rx" SG_ 963 StopLghtOn_B_Stat 1;
BA_ "U_B479_MY17_Diesel_Rx" SG_ 963 StopLghtOn_B_Stat 1;
BA_ "U_B479_MY17_Gas_Rx" SG_ 963 StopLghtOn_B_Stat 1;
BA_ "CrossOver_InfoCAN" SG_ 963 StopLghtOn_B_Stat 1;
BA_ "WakeupSignal" SG_ 963 StopLghtOn_B_Stat 1;
BA_ "U_P702_MY2021_Rx" SG_ 963 RvrseLghtOn_B_Stat 1;
BA_ "U_CX430_MY2021_Rx" SG_ 963 RvrseLghtOn_B_Stat 1;
BA_ "U_U611_U625_MY20_Phev_Rx" SG_ 963 RvrseLghtOn_B_Stat 1;
BA_ "U_CX482_CX483_MY20_Rx" SG_ 963 RvrseLghtOn_B_Stat 1;
BA_ "U_U611_U625_MY20_Gas_Rx" SG_ 963 RvrseLghtOn_B_Stat 1;
BA_ "U_C519_MY18_5_Gas_Rx" SG_ 963 RvrseLghtOn_B_Stat 1;
BA_ "U_C519_MY18_5_Diesel_Rx" SG_ 963 RvrseLghtOn_B_Stat 1;
BA_ "U_B515_MCA_MY17_Gas_Rx" SG_ 963 RvrseLghtOn_B_Stat 1;
BA_ "U_B515_MCA_MY17_Diesel_Rx" SG_ 963 RvrseLghtOn_B_Stat 1;
BA_ "U_B479_MY17_Diesel_Rx" SG_ 963 RvrseLghtOn_B_Stat 1;
BA_ "U_B479_MY17_Gas_Rx" SG_ 963 RvrseLghtOn_B_Stat 1;
BA_ "CrossOver_InfoCAN" SG_ 963 RvrseLghtOn_B_Stat 1;
BA_ "U_P702_MY2021_Rx" SG_ 963 PrkLght_D_Stat 1;
BA_ "U_CX430_MY2021_Rx" SG_ 963 PrkLght_D_Stat 1;
BA_ "U_U611_U625_MY20_Phev_Rx" SG_ 963 PrkLght_D_Stat 1;
BA_ "U_CX482_CX483_MY20_Rx" SG_ 963 PrkLght_D_Stat 1;
BA_ "U_U611_U625_MY20_Gas_Rx" SG_ 963 PrkLght_D_Stat 1;
BA_ "U_C519_MY18_5_Gas_Rx" SG_ 963 PrkLght_D_Stat 1;
BA_ "U_C519_MY18_5_Diesel_Rx" SG_ 963 PrkLght_D_Stat 1;
BA_ "U_B515_MCA_MY17_Gas_Rx" SG_ 963 PrkLght_D_Stat 1;
BA_ "U_B515_MCA_MY17_Diesel_Rx" SG_ 963 PrkLght_D_Stat 1;
BA_ "U_B479_MY17_Diesel_Rx" SG_ 963 PrkLght_D_Stat 1;
BA_ "U_B479_MY17_Gas_Rx" SG_ 963 PrkLght_D_Stat 1;
BA_ "CrossOver_InfoCAN" SG_ 963 PrkLght_D_Stat 1;
BA_ "WakeupSignal" SG_ 963 PrkLght_D_Stat 1;
BA_ "GenSigStartValue" SG_ 963 HeadLghtSwtch_D_Stat 2;
BA_ "GenSigStartValueInteger" SG_ 963 HeadLghtSwtch_D_Stat 2;
BA_ "CrossOver_InfoCAN" SG_ 963 HeadLghtSwtch_D_Stat 1;
BA_ "WakeupSignal" SG_ 963 HeadLghtSwtch_D_Stat 1;
BA_ "CrossOver_InfoCAN" SG_ 963 KeyInIgnWarn_B_Cmd 1;
BA_ "WakeupSignal" SG_ 963 KeyInIgnWarn_B_Cmd 1;
BA_ "GenSigStartValue" SG_ 963 HeadLampLoFrOn_B_Stat 1;
BA_ "GenSigStartValueInteger" SG_ 963 HeadLampLoFrOn_B_Stat 1;
BA_ "CrossOver_InfoCAN" SG_ 963 HeadLampLoFrOn_B_Stat 1;
BA_ "GenSigStartValue" SG_ 963 HeadLampLoFlOn_B_Stat 1;
BA_ "GenSigStartValueInteger" SG_ 963 HeadLampLoFlOn_B_Stat 1;
BA_ "CrossOver_InfoCAN" SG_ 963 HeadLampLoFlOn_B_Stat 1;
BA_ "CrossOver_InfoCAN" SG_ 963 Headlamp_On_Wrning_Cmd 1;
BA_ "WakeupSignal" SG_ 963 Headlamp_On_Wrning_Cmd 1;
BA_ "GenSigStartValue" SG_ 963 HeadLampLoActv_B_Stat 1;
BA_ "GenSigStartValueInteger" SG_ 963 HeadLampLoActv_B_Stat 1;
BA_ "CrossOver_InfoCAN" SG_ 963 HeadLampLoActv_B_Stat 1;
BA_ "CrossOver_InfoCAN" SG_ 963 HeadLghtHiOn_B_Stat 1;
BA_ "WakeupSignal" SG_ 963 HeadLghtHiOn_B_Stat 1;
BA_ "CrossOver_InfoCAN" SG_ 963 Park_Brake_Chime_Rqst 1;
BA_ "CrossOver_InfoCAN" SG_ 963 BrkWarnInd_B_Rq 1;
BA_ "WakeupSignal" SG_ 963 BrkWarnInd_B_Rq 1;
BA_ "CrossOver_InfoCAN" SG_ 963 Brk_Fluid_Lvl_Low 1;
BA_ "CrossOver_InfoCAN" SG_ 963 ReducedGuard_D_Stat 1;
BA_ "U_CX727_MY2021_Rx" SG_ 963 Courtesy_BSave_Stat 1;
BA_ "U_P702_MY2021_Rx" SG_ 963 Courtesy_BSave_Stat 1;
BA_ "U_CX430_MY2021_Rx" SG_ 963 Courtesy_BSave_Stat 1;
BA_ "U_U611_U625_MY20_Phev_Rx" SG_ 963 Courtesy_BSave_Stat 1;
BA_ "U_CX482_CX483_MY20_Rx" SG_ 963 Courtesy_BSave_Stat 1;
BA_ "U_U611_U625_MY20_Hev_Rx" SG_ 963 Courtesy_BSave_Stat 1;
BA_ "U_U611_U625_MY20_Gas_Rx" SG_ 963 Courtesy_BSave_Stat 1;
BA_ "U_C490_MY18_Rx" SG_ 963 Courtesy_BSave_Stat 1;
BA_ "U_C519_MY18_5_Gas_Rx" SG_ 963 Courtesy_BSave_Stat 1;
BA_ "U_C519_MY18_5_Diesel_Rx" SG_ 963 Courtesy_BSave_Stat 1;
BA_ "U_B515_MCA_MY17_Gas_Rx" SG_ 963 Courtesy_BSave_Stat 1;
BA_ "U_B515_MCA_MY17_Diesel_Rx" SG_ 963 Courtesy_BSave_Stat 1;
BA_ "U_B479_MY17_Diesel_Rx" SG_ 963 Courtesy_BSave_Stat 1;
BA_ "U_B479_MY17_Gas_Rx" SG_ 963 Courtesy_BSave_Stat 1;
BA_ "GenSigStartValue" SG_ 963 Courtesy_BSave_Stat 1;
BA_ "GenSigStartValueInteger" SG_ 963 Courtesy_BSave_Stat 1;
BA_ "CrossOver_InfoCAN" SG_ 963 Courtesy_BSave_Stat 1;
BA_ "WakeupSignal" SG_ 963 Courtesy_BSave_Stat 1;
BA_ "CrossOver_InfoCAN" SG_ 963 DayRnngLampOn_B_Stat 1;
BA_ "CrossOver_InfoCAN" SG_ 963 PerimeterAlarmChimeRq 1;
BA_ "WakeupSignal" SG_ 963 PerimeterAlarmChimeRq 1;
BA_ "U_P702_MY2021_Rx" SG_ 963 PudLampDrv_D_Rq 1;
BA_ "U_CX727_MY2021_Rx" SG_ 963 PudLampDrv_D_Rq 1;
BA_ "U_CX430_MY2021_Rx" SG_ 963 PudLampDrv_D_Rq 1;
BA_ "U_U611_U625_MY20_Phev_Rx" SG_ 963 PudLampDrv_D_Rq 1;
BA_ "U_CX482_CX483_MY20_Rx" SG_ 963 PudLampDrv_D_Rq 1;
BA_ "U_U611_U625_MY20_Hev_Rx" SG_ 963 PudLampDrv_D_Rq 1;
BA_ "U_U611_U625_MY20_Gas_Rx" SG_ 963 PudLampDrv_D_Rq 1;
BA_ "U_C490_MY18_Rx" SG_ 963 PudLampDrv_D_Rq 1;
BA_ "U_C519_MY18_5_Gas_Rx" SG_ 963 PudLampDrv_D_Rq 1;
BA_ "U_C519_MY18_5_Diesel_Rx" SG_ 963 PudLampDrv_D_Rq 1;
BA_ "U_B515_MCA_MY17_Gas_Rx" SG_ 963 PudLampDrv_D_Rq 1;
BA_ "U_B515_MCA_MY17_Diesel_Rx" SG_ 963 PudLampDrv_D_Rq 1;
BA_ "U_B479_MY17_Diesel_Rx" SG_ 963 PudLampDrv_D_Rq 1;
BA_ "U_B479_MY17_Gas_Rx" SG_ 963 PudLampDrv_D_Rq 1;
BA_ "U_CX727_MY2021_Rx" SG_ 963 Perimeter_Alarm_Status 1;
BA_ "U_CX430_MY2021_Rx" SG_ 963 Perimeter_Alarm_Status 1;
BA_ "U_CX482_CX483_MY20_Rx" SG_ 963 Perimeter_Alarm_Status 1;
BA_ "U_C519_MY18_5_Gas_Rx" SG_ 963 Perimeter_Alarm_Status 1;
BA_ "U_C519_MY18_5_Diesel_Rx" SG_ 963 Perimeter_Alarm_Status 1;
BA_ "U_B515_MCA_MY17_Gas_Rx" SG_ 963 Perimeter_Alarm_Status 1;
BA_ "U_B515_MCA_MY17_Diesel_Rx" SG_ 963 Perimeter_Alarm_Status 1;
BA_ "CrossOver_InfoCAN" SG_ 963 Perimeter_Alarm_Status 1;
BA_ "WakeupSignal" SG_ 963 Perimeter_Alarm_Status 1;
BA_ "U_CX727_MY2021_Rx" SG_ 963 WndwGlbl_D_Cmd 1;
BA_ "U_P702_MY2021_Rx" SG_ 963 WndwGlbl_D_Cmd 1;
BA_ "U_CX430_MY2021_Rx" SG_ 963 WndwGlbl_D_Cmd 1;
BA_ "U_U611_U625_MY20_Phev_Rx" SG_ 963 WndwGlbl_D_Cmd 1;
BA_ "U_CX482_CX483_MY20_Rx" SG_ 963 WndwGlbl_D_Cmd 1;
BA_ "U_U611_U625_MY20_Hev_Rx" SG_ 963 WndwGlbl_D_Cmd 1;
BA_ "U_U611_U625_MY20_Gas_Rx" SG_ 963 WndwGlbl_D_Cmd 1;
BA_ "U_C490_MY18_Rx" SG_ 963 WndwGlbl_D_Cmd 1;
BA_ "U_C519_MY18_5_Gas_Rx" SG_ 963 WndwGlbl_D_Cmd 1;
BA_ "U_C519_MY18_5_Diesel_Rx" SG_ 963 WndwGlbl_D_Cmd 1;
BA_ "U_B515_MCA_MY17_Gas_Rx" SG_ 963 WndwGlbl_D_Cmd 1;
BA_ "U_B515_MCA_MY17_Diesel_Rx" SG_ 963 WndwGlbl_D_Cmd 1;
BA_ "U_B479_MY17_Diesel_Rx" SG_ 963 WndwGlbl_D_Cmd 1;
BA_ "U_B479_MY17_Gas_Rx" SG_ 963 WndwGlbl_D_Cmd 1;
BA_ "CrossOver_InfoCAN" SG_ 963 WndwGlbl_D_Cmd 1;
BA_ "WakeupSignal" SG_ 963 WndwGlbl_D_Cmd 1;
BA_ "U_CX727_MY2021_Rx" SG_ 963 PudLamp_D_Rq 1;
BA_ "U_P702_MY2021_Rx" SG_ 963 PudLamp_D_Rq 1;
BA_ "U_CX430_MY2021_Rx" SG_ 963 PudLamp_D_Rq 1;
BA_ "U_U611_U625_MY20_Phev_Rx" SG_ 963 PudLamp_D_Rq 1;
BA_ "U_CX482_CX483_MY20_Rx" SG_ 963 PudLamp_D_Rq 1;
BA_ "U_U611_U625_MY20_Hev_Rx" SG_ 963 PudLamp_D_Rq 1;
BA_ "U_U611_U625_MY20_Gas_Rx" SG_ 963 PudLamp_D_Rq 1;
BA_ "U_C490_MY18_Rx" SG_ 963 PudLamp_D_Rq 1;
BA_ "U_C519_MY18_5_Gas_Rx" SG_ 963 PudLamp_D_Rq 1;
BA_ "U_C519_MY18_5_Diesel_Rx" SG_ 963 PudLamp_D_Rq 1;
BA_ "U_B515_MCA_MY17_Gas_Rx" SG_ 963 PudLamp_D_Rq 1;
BA_ "U_B515_MCA_MY17_Diesel_Rx" SG_ 963 PudLamp_D_Rq 1;
BA_ "U_B479_MY17_Diesel_Rx" SG_ 963 PudLamp_D_Rq 1;
BA_ "U_B479_MY17_Gas_Rx" SG_ 963 PudLamp_D_Rq 1;
BA_ "CrossOver_InfoCAN" SG_ 963 PudLamp_D_Rq 1;
BA_ "WakeupSignal" SG_ 963 PudLamp_D_Rq 1;
BA_ "U_CX482_CX483_MY20_Rx" SG_ 964 FohEng_D_Rq_UB 1;
BA_ "U_C519_MY18_5_Gas_Rx" SG_ 964 FohEng_D_Rq_UB 1;
BA_ "U_C519_MY18_5_Diesel_Rx" SG_ 964 FohEng_D_Rq_UB 1;
BA_ "U_CX482_CX483_MY20_Rx" SG_ 964 FohEng_D_Rq 1;
BA_ "U_C519_MY18_5_Gas_Rx" SG_ 964 FohEng_D_Rq 1;
BA_ "U_C519_MY18_5_Diesel_Rx" SG_ 964 FohEng_D_Rq 1;
BA_ "GenSigSendType" SG_ 964 FohEng_D_Rq 3;
BA_ "GenSigStartValue" SG_ 964 FohEng_D_Rq 2;
BA_ "ContentDependant" SG_ 964 FohEng_D_Rq 1;
BA_ "GenSigStartValueInteger" SG_ 964 FohEng_D_Rq 2;
BA_ "CrossOver_InfoCAN" SG_ 964 FohEng_D_Rq 1;
BA_ "U_CX727_MY2021_Rx" SG_ 964 Cta_D_Rq_UB 1;
BA_ "U_CX430_MY2021_Rx" SG_ 964 Cta_D_Rq_UB 1;
BA_ "U_U611_U625_MY20_Phev_Rx" SG_ 964 Cta_D_Rq_UB 1;
BA_ "U_CX482_CX483_MY20_Rx" SG_ 964 Cta_D_Rq_UB 1;
BA_ "U_U611_U625_MY20_Hev_Rx" SG_ 964 Cta_D_Rq_UB 1;
BA_ "U_U611_U625_MY20_Gas_Rx" SG_ 964 Cta_D_Rq_UB 1;
BA_ "U_C519_MY18_5_Gas_Rx" SG_ 964 Cta_D_Rq_UB 1;
BA_ "U_C519_MY18_5_Diesel_Rx" SG_ 964 Cta_D_Rq_UB 1;
BA_ "U_B515_MCA_MY17_Gas_Rx" SG_ 964 Cta_D_Rq_UB 1;
BA_ "U_B515_MCA_MY17_Diesel_Rx" SG_ 964 Cta_D_Rq_UB 1;
BA_ "U_B479_MY17_Diesel_Rx" SG_ 964 Cta_D_Rq_UB 1;
BA_ "U_B479_MY17_Gas_Rx" SG_ 964 Cta_D_Rq_UB 1;
BA_ "U_B562LC_MY15_Gas_Rx" SG_ 964 Cta_D_Rq_UB 1;
BA_ "U_CX727_MY2021_Rx" SG_ 964 Cta_D_Rq 1;
BA_ "U_CX430_MY2021_Rx" SG_ 964 Cta_D_Rq 1;
BA_ "U_U611_U625_MY20_Phev_Rx" SG_ 964 Cta_D_Rq 1;
BA_ "U_CX482_CX483_MY20_Rx" SG_ 964 Cta_D_Rq 1;
BA_ "U_U611_U625_MY20_Hev_Rx" SG_ 964 Cta_D_Rq 1;
BA_ "U_U611_U625_MY20_Gas_Rx" SG_ 964 Cta_D_Rq 1;
BA_ "U_C519_MY18_5_Gas_Rx" SG_ 964 Cta_D_Rq 1;
BA_ "U_C519_MY18_5_Diesel_Rx" SG_ 964 Cta_D_Rq 1;
BA_ "U_B515_MCA_MY17_Gas_Rx" SG_ 964 Cta_D_Rq 1;
BA_ "U_B515_MCA_MY17_Diesel_Rx" SG_ 964 Cta_D_Rq 1;
BA_ "U_B479_MY17_Diesel_Rx" SG_ 964 Cta_D_Rq 1;
BA_ "U_B479_MY17_Gas_Rx" SG_ 964 Cta_D_Rq 1;
BA_ "U_B562LC_MY15_Gas_Rx" SG_ 964 Cta_D_Rq 1;
BA_ "GenSigSendType" SG_ 964 Cta_D_Rq 3;
BA_ "GenSigStartValue" SG_ 964 Cta_D_Rq 1;
BA_ "GenSigStartValueInteger" SG_ 964 Cta_D_Rq 1;
BA_ "CrossOver_InfoCAN" SG_ 964 Cta_D_Rq 1;
BA_ "U_B562LC_MY15_Gas_Rx" SG_ 964 GearRvrse_D_Actl_UB 1;
BA_ "U_P702_MY2021_Rx" SG_ 964 GearRvrse_D_Actl_UB 1;
BA_ "U_CX727_MY2021_Rx" SG_ 964 GearRvrse_D_Actl_UB 1;
BA_ "U_CX430_MY2021_Rx" SG_ 964 GearRvrse_D_Actl_UB 1;
BA_ "U_U611_U625_MY20_Phev_Rx" SG_ 964 GearRvrse_D_Actl_UB 1;
BA_ "U_CX482_CX483_MY20_Rx" SG_ 964 GearRvrse_D_Actl_UB 1;
BA_ "U_U611_U625_MY20_Hev_Rx" SG_ 964 GearRvrse_D_Actl_UB 1;
BA_ "U_U611_U625_MY20_Gas_Rx" SG_ 964 GearRvrse_D_Actl_UB 1;
BA_ "U_C490_MY18_Rx" SG_ 964 GearRvrse_D_Actl_UB 1;
BA_ "U_C519_MY18_5_Gas_Rx" SG_ 964 GearRvrse_D_Actl_UB 1;
BA_ "U_C519_MY18_5_Diesel_Rx" SG_ 964 GearRvrse_D_Actl_UB 1;
BA_ "U_B515_MCA_MY17_Gas_Rx" SG_ 964 GearRvrse_D_Actl_UB 1;
BA_ "U_B515_MCA_MY17_Diesel_Rx" SG_ 964 GearRvrse_D_Actl_UB 1;
BA_ "U_B479_MY17_Diesel_Rx" SG_ 964 GearRvrse_D_Actl_UB 1;
BA_ "U_B479_MY17_Gas_Rx" SG_ 964 GearRvrse_D_Actl_UB 1;
BA_ "CrossOver_InfoCAN" SG_ 964 GearRvrse_D_Actl_UB 1;
BA_ "U_B562LC_MY15_Gas_Rx" SG_ 964 GearRvrse_D_Actl 1;
BA_ "U_P702_MY2021_Rx" SG_ 964 GearRvrse_D_Actl 1;
BA_ "U_CX727_MY2021_Rx" SG_ 964 GearRvrse_D_Actl 1;
BA_ "U_CX430_MY2021_Rx" SG_ 964 GearRvrse_D_Actl 1;
BA_ "U_U611_U625_MY20_Phev_Rx" SG_ 964 GearRvrse_D_Actl 1;
BA_ "U_CX482_CX483_MY20_Rx" SG_ 964 GearRvrse_D_Actl 1;
BA_ "U_U611_U625_MY20_Hev_Rx" SG_ 964 GearRvrse_D_Actl 1;
BA_ "U_U611_U625_MY20_Gas_Rx" SG_ 964 GearRvrse_D_Actl 1;
BA_ "U_C490_MY18_Rx" SG_ 964 GearRvrse_D_Actl 1;
BA_ "U_C519_MY18_5_Gas_Rx" SG_ 964 GearRvrse_D_Actl 1;
BA_ "U_C519_MY18_5_Diesel_Rx" SG_ 964 GearRvrse_D_Actl 1;
BA_ "U_B515_MCA_MY17_Gas_Rx" SG_ 964 GearRvrse_D_Actl 1;
BA_ "U_B515_MCA_MY17_Diesel_Rx" SG_ 964 GearRvrse_D_Actl 1;
BA_ "U_B479_MY17_Diesel_Rx" SG_ 964 GearRvrse_D_Actl 1;
BA_ "U_B479_MY17_Gas_Rx" SG_ 964 GearRvrse_D_Actl 1;
BA_ "GenSigSendType" SG_ 964 GearRvrse_D_Actl 3;
BA_ "GenSigStartValue" SG_ 964 GearRvrse_D_Actl 7;
BA_ "GenSigStartValueInteger" SG_ 964 GearRvrse_D_Actl 7;
BA_ "CrossOver_InfoCAN" SG_ 964 GearRvrse_D_Actl 1;
BA_ "U_CX727_MY2021_Rx" SG_ 964 TurnLghtSwtch_D_Stat_UB 1;
BA_ "U_CX430_MY2021_Rx" SG_ 964 TurnLghtSwtch_D_Stat_UB 1;
BA_ "U_U611_U625_MY20_Phev_Rx" SG_ 964 TurnLghtSwtch_D_Stat_UB 1;
BA_ "U_CX482_CX483_MY20_Rx" SG_ 964 TurnLghtSwtch_D_Stat_UB 1;
BA_ "U_U611_U625_MY20_Hev_Rx" SG_ 964 TurnLghtSwtch_D_Stat_UB 1;
BA_ "U_U611_U625_MY20_Gas_Rx" SG_ 964 TurnLghtSwtch_D_Stat_UB 1;
BA_ "U_C519_MY18_5_Gas_Rx" SG_ 964 TurnLghtSwtch_D_Stat_UB 1;
BA_ "U_C519_MY18_5_Diesel_Rx" SG_ 964 TurnLghtSwtch_D_Stat_UB 1;
BA_ "U_B515_MCA_MY17_Gas_Rx" SG_ 964 TurnLghtSwtch_D_Stat_UB 1;
BA_ "U_B515_MCA_MY17_Diesel_Rx" SG_ 964 TurnLghtSwtch_D_Stat_UB 1;
BA_ "U_B479_MY17_Diesel_Rx" SG_ 964 TurnLghtSwtch_D_Stat_UB 1;
BA_ "U_B479_MY17_Gas_Rx" SG_ 964 TurnLghtSwtch_D_Stat_UB 1;
BA_ "U_B562LC_MY15_Gas_Rx" SG_ 964 TurnLghtSwtch_D_Stat_UB 1;
BA_ "CrossOver_InfoCAN" SG_ 964 TurnLghtSwtch_D_Stat_UB 1;
BA_ "U_CX727_MY2021_Rx" SG_ 964 TurnLghtSwtch_D_Stat 1;
BA_ "U_CX430_MY2021_Rx" SG_ 964 TurnLghtSwtch_D_Stat 1;
BA_ "U_U611_U625_MY20_Phev_Rx" SG_ 964 TurnLghtSwtch_D_Stat 1;
BA_ "U_CX482_CX483_MY20_Rx" SG_ 964 TurnLghtSwtch_D_Stat 1;
BA_ "U_U611_U625_MY20_Hev_Rx" SG_ 964 TurnLghtSwtch_D_Stat 1;
BA_ "U_U611_U625_MY20_Gas_Rx" SG_ 964 TurnLghtSwtch_D_Stat 1;
BA_ "U_C519_MY18_5_Gas_Rx" SG_ 964 TurnLghtSwtch_D_Stat 1;
BA_ "U_C519_MY18_5_Diesel_Rx" SG_ 964 TurnLghtSwtch_D_Stat 1;
BA_ "U_B515_MCA_MY17_Gas_Rx" SG_ 964 TurnLghtSwtch_D_Stat 1;
BA_ "U_B515_MCA_MY17_Diesel_Rx" SG_ 964 TurnLghtSwtch_D_Stat 1;
BA_ "U_B479_MY17_Diesel_Rx" SG_ 964 TurnLghtSwtch_D_Stat 1;
BA_ "U_B479_MY17_Gas_Rx" SG_ 964 TurnLghtSwtch_D_Stat 1;
BA_ "U_B562LC_MY15_Gas_Rx" SG_ 964 TurnLghtSwtch_D_Stat 1;
BA_ "GenSigSendType" SG_ 964 TurnLghtSwtch_D_Stat 3;
BA_ "CrossOver_InfoCAN" SG_ 964 TurnLghtSwtch_D_Stat 1;
BA_ "WakeupSignal" SG_ 964 TurnLghtSwtch_D_Stat 1;
BA_ "U_CX727_MY2021_Rx" SG_ 964 Power_Liftgate_Mode_Cmd_UB 1;
BA_ "U_U611_U625_MY20_Phev_Rx" SG_ 964 Power_Liftgate_Mode_Cmd_UB 1;
BA_ "U_CX482_CX483_MY20_Rx" SG_ 964 Power_Liftgate_Mode_Cmd_UB 1;
BA_ "U_U611_U625_MY20_Hev_Rx" SG_ 964 Power_Liftgate_Mode_Cmd_UB 1;
BA_ "U_U611_U625_MY20_Gas_Rx" SG_ 964 Power_Liftgate_Mode_Cmd_UB 1;
BA_ "U_C519_MY18_5_Gas_Rx" SG_ 964 Power_Liftgate_Mode_Cmd_UB 1;
BA_ "U_C519_MY18_5_Diesel_Rx" SG_ 964 Power_Liftgate_Mode_Cmd_UB 1;
BA_ "U_CX727_MY2021_Rx" SG_ 964 Power_Liftgate_Mode_Cmd 1;
BA_ "U_U611_U625_MY20_Phev_Rx" SG_ 964 Power_Liftgate_Mode_Cmd 1;
BA_ "U_CX482_CX483_MY20_Rx" SG_ 964 Power_Liftgate_Mode_Cmd 1;
BA_ "U_U611_U625_MY20_Hev_Rx" SG_ 964 Power_Liftgate_Mode_Cmd 1;
BA_ "U_U611_U625_MY20_Gas_Rx" SG_ 964 Power_Liftgate_Mode_Cmd 1;
BA_ "U_C519_MY18_5_Gas_Rx" SG_ 964 Power_Liftgate_Mode_Cmd 1;
BA_ "U_C519_MY18_5_Diesel_Rx" SG_ 964 Power_Liftgate_Mode_Cmd 1;
BA_ "GenSigSendType" SG_ 964 Power_Liftgate_Mode_Cmd 3;
BA_ "CrossOver_InfoCAN" SG_ 964 Power_Liftgate_Mode_Cmd 1;
BA_ "WakeupSignal" SG_ 964 Power_Liftgate_Mode_Cmd 1;
BA_ "GenSigSendType" SG_ 964 EcoMode_B_Stat 3;
BA_ "GenSigSendType" SG_ 964 MetricActvTe_B_Actl_UB 3;
BA_ "U_P702_MY2021_Rx" SG_ 964 MetricActvTe_B_Actl_UB 1;
BA_ "U_CX727_MY2021_Rx" SG_ 964 MetricActvTe_B_Actl_UB 1;
BA_ "U_H567_MY20_Rx" SG_ 964 MetricActvTe_B_Actl_UB 1;
BA_ "U_CX430_MY2021_Rx" SG_ 964 MetricActvTe_B_Actl_UB 1;
BA_ "U_U611_U625_MY20_Phev_Rx" SG_ 964 MetricActvTe_B_Actl_UB 1;
BA_ "U_B562_MY18_Diesel_Rx" SG_ 964 MetricActvTe_B_Actl_UB 1;
BA_ "U_CX482_CX483_MY20_Rx" SG_ 964 MetricActvTe_B_Actl_UB 1;
BA_ "U_U611_U625_MY20_Hev_Rx" SG_ 964 MetricActvTe_B_Actl_UB 1;
BA_ "U_U611_U625_MY20_Gas_Rx" SG_ 964 MetricActvTe_B_Actl_UB 1;
BA_ "U_B500_MY18_Diesel_Rx" SG_ 964 MetricActvTe_B_Actl_UB 1;
BA_ "U_B500_MY18_Gas_Rx" SG_ 964 MetricActvTe_B_Actl_UB 1;
BA_ "U_C490_MY18_Rx" SG_ 964 MetricActvTe_B_Actl_UB 1;
BA_ "U_B562_MY18_Gas_Rx" SG_ 964 MetricActvTe_B_Actl_UB 1;
BA_ "U_C519_MY18_5_Gas_Rx" SG_ 964 MetricActvTe_B_Actl_UB 1;
BA_ "U_C519_MY18_5_Diesel_Rx" SG_ 964 MetricActvTe_B_Actl_UB 1;
BA_ "U_B515_MCA_MY17_Gas_Rx" SG_ 964 MetricActvTe_B_Actl_UB 1;
BA_ "U_B515_MCA_MY17_Diesel_Rx" SG_ 964 MetricActvTe_B_Actl_UB 1;
BA_ "U_B479_MY17_Diesel_Rx" SG_ 964 MetricActvTe_B_Actl_UB 1;
BA_ "U_B479_MY17_Gas_Rx" SG_ 964 MetricActvTe_B_Actl_UB 1;
BA_ "U_P702_MY2021_Rx" SG_ 964 MetricActvTe_B_Actl 1;
BA_ "U_CX727_MY2021_Rx" SG_ 964 MetricActvTe_B_Actl 1;
BA_ "U_H567_MY20_Rx" SG_ 964 MetricActvTe_B_Actl 1;
BA_ "U_CX430_MY2021_Rx" SG_ 964 MetricActvTe_B_Actl 1;
BA_ "U_U611_U625_MY20_Phev_Rx" SG_ 964 MetricActvTe_B_Actl 1;
BA_ "U_B562_MY18_Diesel_Rx" SG_ 964 MetricActvTe_B_Actl 1;
BA_ "U_CX482_CX483_MY20_Rx" SG_ 964 MetricActvTe_B_Actl 1;
BA_ "U_U611_U625_MY20_Hev_Rx" SG_ 964 MetricActvTe_B_Actl 1;
BA_ "U_U611_U625_MY20_Gas_Rx" SG_ 964 MetricActvTe_B_Actl 1;
BA_ "U_B500_MY18_Diesel_Rx" SG_ 964 MetricActvTe_B_Actl 1;
BA_ "U_B500_MY18_Gas_Rx" SG_ 964 MetricActvTe_B_Actl 1;
BA_ "U_C490_MY18_Rx" SG_ 964 MetricActvTe_B_Actl 1;
BA_ "U_B562_MY18_Gas_Rx" SG_ 964 MetricActvTe_B_Actl 1;
BA_ "U_C519_MY18_5_Gas_Rx" SG_ 964 MetricActvTe_B_Actl 1;
BA_ "U_C519_MY18_5_Diesel_Rx" SG_ 964 MetricActvTe_B_Actl 1;
BA_ "U_B515_MCA_MY17_Gas_Rx" SG_ 964 MetricActvTe_B_Actl 1;
BA_ "U_B515_MCA_MY17_Diesel_Rx" SG_ 964 MetricActvTe_B_Actl 1;
BA_ "U_B479_MY17_Diesel_Rx" SG_ 964 MetricActvTe_B_Actl 1;
BA_ "U_B479_MY17_Gas_Rx" SG_ 964 MetricActvTe_B_Actl 1;
BA_ "GenSigSendType" SG_ 964 MetricActvTe_B_Actl 3;
BA_ "CrossOver_InfoCAN" SG_ 964 MetricActvTe_B_Actl 1;
BA_ "U_P702_MY2021_Rx" SG_ 964 EngClntTe_D_Qf 1;
BA_ "U_CX727_MY2021_Rx" SG_ 964 EngClntTe_D_Qf 1;
BA_ "U_H567_MY20_Rx" SG_ 964 EngClntTe_D_Qf 1;
BA_ "U_CX430_MY2021_Rx" SG_ 964 EngClntTe_D_Qf 1;
BA_ "U_U611_U625_MY20_Phev_Rx" SG_ 964 EngClntTe_D_Qf 1;
BA_ "U_B562_MY18_Diesel_Rx" SG_ 964 EngClntTe_D_Qf 1;
BA_ "U_CX482_CX483_MY20_Rx" SG_ 964 EngClntTe_D_Qf 1;
BA_ "U_U611_U625_MY20_Hev_Rx" SG_ 964 EngClntTe_D_Qf 1;
BA_ "U_U611_U625_MY20_Gas_Rx" SG_ 964 EngClntTe_D_Qf 1;
BA_ "U_B500_MY18_Diesel_Rx" SG_ 964 EngClntTe_D_Qf 1;
BA_ "U_B500_MY18_Gas_Rx" SG_ 964 EngClntTe_D_Qf 1;
BA_ "U_C490_MY18_Rx" SG_ 964 EngClntTe_D_Qf 1;
BA_ "U_B562_MY18_Gas_Rx" SG_ 964 EngClntTe_D_Qf 1;
BA_ "U_C519_MY18_5_Gas_Rx" SG_ 964 EngClntTe_D_Qf 1;
BA_ "U_C519_MY18_5_Diesel_Rx" SG_ 964 EngClntTe_D_Qf 1;
BA_ "U_B515_MCA_MY17_Gas_Rx" SG_ 964 EngClntTe_D_Qf 1;
BA_ "U_B515_MCA_MY17_Diesel_Rx" SG_ 964 EngClntTe_D_Qf 1;
BA_ "U_B479_MY17_Diesel_Rx" SG_ 964 EngClntTe_D_Qf 1;
BA_ "U_B479_MY17_Gas_Rx" SG_ 964 EngClntTe_D_Qf 1;
BA_ "GenSigSendType" SG_ 964 EngClntTe_D_Qf 3;
BA_ "MetaData" SG_ 964 EngClntTe_D_Qf 1;
BA_ "CrossOver_InfoCAN" SG_ 964 EngClntTe_D_Qf 1;
BA_ "U_CX727_MY2021_Rx" SG_ 964 Sod_D_Rq 1;
BA_ "U_CX430_MY2021_Rx" SG_ 964 Sod_D_Rq 1;
BA_ "U_U611_U625_MY20_Phev_Rx" SG_ 964 Sod_D_Rq 1;
BA_ "U_CX482_CX483_MY20_Rx" SG_ 964 Sod_D_Rq 1;
BA_ "U_U611_U625_MY20_Hev_Rx" SG_ 964 Sod_D_Rq 1;
BA_ "U_U611_U625_MY20_Gas_Rx" SG_ 964 Sod_D_Rq 1;
BA_ "U_C519_MY18_5_Gas_Rx" SG_ 964 Sod_D_Rq 1;
BA_ "U_C519_MY18_5_Diesel_Rx" SG_ 964 Sod_D_Rq 1;
BA_ "U_B515_MCA_MY17_Gas_Rx" SG_ 964 Sod_D_Rq 1;
BA_ "U_B515_MCA_MY17_Diesel_Rx" SG_ 964 Sod_D_Rq 1;
BA_ "U_B479_MY17_Diesel_Rx" SG_ 964 Sod_D_Rq 1;
BA_ "U_B479_MY17_Gas_Rx" SG_ 964 Sod_D_Rq 1;
BA_ "U_B562LC_MY15_Gas_Rx" SG_ 964 Sod_D_Rq 1;
BA_ "GenSigSendType" SG_ 964 Sod_D_Rq 3;
BA_ "GenSigStartValue" SG_ 964 Sod_D_Rq 2;
BA_ "GenSigStartValueInteger" SG_ 964 Sod_D_Rq 2;
BA_ "CrossOver_InfoCAN" SG_ 964 Sod_D_Rq 1;
BA_ "U_P702_MY2021_Rx" SG_ 964 MetricActv_B_Actl 1;
BA_ "U_CX727_MY2021_Rx" SG_ 964 MetricActv_B_Actl 1;
BA_ "U_CX430_MY2021_Rx" SG_ 964 MetricActv_B_Actl 1;
BA_ "U_U611_U625_MY20_Phev_Rx" SG_ 964 MetricActv_B_Actl 1;
BA_ "U_B562_MY18_Diesel_Rx" SG_ 964 MetricActv_B_Actl 1;
BA_ "U_CX482_CX483_MY20_Rx" SG_ 964 MetricActv_B_Actl 1;
BA_ "U_U611_U625_MY20_Hev_Rx" SG_ 964 MetricActv_B_Actl 1;
BA_ "U_U611_U625_MY20_Gas_Rx" SG_ 964 MetricActv_B_Actl 1;
BA_ "U_B500_MY18_Diesel_Rx" SG_ 964 MetricActv_B_Actl 1;
BA_ "U_B500_MY18_Gas_Rx" SG_ 964 MetricActv_B_Actl 1;
BA_ "U_C490_MY18_Rx" SG_ 964 MetricActv_B_Actl 1;
BA_ "U_B562_MY18_Gas_Rx" SG_ 964 MetricActv_B_Actl 1;
BA_ "U_C519_MY18_5_Gas_Rx" SG_ 964 MetricActv_B_Actl 1;
BA_ "U_C519_MY18_5_Diesel_Rx" SG_ 964 MetricActv_B_Actl 1;
BA_ "U_B515_MCA_MY17_Gas_Rx" SG_ 964 MetricActv_B_Actl 1;
BA_ "U_B515_MCA_MY17_Diesel_Rx" SG_ 964 MetricActv_B_Actl 1;
BA_ "U_B479_MY17_Diesel_Rx" SG_ 964 MetricActv_B_Actl 1;
BA_ "U_B479_MY17_Gas_Rx" SG_ 964 MetricActv_B_Actl 1;
BA_ "GenSigSendType" SG_ 964 MetricActv_B_Actl 3;
BA_ "CrossOver_InfoCAN" SG_ 964 MetricActv_B_Actl 1;
BA_ "U_P702_MY2021_Rx" SG_ 964 EngClnt_Te_Actl 1;
BA_ "U_CX727_MY2021_Rx" SG_ 964 EngClnt_Te_Actl 1;
BA_ "U_H567_MY20_Rx" SG_ 964 EngClnt_Te_Actl 1;
BA_ "U_CX430_MY2021_Rx" SG_ 964 EngClnt_Te_Actl 1;
BA_ "U_U611_U625_MY20_Phev_Rx" SG_ 964 EngClnt_Te_Actl 1;
BA_ "U_B562_MY18_Diesel_Rx" SG_ 964 EngClnt_Te_Actl 1;
BA_ "U_U611_U625_MY20_Hev_Rx" SG_ 964 EngClnt_Te_Actl 1;
BA_ "U_U611_U625_MY20_Gas_Rx" SG_ 964 EngClnt_Te_Actl 1;
BA_ "U_B500_MY18_Diesel_Rx" SG_ 964 EngClnt_Te_Actl 1;
BA_ "U_B500_MY18_Gas_Rx" SG_ 964 EngClnt_Te_Actl 1;
BA_ "U_C490_MY18_Rx" SG_ 964 EngClnt_Te_Actl 1;
BA_ "U_B562_MY18_Gas_Rx" SG_ 964 EngClnt_Te_Actl 1;
BA_ "U_B515_MCA_MY17_Gas_Rx" SG_ 964 EngClnt_Te_Actl 1;
BA_ "U_B515_MCA_MY17_Diesel_Rx" SG_ 964 EngClnt_Te_Actl 1;
BA_ "U_B479_MY17_Diesel_Rx" SG_ 964 EngClnt_Te_Actl 1;
BA_ "U_B479_MY17_Gas_Rx" SG_ 964 EngClnt_Te_Actl 1;
BA_ "U_CX482_CX483_MY20_Rx" SG_ 964 EngClnt_Te_Actl 1;
BA_ "U_C519_MY18_5_Gas_Rx" SG_ 964 EngClnt_Te_Actl 1;
BA_ "U_C519_MY18_5_Diesel_Rx" SG_ 964 EngClnt_Te_Actl 1;
BA_ "GenSigSendType" SG_ 964 EngClnt_Te_Actl 3;
BA_ "CrossOver_InfoCAN" SG_ 964 EngClnt_Te_Actl 1;
BA_ "GenSigSendType" SG_ 964 MetricActv_B_Actl_UB 3;
BA_ "U_P702_MY2021_Rx" SG_ 964 MetricActv_B_Actl_UB 1;
BA_ "U_CX727_MY2021_Rx" SG_ 964 MetricActv_B_Actl_UB 1;
BA_ "U_CX430_MY2021_Rx" SG_ 964 MetricActv_B_Actl_UB 1;
BA_ "U_U611_U625_MY20_Phev_Rx" SG_ 964 MetricActv_B_Actl_UB 1;
BA_ "U_B562_MY18_Diesel_Rx" SG_ 964 MetricActv_B_Actl_UB 1;
BA_ "U_CX482_CX483_MY20_Rx" SG_ 964 MetricActv_B_Actl_UB 1;
BA_ "U_U611_U625_MY20_Hev_Rx" SG_ 964 MetricActv_B_Actl_UB 1;
BA_ "U_U611_U625_MY20_Gas_Rx" SG_ 964 MetricActv_B_Actl_UB 1;
BA_ "U_B500_MY18_Diesel_Rx" SG_ 964 MetricActv_B_Actl_UB 1;
BA_ "U_B500_MY18_Gas_Rx" SG_ 964 MetricActv_B_Actl_UB 1;
BA_ "U_C490_MY18_Rx" SG_ 964 MetricActv_B_Actl_UB 1;
BA_ "U_B562_MY18_Gas_Rx" SG_ 964 MetricActv_B_Actl_UB 1;
BA_ "U_C519_MY18_5_Gas_Rx" SG_ 964 MetricActv_B_Actl_UB 1;
BA_ "U_C519_MY18_5_Diesel_Rx" SG_ 964 MetricActv_B_Actl_UB 1;
BA_ "U_B515_MCA_MY17_Gas_Rx" SG_ 964 MetricActv_B_Actl_UB 1;
BA_ "U_B515_MCA_MY17_Diesel_Rx" SG_ 964 MetricActv_B_Actl_UB 1;
BA_ "U_B479_MY17_Diesel_Rx" SG_ 964 MetricActv_B_Actl_UB 1;
BA_ "U_B479_MY17_Gas_Rx" SG_ 964 MetricActv_B_Actl_UB 1;
BA_ "GenSigSendType" SG_ 964 EngClnt_Te_Actl_UB 3;
BA_ "U_P702_MY2021_Rx" SG_ 964 EngClnt_Te_Actl_UB 1;
BA_ "U_CX727_MY2021_Rx" SG_ 964 EngClnt_Te_Actl_UB 1;
BA_ "U_H567_MY20_Rx" SG_ 964 EngClnt_Te_Actl_UB 1;
BA_ "U_CX430_MY2021_Rx" SG_ 964 EngClnt_Te_Actl_UB 1;
BA_ "U_U611_U625_MY20_Phev_Rx" SG_ 964 EngClnt_Te_Actl_UB 1;
BA_ "U_B562_MY18_Diesel_Rx" SG_ 964 EngClnt_Te_Actl_UB 1;
BA_ "U_U611_U625_MY20_Hev_Rx" SG_ 964 EngClnt_Te_Actl_UB 1;
BA_ "U_U611_U625_MY20_Gas_Rx" SG_ 964 EngClnt_Te_Actl_UB 1;
BA_ "U_B500_MY18_Diesel_Rx" SG_ 964 EngClnt_Te_Actl_UB 1;
BA_ "U_B500_MY18_Gas_Rx" SG_ 964 EngClnt_Te_Actl_UB 1;
BA_ "U_C490_MY18_Rx" SG_ 964 EngClnt_Te_Actl_UB 1;
BA_ "U_B562_MY18_Gas_Rx" SG_ 964 EngClnt_Te_Actl_UB 1;
BA_ "U_B515_MCA_MY17_Gas_Rx" SG_ 964 EngClnt_Te_Actl_UB 1;
BA_ "U_B515_MCA_MY17_Diesel_Rx" SG_ 964 EngClnt_Te_Actl_UB 1;
BA_ "U_B479_MY17_Diesel_Rx" SG_ 964 EngClnt_Te_Actl_UB 1;
BA_ "U_B479_MY17_Gas_Rx" SG_ 964 EngClnt_Te_Actl_UB 1;
BA_ "U_CX482_CX483_MY20_Rx" SG_ 964 EngClnt_Te_Actl_UB 1;
BA_ "U_C519_MY18_5_Gas_Rx" SG_ 964 EngClnt_Te_Actl_UB 1;
BA_ "U_C519_MY18_5_Diesel_Rx" SG_ 964 EngClnt_Te_Actl_UB 1;
BA_ "GenSigSendType" SG_ 964 OCSSensrDataUpperLim_UB 3;
BA_ "U_CX727_MY2021_Rx" SG_ 964 OCSSensrDataUpperLim_UB 1;
BA_ "U_CX430_MY2021_Rx" SG_ 964 OCSSensrDataUpperLim_UB 1;
BA_ "U_B500_MY18_Diesel_Rx" SG_ 964 OCSSensrDataUpperLim_UB 1;
BA_ "U_B500_MY18_Gas_Rx" SG_ 964 OCSSensrDataUpperLim_UB 1;
BA_ "U_C519_MY18_5_Diesel_Rx" SG_ 964 OCSSensrDataUpperLim_UB 1;
BA_ "U_B515_MCA_MY17_Gas_Rx" SG_ 964 OCSSensrDataUpperLim_UB 1;
BA_ "U_B515_MCA_MY17_Diesel_Rx" SG_ 964 OCSSensrDataUpperLim_UB 1;
BA_ "U_B479_MY17_Diesel_Rx" SG_ 964 OCSSensrDataUpperLim_UB 1;
BA_ "U_B479_MY17_Gas_Rx" SG_ 964 OCSSensrDataUpperLim_UB 1;
BA_ "U_C519_MY18_5_Gas_Rx" SG_ 964 OCSSensrDataUpperLim_UB 1;
BA_ "U_P702_MY2021_Rx" SG_ 964 OCSSensrDataUpperLim_UB 1;
BA_ "U_U611_U625_MY20_Phev_Rx" SG_ 964 OCSSensrDataUpperLim_UB 1;
BA_ "U_CX482_CX483_MY20_Rx" SG_ 964 OCSSensrDataUpperLim_UB 1;
BA_ "U_U611_U625_MY20_Hev_Rx" SG_ 964 OCSSensrDataUpperLim_UB 1;
BA_ "U_U611_U625_MY20_Gas_Rx" SG_ 964 OCSSensrDataUpperLim_UB 1;
BA_ "U_CX727_MY2021_Rx" SG_ 964 OCSSensrDataUpperLim 1;
BA_ "U_CX430_MY2021_Rx" SG_ 964 OCSSensrDataUpperLim 1;
BA_ "U_B500_MY18_Diesel_Rx" SG_ 964 OCSSensrDataUpperLim 1;
BA_ "U_B500_MY18_Gas_Rx" SG_ 964 OCSSensrDataUpperLim 1;
BA_ "U_B515_MCA_MY17_Gas_Rx" SG_ 964 OCSSensrDataUpperLim 1;
BA_ "U_B515_MCA_MY17_Diesel_Rx" SG_ 964 OCSSensrDataUpperLim 1;
BA_ "U_B479_MY17_Diesel_Rx" SG_ 964 OCSSensrDataUpperLim 1;
BA_ "U_B479_MY17_Gas_Rx" SG_ 964 OCSSensrDataUpperLim 1;
BA_ "U_C519_MY18_5_Gas_Rx" SG_ 964 OCSSensrDataUpperLim 1;
BA_ "U_C519_MY18_5_Diesel_Rx" SG_ 964 OCSSensrDataUpperLim 1;
BA_ "U_P702_MY2021_Rx" SG_ 964 OCSSensrDataUpperLim 1;
BA_ "U_U611_U625_MY20_Phev_Rx" SG_ 964 OCSSensrDataUpperLim 1;
BA_ "U_CX482_CX483_MY20_Rx" SG_ 964 OCSSensrDataUpperLim 1;
BA_ "U_U611_U625_MY20_Hev_Rx" SG_ 964 OCSSensrDataUpperLim 1;
BA_ "U_U611_U625_MY20_Gas_Rx" SG_ 964 OCSSensrDataUpperLim 1;
BA_ "GenSigSendType" SG_ 964 OCSSensrDataUpperLim 3;
BA_ "GenSigSendType" SG_ 964 OCSSensrDataLowerLim_UB 3;
BA_ "U_CX727_MY2021_Rx" SG_ 964 OCSSensrDataLowerLim_UB 1;
BA_ "U_CX430_MY2021_Rx" SG_ 964 OCSSensrDataLowerLim_UB 1;
BA_ "U_B500_MY18_Diesel_Rx" SG_ 964 OCSSensrDataLowerLim_UB 1;
BA_ "U_B500_MY18_Gas_Rx" SG_ 964 OCSSensrDataLowerLim_UB 1;
BA_ "U_B515_MCA_MY17_Gas_Rx" SG_ 964 OCSSensrDataLowerLim_UB 1;
BA_ "U_B515_MCA_MY17_Diesel_Rx" SG_ 964 OCSSensrDataLowerLim_UB 1;
BA_ "U_B479_MY17_Diesel_Rx" SG_ 964 OCSSensrDataLowerLim_UB 1;
BA_ "U_B479_MY17_Gas_Rx" SG_ 964 OCSSensrDataLowerLim_UB 1;
BA_ "U_C519_MY18_5_Gas_Rx" SG_ 964 OCSSensrDataLowerLim_UB 1;
BA_ "U_C519_MY18_5_Diesel_Rx" SG_ 964 OCSSensrDataLowerLim_UB 1;
BA_ "U_P702_MY2021_Rx" SG_ 964 OCSSensrDataLowerLim_UB 1;
BA_ "U_U611_U625_MY20_Phev_Rx" SG_ 964 OCSSensrDataLowerLim_UB 1;
BA_ "U_CX482_CX483_MY20_Rx" SG_ 964 OCSSensrDataLowerLim_UB 1;
BA_ "U_U611_U625_MY20_Hev_Rx" SG_ 964 OCSSensrDataLowerLim_UB 1;
BA_ "U_U611_U625_MY20_Gas_Rx" SG_ 964 OCSSensrDataLowerLim_UB 1;
BA_ "GenSigSendType" SG_ 964 PrkAid_D_Falt 3;
BA_ "CrossOver_InfoCAN" SG_ 964 PrkAid_D_Falt 1;
BA_ "U_CX727_MY2021_Rx" SG_ 964 OCSSensrDataLowerLim 1;
BA_ "U_CX430_MY2021_Rx" SG_ 964 OCSSensrDataLowerLim 1;
BA_ "U_B500_MY18_Diesel_Rx" SG_ 964 OCSSensrDataLowerLim 1;
BA_ "U_B500_MY18_Gas_Rx" SG_ 964 OCSSensrDataLowerLim 1;
BA_ "U_B515_MCA_MY17_Gas_Rx" SG_ 964 OCSSensrDataLowerLim 1;
BA_ "U_B515_MCA_MY17_Diesel_Rx" SG_ 964 OCSSensrDataLowerLim 1;
BA_ "U_B479_MY17_Diesel_Rx" SG_ 964 OCSSensrDataLowerLim 1;
BA_ "U_B479_MY17_Gas_Rx" SG_ 964 OCSSensrDataLowerLim 1;
BA_ "U_C519_MY18_5_Gas_Rx" SG_ 964 OCSSensrDataLowerLim 1;
BA_ "U_C519_MY18_5_Diesel_Rx" SG_ 964 OCSSensrDataLowerLim 1;
BA_ "U_P702_MY2021_Rx" SG_ 964 OCSSensrDataLowerLim 1;
BA_ "U_U611_U625_MY20_Phev_Rx" SG_ 964 OCSSensrDataLowerLim 1;
BA_ "U_CX482_CX483_MY20_Rx" SG_ 964 OCSSensrDataLowerLim 1;
BA_ "U_U611_U625_MY20_Hev_Rx" SG_ 964 OCSSensrDataLowerLim 1;
BA_ "U_U611_U625_MY20_Gas_Rx" SG_ 964 OCSSensrDataLowerLim 1;
BA_ "GenSigSendType" SG_ 964 OCSSensrDataLowerLim 3;
BA_ "GenSigSendType" SG_ 964 WiprFront_D_Stat_UB 3;
BA_ "U_P702_MY2021_Rx" SG_ 964 WiprFront_D_Stat_UB 1;
BA_ "U_B500_MY18_Diesel_Rx" SG_ 964 WiprFront_D_Stat_UB 1;
BA_ "U_B500_MY18_Gas_Rx" SG_ 964 WiprFront_D_Stat_UB 1;
BA_ "U_CX727_MY2021_Rx" SG_ 964 WiprFront_D_Stat_UB 1;
BA_ "U_CX430_MY2021_Rx" SG_ 964 WiprFront_D_Stat_UB 1;
BA_ "U_U611_U625_MY20_Phev_Rx" SG_ 964 WiprFront_D_Stat_UB 1;
BA_ "U_CX482_CX483_MY20_Rx" SG_ 964 WiprFront_D_Stat_UB 1;
BA_ "U_U611_U625_MY20_Hev_Rx" SG_ 964 WiprFront_D_Stat_UB 1;
BA_ "U_U611_U625_MY20_Gas_Rx" SG_ 964 WiprFront_D_Stat_UB 1;
BA_ "U_C519_MY18_5_Gas_Rx" SG_ 964 WiprFront_D_Stat_UB 1;
BA_ "U_C519_MY18_5_Diesel_Rx" SG_ 964 WiprFront_D_Stat_UB 1;
BA_ "U_B515_MCA_MY17_Gas_Rx" SG_ 964 WiprFront_D_Stat_UB 1;
BA_ "U_B515_MCA_MY17_Diesel_Rx" SG_ 964 WiprFront_D_Stat_UB 1;
BA_ "U_B479_MY17_Diesel_Rx" SG_ 964 WiprFront_D_Stat_UB 1;
BA_ "U_B479_MY17_Gas_Rx" SG_ 964 WiprFront_D_Stat_UB 1;
BA_ "U_B562LC_MY15_Gas_Rx" SG_ 964 WiprFront_D_Stat_UB 1;
BA_ "U_P702_MY2021_Rx" SG_ 964 WiprFront_D_Stat 1;
BA_ "U_B500_MY18_Diesel_Rx" SG_ 964 WiprFront_D_Stat 1;
BA_ "U_B500_MY18_Gas_Rx" SG_ 964 WiprFront_D_Stat 1;
BA_ "U_CX727_MY2021_Rx" SG_ 964 WiprFront_D_Stat 1;
BA_ "U_CX430_MY2021_Rx" SG_ 964 WiprFront_D_Stat 1;
BA_ "U_U611_U625_MY20_Phev_Rx" SG_ 964 WiprFront_D_Stat 1;
BA_ "U_CX482_CX483_MY20_Rx" SG_ 964 WiprFront_D_Stat 1;
BA_ "U_U611_U625_MY20_Hev_Rx" SG_ 964 WiprFront_D_Stat 1;
BA_ "U_U611_U625_MY20_Gas_Rx" SG_ 964 WiprFront_D_Stat 1;
BA_ "U_C519_MY18_5_Gas_Rx" SG_ 964 WiprFront_D_Stat 1;
BA_ "U_C519_MY18_5_Diesel_Rx" SG_ 964 WiprFront_D_Stat 1;
BA_ "U_B515_MCA_MY17_Gas_Rx" SG_ 964 WiprFront_D_Stat 1;
BA_ "U_B515_MCA_MY17_Diesel_Rx" SG_ 964 WiprFront_D_Stat 1;
BA_ "U_B479_MY17_Diesel_Rx" SG_ 964 WiprFront_D_Stat 1;
BA_ "U_B479_MY17_Gas_Rx" SG_ 964 WiprFront_D_Stat 1;
BA_ "U_B562LC_MY15_Gas_Rx" SG_ 964 WiprFront_D_Stat 1;
BA_ "GenSigSendType" SG_ 964 WiprFront_D_Stat 3;
BA_ "GenSigStartValue" SG_ 964 WiprFront_D_Stat 15;
BA_ "GenSigStartValueInteger" SG_ 964 WiprFront_D_Stat 15;
BA_ "GenSigSendType" SG_ 964 CamraDefog_B_Req_UB 3;
BA_ "U_CX727_MY2021_Rx" SG_ 964 CamraDefog_B_Req_UB 1;
BA_ "U_CX430_MY2021_Rx" SG_ 964 CamraDefog_B_Req_UB 1;
BA_ "U_U611_U625_MY20_Phev_Rx" SG_ 964 CamraDefog_B_Req_UB 1;
BA_ "U_CX482_CX483_MY20_Rx" SG_ 964 CamraDefog_B_Req_UB 1;
BA_ "U_U611_U625_MY20_Hev_Rx" SG_ 964 CamraDefog_B_Req_UB 1;
BA_ "U_U611_U625_MY20_Gas_Rx" SG_ 964 CamraDefog_B_Req_UB 1;
BA_ "U_C519_MY18_5_Gas_Rx" SG_ 964 CamraDefog_B_Req_UB 1;
BA_ "U_C519_MY18_5_Diesel_Rx" SG_ 964 CamraDefog_B_Req_UB 1;
BA_ "U_CX727_MY2021_Rx" SG_ 964 Sod_D_Rq_UB 1;
BA_ "U_CX430_MY2021_Rx" SG_ 964 Sod_D_Rq_UB 1;
BA_ "U_U611_U625_MY20_Phev_Rx" SG_ 964 Sod_D_Rq_UB 1;
BA_ "U_CX482_CX483_MY20_Rx" SG_ 964 Sod_D_Rq_UB 1;
BA_ "U_U611_U625_MY20_Hev_Rx" SG_ 964 Sod_D_Rq_UB 1;
BA_ "U_U611_U625_MY20_Gas_Rx" SG_ 964 Sod_D_Rq_UB 1;
BA_ "U_C519_MY18_5_Gas_Rx" SG_ 964 Sod_D_Rq_UB 1;
BA_ "U_C519_MY18_5_Diesel_Rx" SG_ 964 Sod_D_Rq_UB 1;
BA_ "U_B515_MCA_MY17_Gas_Rx" SG_ 964 Sod_D_Rq_UB 1;
BA_ "U_B515_MCA_MY17_Diesel_Rx" SG_ 964 Sod_D_Rq_UB 1;
BA_ "U_B479_MY17_Diesel_Rx" SG_ 964 Sod_D_Rq_UB 1;
BA_ "U_B479_MY17_Gas_Rx" SG_ 964 Sod_D_Rq_UB 1;
BA_ "U_B562LC_MY15_Gas_Rx" SG_ 964 Sod_D_Rq_UB 1;
BA_ "U_CX727_MY2021_Rx" SG_ 964 CamraDefog_B_Req 1;
BA_ "U_CX430_MY2021_Rx" SG_ 964 CamraDefog_B_Req 1;
BA_ "U_U611_U625_MY20_Phev_Rx" SG_ 964 CamraDefog_B_Req 1;
BA_ "U_CX482_CX483_MY20_Rx" SG_ 964 CamraDefog_B_Req 1;
BA_ "U_U611_U625_MY20_Hev_Rx" SG_ 964 CamraDefog_B_Req 1;
BA_ "U_U611_U625_MY20_Gas_Rx" SG_ 964 CamraDefog_B_Req 1;
BA_ "U_C519_MY18_5_Gas_Rx" SG_ 964 CamraDefog_B_Req 1;
BA_ "U_C519_MY18_5_Diesel_Rx" SG_ 964 CamraDefog_B_Req 1;
BA_ "GenSigSendType" SG_ 964 CamraDefog_B_Req 3;
BA_ "CrossOver_InfoCAN" SG_ 964 CamraDefog_B_Req 1;
BA_ "U_P702_MY2021_Rx" SG_ 1843 TesterPhysicalReqHVAC_RCCM 1;
BA_ "U_CX727_MY2021_Rx" SG_ 1843 TesterPhysicalReqHVAC_RCCM 1;
BA_ "U_H567_MY20_Rx" SG_ 1843 TesterPhysicalReqHVAC_RCCM 1;
BA_ "U_CX430_MY2021_Rx" SG_ 1843 TesterPhysicalReqHVAC_RCCM 1;
BA_ "U_U611_U625_MY20_Phev_Rx" SG_ 1843 TesterPhysicalReqHVAC_RCCM 1;
BA_ "U_B562_MY18_Diesel_Rx" SG_ 1843 TesterPhysicalReqHVAC_RCCM 1;
BA_ "U_CX482_CX483_MY20_Rx" SG_ 1843 TesterPhysicalReqHVAC_RCCM 1;
BA_ "U_U611_U625_MY20_Hev_Rx" SG_ 1843 TesterPhysicalReqHVAC_RCCM 1;
BA_ "U_U611_U625_MY20_Gas_Rx" SG_ 1843 TesterPhysicalReqHVAC_RCCM 1;
BA_ "U_B500_MY18_Diesel_Rx" SG_ 1843 TesterPhysicalReqHVAC_RCCM 1;
BA_ "U_B500_MY18_Gas_Rx" SG_ 1843 TesterPhysicalReqHVAC_RCCM 1;
BA_ "U_C490_MY18_Rx" SG_ 1843 TesterPhysicalReqHVAC_RCCM 1;
BA_ "U_B562_MY18_Gas_Rx" SG_ 1843 TesterPhysicalReqHVAC_RCCM 1;
BA_ "U_C519_MY18_5_Gas_Rx" SG_ 1843 TesterPhysicalReqHVAC_RCCM 1;
BA_ "U_C519_MY18_5_Diesel_Rx" SG_ 1843 TesterPhysicalReqHVAC_RCCM 1;
BA_ "U_B515_MCA_MY17_Gas_Rx" SG_ 1843 TesterPhysicalReqHVAC_RCCM 1;
BA_ "U_B515_MCA_MY17_Diesel_Rx" SG_ 1843 TesterPhysicalReqHVAC_RCCM 1;
BA_ "U_B479_MY17_Diesel_Rx" SG_ 1843 TesterPhysicalReqHVAC_RCCM 1;
BA_ "U_B479_MY17_Gas_Rx" SG_ 1843 TesterPhysicalReqHVAC_RCCM 1;
BA_ "GenSigSendType" SG_ 1843 TesterPhysicalReqHVAC_RCCM 3;
BA_ "U_P702_MY2021_Tx" SG_ 1851 TesterPhysicalResHVAC_RCCM 1;
BA_ "U_CX727_MY2021_Tx" SG_ 1851 TesterPhysicalResHVAC_RCCM 1;
BA_ "U_H567_MY20_Tx" SG_ 1851 TesterPhysicalResHVAC_RCCM 1;
BA_ "U_CX430_MY2021_Tx" SG_ 1851 TesterPhysicalResHVAC_RCCM 1;
BA_ "U_U611_U625_MY20_Phev_Tx" SG_ 1851 TesterPhysicalResHVAC_RCCM 1;
BA_ "U_B562_MY18_Diesel_Tx" SG_ 1851 TesterPhysicalResHVAC_RCCM 1;
BA_ "U_CX482_CX483_MY20_Tx" SG_ 1851 TesterPhysicalResHVAC_RCCM 1;
BA_ "U_U611_U625_MY20_Hev_Tx" SG_ 1851 TesterPhysicalResHVAC_RCCM 1;
BA_ "U_U611_U625_MY20_Gas_Tx" SG_ 1851 TesterPhysicalResHVAC_RCCM 1;
BA_ "U_B500_MY18_Diesel_Tx" SG_ 1851 TesterPhysicalResHVAC_RCCM 1;
BA_ "U_B500_MY18_Gas_Tx" SG_ 1851 TesterPhysicalResHVAC_RCCM 1;
BA_ "U_C490_MY18_Tx" SG_ 1851 TesterPhysicalResHVAC_RCCM 1;
BA_ "U_B562_MY18_Gas_Tx" SG_ 1851 TesterPhysicalResHVAC_RCCM 1;
BA_ "U_C519_MY18_5_Gas_Tx" SG_ 1851 TesterPhysicalResHVAC_RCCM 1;
BA_ "U_C519_MY18_5_Diesel_Tx" SG_ 1851 TesterPhysicalResHVAC_RCCM 1;
BA_ "U_B515_MCA_MY17_Gas_Tx" SG_ 1851 TesterPhysicalResHVAC_RCCM 1;
BA_ "U_B515_MCA_MY17_Diesel_Tx" SG_ 1851 TesterPhysicalResHVAC_RCCM 1;
BA_ "U_B479_MY17_Diesel_Tx" SG_ 1851 TesterPhysicalResHVAC_RCCM 1;
BA_ "U_B479_MY17_Gas_Tx" SG_ 1851 TesterPhysicalResHVAC_RCCM 1;
BA_ "GenSigSendType" SG_ 1851 TesterPhysicalResHVAC_RCCM 3;
BA_ "GenSigSendType" SG_ 1411 HVAC_GWOnBoardTester 3;
BA_ "U_P702_MY2021_Tx" SG_ 1411 HVAC_GWOnBoardTester 1;
BA_ "U_CX727_MY2021_Tx" SG_ 1411 HVAC_GWOnBoardTester 1;
BA_ "U_H567_MY20_Tx" SG_ 1411 HVAC_GWOnBoardTester 1;
BA_ "U_CX430_MY2021_Tx" SG_ 1411 HVAC_GWOnBoardTester 1;
BA_ "U_U611_U625_MY20_Phev_Tx" SG_ 1411 HVAC_GWOnBoardTester 1;
BA_ "U_B562_MY18_Diesel_Tx" SG_ 1411 HVAC_GWOnBoardTester 1;
BA_ "U_CX482_CX483_MY20_Tx" SG_ 1411 HVAC_GWOnBoardTester 1;
BA_ "U_U611_U625_MY20_Hev_Tx" SG_ 1411 HVAC_GWOnBoardTester 1;
BA_ "U_U611_U625_MY20_Gas_Tx" SG_ 1411 HVAC_GWOnBoardTester 1;
BA_ "U_B500_MY18_Diesel_Tx" SG_ 1411 HVAC_GWOnBoardTester 1;
BA_ "U_B500_MY18_Gas_Tx" SG_ 1411 HVAC_GWOnBoardTester 1;
BA_ "U_C490_MY18_Tx" SG_ 1411 HVAC_GWOnBoardTester 1;
BA_ "U_B562_MY18_Gas_Tx" SG_ 1411 HVAC_GWOnBoardTester 1;
BA_ "U_C519_MY18_5_Gas_Tx" SG_ 1411 HVAC_GWOnBoardTester 1;
BA_ "U_C519_MY18_5_Diesel_Tx" SG_ 1411 HVAC_GWOnBoardTester 1;
BA_ "GenSigStartValue" SG_ 1411 HVAC_GWOnBoardTester 255;
BA_ "ContentDependant" SG_ 1411 HVAC_GWOnBoardTester 1;
BA_ "GenSigStartValueInteger" SG_ 1411 HVAC_GWOnBoardTester 255;
BA_ "GenSigSendType" SG_ 1411 HVAC_GWNMProxy 3;
BA_ "U_P702_MY2021_Tx" SG_ 1411 HVAC_GWNMProxy 1;
BA_ "U_CX727_MY2021_Tx" SG_ 1411 HVAC_GWNMProxy 1;
BA_ "U_H567_MY20_Tx" SG_ 1411 HVAC_GWNMProxy 1;
BA_ "U_CX430_MY2021_Tx" SG_ 1411 HVAC_GWNMProxy 1;
BA_ "U_U611_U625_MY20_Phev_Tx" SG_ 1411 HVAC_GWNMProxy 1;
BA_ "U_B562_MY18_Diesel_Tx" SG_ 1411 HVAC_GWNMProxy 1;
BA_ "U_CX482_CX483_MY20_Tx" SG_ 1411 HVAC_GWNMProxy 1;
BA_ "U_U611_U625_MY20_Hev_Tx" SG_ 1411 HVAC_GWNMProxy 1;
BA_ "U_U611_U625_MY20_Gas_Tx" SG_ 1411 HVAC_GWNMProxy 1;
BA_ "U_B500_MY18_Diesel_Tx" SG_ 1411 HVAC_GWNMProxy 1;
BA_ "U_B500_MY18_Gas_Tx" SG_ 1411 HVAC_GWNMProxy 1;
BA_ "U_C490_MY18_Tx" SG_ 1411 HVAC_GWNMProxy 1;
BA_ "U_B562_MY18_Gas_Tx" SG_ 1411 HVAC_GWNMProxy 1;
BA_ "U_C519_MY18_5_Gas_Tx" SG_ 1411 HVAC_GWNMProxy 1;
BA_ "U_C519_MY18_5_Diesel_Tx" SG_ 1411 HVAC_GWNMProxy 1;
BA_ "GenSigStartValue" SG_ 1411 HVAC_GWNMProxy 255;
BA_ "ContentDependant" SG_ 1411 HVAC_GWNMProxy 1;
BA_ "GenSigStartValueInteger" SG_ 1411 HVAC_GWNMProxy 255;
BA_ "GenSigSendType" SG_ 1411 HVAC_AutoSarNMReserved4 3;
BA_ "U_P702_MY2021_Tx" SG_ 1411 HVAC_AutoSarNMReserved4 1;
BA_ "U_CX727_MY2021_Tx" SG_ 1411 HVAC_AutoSarNMReserved4 1;
BA_ "U_H567_MY20_Tx" SG_ 1411 HVAC_AutoSarNMReserved4 1;
BA_ "U_CX430_MY2021_Tx" SG_ 1411 HVAC_AutoSarNMReserved4 1;
BA_ "U_U611_U625_MY20_Phev_Tx" SG_ 1411 HVAC_AutoSarNMReserved4 1;
BA_ "U_B562_MY18_Diesel_Tx" SG_ 1411 HVAC_AutoSarNMReserved4 1;
BA_ "U_CX482_CX483_MY20_Tx" SG_ 1411 HVAC_AutoSarNMReserved4 1;
BA_ "U_U611_U625_MY20_Hev_Tx" SG_ 1411 HVAC_AutoSarNMReserved4 1;
BA_ "U_U611_U625_MY20_Gas_Tx" SG_ 1411 HVAC_AutoSarNMReserved4 1;
BA_ "U_B500_MY18_Diesel_Tx" SG_ 1411 HVAC_AutoSarNMReserved4 1;
BA_ "U_B500_MY18_Gas_Tx" SG_ 1411 HVAC_AutoSarNMReserved4 1;
BA_ "U_C490_MY18_Tx" SG_ 1411 HVAC_AutoSarNMReserved4 1;
BA_ "U_B562_MY18_Gas_Tx" SG_ 1411 HVAC_AutoSarNMReserved4 1;
BA_ "U_C519_MY18_5_Gas_Tx" SG_ 1411 HVAC_AutoSarNMReserved4 1;
BA_ "U_C519_MY18_5_Diesel_Tx" SG_ 1411 HVAC_AutoSarNMReserved4 1;
BA_ "GenSigStartValue" SG_ 1411 HVAC_AutoSarNMReserved4 255;
BA_ "ContentDependant" SG_ 1411 HVAC_AutoSarNMReserved4 1;
BA_ "GenSigStartValueInteger" SG_ 1411 HVAC_AutoSarNMReserved4 255;
BA_ "GenSigSendType" SG_ 1411 HVAC_AutoSarNMReserved3 3;
BA_ "U_P702_MY2021_Tx" SG_ 1411 HVAC_AutoSarNMReserved3 1;
BA_ "U_CX727_MY2021_Tx" SG_ 1411 HVAC_AutoSarNMReserved3 1;
BA_ "U_H567_MY20_Tx" SG_ 1411 HVAC_AutoSarNMReserved3 1;
BA_ "U_CX430_MY2021_Tx" SG_ 1411 HVAC_AutoSarNMReserved3 1;
BA_ "U_U611_U625_MY20_Phev_Tx" SG_ 1411 HVAC_AutoSarNMReserved3 1;
BA_ "U_B562_MY18_Diesel_Tx" SG_ 1411 HVAC_AutoSarNMReserved3 1;
BA_ "U_CX482_CX483_MY20_Tx" SG_ 1411 HVAC_AutoSarNMReserved3 1;
BA_ "U_U611_U625_MY20_Hev_Tx" SG_ 1411 HVAC_AutoSarNMReserved3 1;
BA_ "U_U611_U625_MY20_Gas_Tx" SG_ 1411 HVAC_AutoSarNMReserved3 1;
BA_ "U_B500_MY18_Diesel_Tx" SG_ 1411 HVAC_AutoSarNMReserved3 1;
BA_ "U_B500_MY18_Gas_Tx" SG_ 1411 HVAC_AutoSarNMReserved3 1;
BA_ "U_C490_MY18_Tx" SG_ 1411 HVAC_AutoSarNMReserved3 1;
BA_ "U_B562_MY18_Gas_Tx" SG_ 1411 HVAC_AutoSarNMReserved3 1;
BA_ "U_C519_MY18_5_Gas_Tx" SG_ 1411 HVAC_AutoSarNMReserved3 1;
BA_ "U_C519_MY18_5_Diesel_Tx" SG_ 1411 HVAC_AutoSarNMReserved3 1;
BA_ "GenSigStartValue" SG_ 1411 HVAC_AutoSarNMReserved3 255;
BA_ "ContentDependant" SG_ 1411 HVAC_AutoSarNMReserved3 1;
BA_ "GenSigStartValueInteger" SG_ 1411 HVAC_AutoSarNMReserved3 255;
BA_ "GenSigSendType" SG_ 1411 HVAC_AutoSarNMReserved2 3;
BA_ "U_P702_MY2021_Tx" SG_ 1411 HVAC_AutoSarNMReserved2 1;
BA_ "U_CX727_MY2021_Tx" SG_ 1411 HVAC_AutoSarNMReserved2 1;
BA_ "U_H567_MY20_Tx" SG_ 1411 HVAC_AutoSarNMReserved2 1;
BA_ "U_CX430_MY2021_Tx" SG_ 1411 HVAC_AutoSarNMReserved2 1;
BA_ "U_U611_U625_MY20_Phev_Tx" SG_ 1411 HVAC_AutoSarNMReserved2 1;
BA_ "U_B562_MY18_Diesel_Tx" SG_ 1411 HVAC_AutoSarNMReserved2 1;
BA_ "U_CX482_CX483_MY20_Tx" SG_ 1411 HVAC_AutoSarNMReserved2 1;
BA_ "U_U611_U625_MY20_Hev_Tx" SG_ 1411 HVAC_AutoSarNMReserved2 1;
BA_ "U_U611_U625_MY20_Gas_Tx" SG_ 1411 HVAC_AutoSarNMReserved2 1;
BA_ "U_B500_MY18_Diesel_Tx" SG_ 1411 HVAC_AutoSarNMReserved2 1;
BA_ "U_B500_MY18_Gas_Tx" SG_ 1411 HVAC_AutoSarNMReserved2 1;
BA_ "U_C490_MY18_Tx" SG_ 1411 HVAC_AutoSarNMReserved2 1;
BA_ "U_B562_MY18_Gas_Tx" SG_ 1411 HVAC_AutoSarNMReserved2 1;
BA_ "U_C519_MY18_5_Gas_Tx" SG_ 1411 HVAC_AutoSarNMReserved2 1;
BA_ "U_C519_MY18_5_Diesel_Tx" SG_ 1411 HVAC_AutoSarNMReserved2 1;
BA_ "GenSigStartValue" SG_ 1411 HVAC_AutoSarNMReserved2 255;
BA_ "ContentDependant" SG_ 1411 HVAC_AutoSarNMReserved2 1;
BA_ "GenSigStartValueInteger" SG_ 1411 HVAC_AutoSarNMReserved2 255;
BA_ "GenSigSendType" SG_ 1411 HVAC_AutoSarNMReserved 3;
BA_ "U_P702_MY2021_Tx" SG_ 1411 HVAC_AutoSarNMReserved 1;
BA_ "U_CX727_MY2021_Tx" SG_ 1411 HVAC_AutoSarNMReserved 1;
BA_ "U_H567_MY20_Tx" SG_ 1411 HVAC_AutoSarNMReserved 1;
BA_ "U_CX430_MY2021_Tx" SG_ 1411 HVAC_AutoSarNMReserved 1;
BA_ "U_U611_U625_MY20_Phev_Tx" SG_ 1411 HVAC_AutoSarNMReserved 1;
BA_ "U_B562_MY18_Diesel_Tx" SG_ 1411 HVAC_AutoSarNMReserved 1;
BA_ "U_CX482_CX483_MY20_Tx" SG_ 1411 HVAC_AutoSarNMReserved 1;
BA_ "U_U611_U625_MY20_Hev_Tx" SG_ 1411 HVAC_AutoSarNMReserved 1;
BA_ "U_U611_U625_MY20_Gas_Tx" SG_ 1411 HVAC_AutoSarNMReserved 1;
BA_ "U_B500_MY18_Diesel_Tx" SG_ 1411 HVAC_AutoSarNMReserved 1;
BA_ "U_B500_MY18_Gas_Tx" SG_ 1411 HVAC_AutoSarNMReserved 1;
BA_ "U_C490_MY18_Tx" SG_ 1411 HVAC_AutoSarNMReserved 1;
BA_ "U_B562_MY18_Gas_Tx" SG_ 1411 HVAC_AutoSarNMReserved 1;
BA_ "U_C519_MY18_5_Gas_Tx" SG_ 1411 HVAC_AutoSarNMReserved 1;
BA_ "U_C519_MY18_5_Diesel_Tx" SG_ 1411 HVAC_AutoSarNMReserved 1;
BA_ "GenSigStartValue" SG_ 1411 HVAC_AutoSarNMReserved 255;
BA_ "ContentDependant" SG_ 1411 HVAC_AutoSarNMReserved 1;
BA_ "GenSigStartValueInteger" SG_ 1411 HVAC_AutoSarNMReserved 255;
BA_ "GenSigSendType" SG_ 1411 HVAC_AutoSarNMNodeId 3;
BA_ "U_P702_MY2021_Tx" SG_ 1411 HVAC_AutoSarNMNodeId 1;
BA_ "U_CX727_MY2021_Tx" SG_ 1411 HVAC_AutoSarNMNodeId 1;
BA_ "U_H567_MY20_Tx" SG_ 1411 HVAC_AutoSarNMNodeId 1;
BA_ "U_CX430_MY2021_Tx" SG_ 1411 HVAC_AutoSarNMNodeId 1;
BA_ "U_U611_U625_MY20_Phev_Tx" SG_ 1411 HVAC_AutoSarNMNodeId 1;
BA_ "U_B562_MY18_Diesel_Tx" SG_ 1411 HVAC_AutoSarNMNodeId 1;
BA_ "U_CX482_CX483_MY20_Tx" SG_ 1411 HVAC_AutoSarNMNodeId 1;
BA_ "U_U611_U625_MY20_Hev_Tx" SG_ 1411 HVAC_AutoSarNMNodeId 1;
BA_ "U_U611_U625_MY20_Gas_Tx" SG_ 1411 HVAC_AutoSarNMNodeId 1;
BA_ "U_B500_MY18_Diesel_Tx" SG_ 1411 HVAC_AutoSarNMNodeId 1;
BA_ "U_B500_MY18_Gas_Tx" SG_ 1411 HVAC_AutoSarNMNodeId 1;
BA_ "U_C490_MY18_Tx" SG_ 1411 HVAC_AutoSarNMNodeId 1;
BA_ "U_B562_MY18_Gas_Tx" SG_ 1411 HVAC_AutoSarNMNodeId 1;
BA_ "U_C519_MY18_5_Gas_Tx" SG_ 1411 HVAC_AutoSarNMNodeId 1;
BA_ "U_C519_MY18_5_Diesel_Tx" SG_ 1411 HVAC_AutoSarNMNodeId 1;
BA_ "GenSigStartValue" SG_ 1411 HVAC_AutoSarNMNodeId 131;
BA_ "ContentDependant" SG_ 1411 HVAC_AutoSarNMNodeId 1;
BA_ "GenSigStartValueInteger" SG_ 1411 HVAC_AutoSarNMNodeId 83;
BA_ "GenSigSendType" SG_ 1411 HVAC_AutoSarNMControl 3;
BA_ "U_P702_MY2021_Tx" SG_ 1411 HVAC_AutoSarNMControl 1;
BA_ "U_CX727_MY2021_Tx" SG_ 1411 HVAC_AutoSarNMControl 1;
BA_ "U_H567_MY20_Tx" SG_ 1411 HVAC_AutoSarNMControl 1;
BA_ "U_CX430_MY2021_Tx" SG_ 1411 HVAC_AutoSarNMControl 1;
BA_ "U_U611_U625_MY20_Phev_Tx" SG_ 1411 HVAC_AutoSarNMControl 1;
BA_ "U_B562_MY18_Diesel_Tx" SG_ 1411 HVAC_AutoSarNMControl 1;
BA_ "U_CX482_CX483_MY20_Tx" SG_ 1411 HVAC_AutoSarNMControl 1;
BA_ "U_U611_U625_MY20_Hev_Tx" SG_ 1411 HVAC_AutoSarNMControl 1;
BA_ "U_U611_U625_MY20_Gas_Tx" SG_ 1411 HVAC_AutoSarNMControl 1;
BA_ "U_B500_MY18_Diesel_Tx" SG_ 1411 HVAC_AutoSarNMControl 1;
BA_ "U_B500_MY18_Gas_Tx" SG_ 1411 HVAC_AutoSarNMControl 1;
BA_ "U_C490_MY18_Tx" SG_ 1411 HVAC_AutoSarNMControl 1;
BA_ "U_B562_MY18_Gas_Tx" SG_ 1411 HVAC_AutoSarNMControl 1;
BA_ "U_C519_MY18_5_Gas_Tx" SG_ 1411 HVAC_AutoSarNMControl 1;
BA_ "U_C519_MY18_5_Diesel_Tx" SG_ 1411 HVAC_AutoSarNMControl 1;
BA_ "ContentDependant" SG_ 1411 HVAC_AutoSarNMControl 1;
BA_ "U_P702_MY2021_Tx" SG_ 993 EmButtn_D_Stat 1;
BA_ "U_CX727_MY2021_Tx" SG_ 993 EmButtn_D_Stat 1;
BA_ "U_CX430_MY2021_Tx" SG_ 993 EmButtn_D_Stat 1;
BA_ "U_U611_U625_MY20_Phev_Tx" SG_ 993 EmButtn_D_Stat 1;
BA_ "U_CX482_CX483_MY20_Tx" SG_ 993 EmButtn_D_Stat 1;
BA_ "U_U611_U625_MY20_Hev_Tx" SG_ 993 EmButtn_D_Stat 1;
BA_ "U_U611_U625_MY20_Gas_Tx" SG_ 993 EmButtn_D_Stat 1;
BA_ "GenSigSendType" SG_ 993 EmButtn_D_Stat 3;
BA_ "U_P702_MY2021_Tx" SG_ 993 PersStore_D_Actl 1;
BA_ "U_CX727_MY2021_Tx" SG_ 993 PersStore_D_Actl 1;
BA_ "U_CX430_MY2021_Tx" SG_ 993 PersStore_D_Actl 1;
BA_ "U_U611_U625_MY20_Phev_Tx" SG_ 993 PersStore_D_Actl 1;
BA_ "U_CX482_CX483_MY20_Tx" SG_ 993 PersStore_D_Actl 1;
BA_ "U_U611_U625_MY20_Hev_Tx" SG_ 993 PersStore_D_Actl 1;
BA_ "U_U611_U625_MY20_Gas_Tx" SG_ 993 PersStore_D_Actl 1;
BA_ "U_C490_MY18_Tx" SG_ 993 PersStore_D_Actl 1;
BA_ "GenSigSendType" SG_ 993 PersStore_D_Actl 3;
BA_ "CrossOver_InfoCAN" SG_ 993 PersStore_D_Actl 1;
BA_ "U_P702_MY2021_Tx" SG_ 993 MemSwtch_D_RqRecall 1;
BA_ "U_CX727_MY2021_Tx" SG_ 993 MemSwtch_D_RqRecall 1;
BA_ "U_CX430_MY2021_Tx" SG_ 993 MemSwtch_D_RqRecall 1;
BA_ "U_U611_U625_MY20_Phev_Tx" SG_ 993 MemSwtch_D_RqRecall 1;
BA_ "U_CX482_CX483_MY20_Tx" SG_ 993 MemSwtch_D_RqRecall 1;
BA_ "U_U611_U625_MY20_Hev_Tx" SG_ 993 MemSwtch_D_RqRecall 1;
BA_ "U_U611_U625_MY20_Gas_Tx" SG_ 993 MemSwtch_D_RqRecall 1;
BA_ "U_C490_MY18_Tx" SG_ 993 MemSwtch_D_RqRecall 1;
BA_ "U_B479_MY17_Gas_Rx" SG_ 993 MemSwtch_D_RqRecall 1;
BA_ "GenSigSendType" SG_ 993 MemSwtch_D_RqRecall 3;
BA_ "CrossOver_InfoCAN" SG_ 993 MemSwtch_D_RqRecall 1;
BA_ "WakeupSignal" SG_ 993 MemSwtch_D_RqRecall 1;
BA_ "U_P702_MY2021_Tx" SG_ 993 MemSwtch_D_RqAssoc 1;
BA_ "U_CX727_MY2021_Tx" SG_ 993 MemSwtch_D_RqAssoc 1;
BA_ "U_CX430_MY2021_Tx" SG_ 993 MemSwtch_D_RqAssoc 1;
BA_ "U_U611_U625_MY20_Phev_Tx" SG_ 993 MemSwtch_D_RqAssoc 1;
BA_ "U_CX482_CX483_MY20_Tx" SG_ 993 MemSwtch_D_RqAssoc 1;
BA_ "U_U611_U625_MY20_Hev_Tx" SG_ 993 MemSwtch_D_RqAssoc 1;
BA_ "U_U611_U625_MY20_Gas_Tx" SG_ 993 MemSwtch_D_RqAssoc 1;
BA_ "U_C490_MY18_Tx" SG_ 993 MemSwtch_D_RqAssoc 1;
BA_ "U_B479_MY17_Gas_Rx" SG_ 993 MemSwtch_D_RqAssoc 1;
BA_ "GenSigSendType" SG_ 993 MemSwtch_D_RqAssoc 3;
BA_ "CrossOver_InfoCAN" SG_ 993 MemSwtch_D_RqAssoc 1;
BA_ "WakeupSignal" SG_ 993 MemSwtch_D_RqAssoc 1;
BA_ "U_P702_MY2021_Tx" SG_ 993 PersIndexDsm_D_Actl 1;
BA_ "U_CX727_MY2021_Tx" SG_ 993 PersIndexDsm_D_Actl 1;
BA_ "U_CX430_MY2021_Tx" SG_ 993 PersIndexDsm_D_Actl 1;
BA_ "U_U611_U625_MY20_Phev_Tx" SG_ 993 PersIndexDsm_D_Actl 1;
BA_ "U_CX482_CX483_MY20_Tx" SG_ 993 PersIndexDsm_D_Actl 1;
BA_ "U_U611_U625_MY20_Hev_Tx" SG_ 993 PersIndexDsm_D_Actl 1;
BA_ "U_U611_U625_MY20_Gas_Tx" SG_ 993 PersIndexDsm_D_Actl 1;
BA_ "U_C490_MY18_Tx" SG_ 993 PersIndexDsm_D_Actl 1;
BA_ "GenSigSendType" SG_ 993 PersIndexDsm_D_Actl 3;
BA_ "GenSigStartValue" SG_ 993 PersIndexDsm_D_Actl 4;
BA_ "GenSigStartValueInteger" SG_ 993 PersIndexDsm_D_Actl 4;
BA_ "CrossOver_InfoCAN" SG_ 993 PersIndexDsm_D_Actl 1;
BA_ "U_P702_MY2021_Tx" SG_ 993 FeatNoDsmActl 1;
BA_ "U_CX727_MY2021_Tx" SG_ 993 FeatNoDsmActl 1;
BA_ "U_CX430_MY2021_Tx" SG_ 993 FeatNoDsmActl 1;
BA_ "U_U611_U625_MY20_Phev_Tx" SG_ 993 FeatNoDsmActl 1;
BA_ "U_CX482_CX483_MY20_Tx" SG_ 993 FeatNoDsmActl 1;
BA_ "U_U611_U625_MY20_Hev_Tx" SG_ 993 FeatNoDsmActl 1;
BA_ "U_U611_U625_MY20_Gas_Tx" SG_ 993 FeatNoDsmActl 1;
BA_ "U_C490_MY18_Tx" SG_ 993 FeatNoDsmActl 1;
BA_ "GenSigSendType" SG_ 993 FeatNoDsmActl 3;
BA_ "CrossOver_InfoCAN" SG_ 993 FeatNoDsmActl 1;
BA_ "U_P702_MY2021_Tx" SG_ 993 FeatConfigDsmActl 1;
BA_ "U_CX727_MY2021_Tx" SG_ 993 FeatConfigDsmActl 1;
BA_ "U_CX430_MY2021_Tx" SG_ 993 FeatConfigDsmActl 1;
BA_ "U_U611_U625_MY20_Phev_Tx" SG_ 993 FeatConfigDsmActl 1;
BA_ "U_CX482_CX483_MY20_Tx" SG_ 993 FeatConfigDsmActl 1;
BA_ "U_U611_U625_MY20_Hev_Tx" SG_ 993 FeatConfigDsmActl 1;
BA_ "U_U611_U625_MY20_Gas_Tx" SG_ 993 FeatConfigDsmActl 1;
BA_ "U_C490_MY18_Tx" SG_ 993 FeatConfigDsmActl 1;
BA_ "GenSigSendType" SG_ 993 FeatConfigDsmActl 3;
BA_ "CrossOver_InfoCAN" SG_ 993 FeatConfigDsmActl 1;
BA_ "U_P702_MY2021_Tx" SG_ 1881 TesterPhysicalResRTM 1;
BA_ "U_CX727_MY2021_Tx" SG_ 1881 TesterPhysicalResRTM 1;
BA_ "U_VN127_MY20_Tx" SG_ 1881 TesterPhysicalResRTM 1;
BA_ "U_H567_MY20_Tx" SG_ 1881 TesterPhysicalResRTM 1;
BA_ "U_CX430_MY2021_Tx" SG_ 1881 TesterPhysicalResRTM 1;
BA_ "U_U611_U625_MY20_Phev_Tx" SG_ 1881 TesterPhysicalResRTM 1;
BA_ "U_CX482_CX483_MY20_Tx" SG_ 1881 TesterPhysicalResRTM 1;
BA_ "U_U611_U625_MY20_Hev_Tx" SG_ 1881 TesterPhysicalResRTM 1;
BA_ "U_U611_U625_MY20_Gas_Tx" SG_ 1881 TesterPhysicalResRTM 1;
BA_ "U_C519_MY18_5_Gas_Tx" SG_ 1881 TesterPhysicalResRTM 1;
BA_ "U_C519_MY18_5_Diesel_Tx" SG_ 1881 TesterPhysicalResRTM 1;
BA_ "U_B515_MCA_MY17_Gas_Tx" SG_ 1881 TesterPhysicalResRTM 1;
BA_ "U_B515_MCA_MY17_Diesel_Tx" SG_ 1881 TesterPhysicalResRTM 1;
BA_ "U_B479_MY17_Diesel_Tx" SG_ 1881 TesterPhysicalResRTM 1;
BA_ "U_B479_MY17_Gas_Tx" SG_ 1881 TesterPhysicalResRTM 1;
BA_ "GenSigSendType" SG_ 1881 TesterPhysicalResRTM 3;
BA_ "U_P702_MY2021_Rx" SG_ 1873 TesterPhysicalReqRTM 1;
BA_ "U_CX727_MY2021_Rx" SG_ 1873 TesterPhysicalReqRTM 1;
BA_ "U_VN127_MY20_Rx" SG_ 1873 TesterPhysicalReqRTM 1;
BA_ "U_H567_MY20_Rx" SG_ 1873 TesterPhysicalReqRTM 1;
BA_ "U_CX430_MY2021_Rx" SG_ 1873 TesterPhysicalReqRTM 1;
BA_ "U_U611_U625_MY20_Phev_Rx" SG_ 1873 TesterPhysicalReqRTM 1;
BA_ "U_CX482_CX483_MY20_Rx" SG_ 1873 TesterPhysicalReqRTM 1;
BA_ "U_U611_U625_MY20_Hev_Rx" SG_ 1873 TesterPhysicalReqRTM 1;
BA_ "U_U611_U625_MY20_Gas_Rx" SG_ 1873 TesterPhysicalReqRTM 1;
BA_ "U_C519_MY18_5_Gas_Rx" SG_ 1873 TesterPhysicalReqRTM 1;
BA_ "U_C519_MY18_5_Diesel_Rx" SG_ 1873 TesterPhysicalReqRTM 1;
BA_ "U_B515_MCA_MY17_Gas_Rx" SG_ 1873 TesterPhysicalReqRTM 1;
BA_ "U_B515_MCA_MY17_Diesel_Rx" SG_ 1873 TesterPhysicalReqRTM 1;
BA_ "U_B479_MY17_Diesel_Rx" SG_ 1873 TesterPhysicalReqRTM 1;
BA_ "U_B479_MY17_Gas_Rx" SG_ 1873 TesterPhysicalReqRTM 1;
BA_ "GenSigSendType" SG_ 1873 TesterPhysicalReqRTM 3;
BA_ "U_B562_MY18_Diesel_Rx" SG_ 2015 TesterFunctionalReq 1;
BA_ "U_B500_MY18_Diesel_Rx" SG_ 2015 TesterFunctionalReq 1;
BA_ "U_B500_MY18_Gas_Rx" SG_ 2015 TesterFunctionalReq 1;
BA_ "U_B562_MY18_Gas_Rx" SG_ 2015 TesterFunctionalReq 1;
BA_ "U_VN127_MY20_Rx" SG_ 2015 TesterFunctionalReq 1;
BA_ "U_H567_MY20_Rx" SG_ 2015 TesterFunctionalReq 1;
BA_ "U_B515_MCA_MY17_Gas_Rx" SG_ 2015 TesterFunctionalReq 1;
BA_ "U_B515_MCA_MY17_Diesel_Rx" SG_ 2015 TesterFunctionalReq 1;
BA_ "U_B479_MY17_Diesel_Rx" SG_ 2015 TesterFunctionalReq 1;
BA_ "U_B479_MY17_Gas_Rx" SG_ 2015 TesterFunctionalReq 1;
BA_ "U_CX430_MY2021_Rx" SG_ 2015 TesterFunctionalReq 1;
BA_ "U_C490_MY18_Rx" SG_ 2015 TesterFunctionalReq 1;
BA_ "U_CX727_MY2021_Rx" SG_ 2015 TesterFunctionalReq 1;
BA_ "U_C519_MY18_5_Gas_Rx" SG_ 2015 TesterFunctionalReq 1;
BA_ "U_C519_MY18_5_Diesel_Rx" SG_ 2015 TesterFunctionalReq 1;
BA_ "U_B562LC_MY15_Gas_Rx" SG_ 2015 TesterFunctionalReq 1;
BA_ "U_B562LC_MY15_Diesel_Rx" SG_ 2015 TesterFunctionalReq 1;
BA_ "U_P702_MY2021_Rx" SG_ 2015 TesterFunctionalReq 1;
BA_ "U_U611_U625_MY20_Phev_Rx" SG_ 2015 TesterFunctionalReq 1;
BA_ "U_CX482_CX483_MY20_Rx" SG_ 2015 TesterFunctionalReq 1;
BA_ "U_U611_U625_MY20_Hev_Rx" SG_ 2015 TesterFunctionalReq 1;
BA_ "U_U611_U625_MY20_Gas_Rx" SG_ 2015 TesterFunctionalReq 1;
BA_ "GenSigSendType" SG_ 2015 TesterFunctionalReq 3;
BA_ "CrossOver_InfoCAN" SG_ 2015 TesterFunctionalReq 1;
BA_ "GenSigSendType" SG_ 320 PwSldDrIntSwL_B_Stat 3;
BA_ "ContentDependant" SG_ 320 PwSldDrIntSwL_B_Stat 1;
BA_ "WakeupSignal" SG_ 320 PwSldDrIntSwL_B_Stat 1;
BA_ "GenSigSendType" SG_ 320 LPwrSlideDr_Unlock_Rq 3;
BA_ "ContentDependant" SG_ 320 LPwrSlideDr_Unlock_Rq 1;
BA_ "WakeupSignal" SG_ 320 LPwrSlideDr_Unlock_Rq 1;
BA_ "GenSigSendType" SG_ 313 PwSldDrIntSwR_B_Stat 3;
BA_ "ContentDependant" SG_ 313 PwSldDrIntSwR_B_Stat 1;
BA_ "WakeupSignal" SG_ 313 PwSldDrIntSwR_B_Stat 1;
BA_ "GenSigSendType" SG_ 313 RPwrSlideDr_Unlock_Rq 3;
BA_ "ContentDependant" SG_ 313 RPwrSlideDr_Unlock_Rq 1;
BA_ "WakeupSignal" SG_ 313 RPwrSlideDr_Unlock_Rq 1;
VAL_ 819 BLISLEDStatPassSide 3 "Fault" 2 "Unused" 1 "On" 0 "Off" ;
VAL_ 819 WndwPsngrSide_D_Stat 3 "BothWindow_Operating" 2 "RearWindow_Operating" 1 "FrontWindow_Operating" 0 "NoWindows_Operating" ;
VAL_ 819 Pasngr_Lock_Sw_Stat 3 "Invalid" 2 "Unlock" 1 "Lock" 0 "Null" ;
VAL_ 819 ChildLckFdbckRp_B_Stat 1 "Locked" 0 "Unlock" ;
VAL_ 818 BLISLEDStatDriverSide 3 "Fault" 2 "Unused" 1 "On" 0 "Off" ;
VAL_ 818 WndwDrvSide_D_Stat 3 "BothWindow_Operating" 2 "RearWindow_Operating" 1 "FrontWindow_Operating" 0 "NoWindows_Operating" ;
VAL_ 818 KeyCylSwDrvDr_D_Stat 3 "NotUsed" 2 "Unlock" 1 "Lock" 0 "Null" ;
VAL_ 818 Driver_Lock_Sw_Stat 3 "Invalid" 2 "Unlock" 1 "Lock" 0 "Null" ;
VAL_ 818 ChildLckPw_D_Rq 1 "Active" 0 "Null" ;
VAL_ 818 ChildLckFdbckRd_B_Stat 1 "Locked" 0 "Unlock" ;
VAL_ 818 RvrseMirrorChime_B_Rq 1 "Yes" 0 "No" ;
VAL_ 817 ChildLckMde_B_Stat 1 "Enable" 0 "Disable" ;
VAL_ 817 VehLckInd_D_Rq 3 "NotUsed" 2 "On_Day" 1 "On_Night" 0 "Off" ;
VAL_ 817 DrTgateOpen_B_Rq 1 "Open" 0 "Null" ;
VAL_ 817 DrTgateExtSwMde_B_Stat 1 "Enable" 0 "Disable" ;
VAL_ 817 Remote_Device_Feedback 7 "Unused3" 6 "Unused2" 5 "Unused1" 4 "Shutdown" 3 "Running" 2 "Starting" 1 "Acknowledge" 0 "Null" ;
VAL_ 817 Power_Liftgate_Rqst 1 "Active" 0 "Null" ;
VAL_ 817 Power_Decklid_Rqst 1 "Active" 0 "Null" ;
VAL_ 817 Veh_Lock_Requestor 31 "Unused8" 30 "Unused7" 29 "Unused6" 28 "Rgtm_Shutlock_Switch" 27 "Boundary_Alert" 26 "Transit_Vehicle_Relock" 25 "Transit_Cargo_Relock" 24 "Transit_Ajar_Lock" 23 "Diagnostics" 22 "Console_Lock" 21 "Child_Lock" 20 "Double_Lock" 19 "Passive_Pasenger" 18 "Passive_Driver" 17 "Slam_Lock_Protect" 16 "SYNC" 15 "Passport" 14 "Passive_Smart_Unlock" 13 "Autorelock" 12 "RemoteStart" 0 "Null" 1 "Autolock" 11 "Smart_Unlock" 10 "Sliding_Door" 9 "Passive" 8 "Remote" 7 "Programming" 6 "Powerslide" 5 "Keypad" 4 "Key_Cylinder" 3 "Interior" 2 "Auto_Unlock" ;
VAL_ 817 Veh_Lock_Sub_Id 15 "Unused7" 14 "Unused6" 13 "Unused5" 12 "Unused4" 11 "Unused3" 10 "Unused2" 9 "Unused1" 8 "Customer_8" 7 "Customer_7" 6 "Customer_6" 5 "Customer_5" 4 "Customer_4" 3 "Customer_3" 2 "Customer_2" 1 "Customer_1" 0 "Null" ;
VAL_ 817 ChildLck_D_Dsply 3 "NOT_SUPPORTED" 2 "ERROR" 1 "CHILD_UNLOCK" 0 "CHILD_LOCK" ;
VAL_ 817 Lockmsgtxt_D_Rq 7 "MSG7" 6 "MSG6" 5 "MSG5" 4 "MSG4" 3 "MSG3" 2 "MSG2" 1 "MSG1" 0 "NO_WARNING" ;
VAL_ 817 LockInhibit 1 "Inhibit" 0 "No_Inhibit" ;
VAL_ 817 Veh_Lock_Status 3 "UNLOCK_DRV" 2 "UNLOCK_ALL" 1 "LOCK_ALL" 0 "LOCK_DBL" ;
VAL_ 817 FobComm_D_Stat 3 "NotUsed" 2 "RemEngStartOK" 1 "RemEngStartFail" 0 "Null" ;
VAL_ 817 WindowLockout_B_Stat 1 "Locked" 0 "Unlock" ;
VAL_ 1091 TowBarMsgTxt_D_Rq 7 "NotUsed3" 6 "NotUsed2" 5 "NotUsed1" 4 "TowBar_Ext_No_Trlr" 3 "Error_Dealer_Fix" 2 "Start_Engine_Swivel" 1 "Check_Tow_Bar" 0 "Null" ;
VAL_ 1091 ParkLampTrlrOut_B_Stat 1 "Out" 0 "Null" ;
VAL_ 1091 TrlrLampCtl_D_Stat 3 "NotUsed" 2 "TrlrLampCnnctDrvFailure" 1 "TrlrLampNotCnnctDrvFailure" 0 "Null" ;
VAL_ 1091 TrlrBattChrg_D_Stat 3 "Reverse" 2 "Normal" 1 "Low" 0 "Null" ;
VAL_ 1091 StopLampTrlrOut_B_Stat 1 "Out" 0 "Null" ;
VAL_ 1091 TurnLampTrlrRr_B_Stat 1 "Out" 0 "Null" ;
VAL_ 1091 TurnLampTrlrRl_B_Stat 1 "Out" 0 "Null" ;
VAL_ 1091 TrlrLampCnnct_B_Actl 1 "Yes" 0 "No" ;
VAL_ 1066 BattULo_U_Actl_UB 1 "Fresh_data" 0 "Unchanged_data" ;
VAL_ 1066 BattULo_U_Actl 255 "Fault" ;
VAL_ 1066 PwSrcULo_I_Mx 255 "Fault" ;
VAL_ 1066 PwSrcULo_I_Actl 255 "Fault" ;
VAL_ 1066 PwSrcULo_I_Mx_UB 1 "Fresh_data" 0 "Unchanged_data" ;
VAL_ 1066 PwSrcULo_I_Actl_UB 1 "Fresh_data" 0 "Unchanged_data" ;
VAL_ 994 Pers4OptIn_B_Stats 1 "OPTED_IN" 0 "NOT_OPTED_IN" ;
VAL_ 994 Pers3OptIn_B_Stats 1 "OPTED_IN" 0 "NOT_OPTED_IN" ;
VAL_ 994 Pers2OptIn_B_Stats 1 "OPTED_IN" 0 "NOT_OPTED_IN" ;
VAL_ 994 Pers1OptIn_B_Stats 1 "OPTED_IN" 0 "NOT_OPTED_IN" ;
VAL_ 994 CtrStkPersIndex_D_Actl 7 "Unused_3" 6 "Unused_2" 5 "Unused_1" 4 "Vehicle" 3 "PERS_4" 2 "PERS_3" 1 "PERS_2" 0 "PERS_1" ;
VAL_ 994 CtrStkDsplyOp_D_Rq 7 "Unused_2" 6 "Unused_1" 5 "Copy" 4 "Restore" 3 "Upload" 2 "Set" 1 "Query" 0 "Null" ;
VAL_ 994 PersStore_D_Rq 7 "Unused_2" 6 "Unused_1" 5 "Vehicle" 4 "PERS_4" 3 "PERS_3" 2 "PERS_2" 1 "PERS_1" 0 "Null" ;
VAL_ 376 GasPrtc_D_RqDsply 7 "NotUsed_5" 6 "NotUsed_4" 5 "NotUsed_3" 4 "NotUsed_2" 3 "NotUsed_1" 2 "GpfOverLimit" 1 "GpfAtLimit" 0 "NormalOperation" ;
VAL_ 376 AslIconDsply_D_Rq 3 "Not_Used" 2 "On_Active" 1 "On_Passive" 0 "Off" ;
VAL_ 376 AslChime_B_Rq 1 "Yes" 0 "No" ;
VAL_ 376 PtcHtr_D_Cmd 3 "TurnOn" 2 "AutoMode" 1 "TurnOff" 0 "NoDecision_Initializing" ;
VAL_ 376 HvacHtrCore2_Te_Actl 1023 "Faulty" ;
VAL_ 376 EcssLamp_D_RqDsply 3 "Not_Used" 2 "Flash" 1 "On" 0 "Off" ;
VAL_ 376 AirAmbTe_D_Qf 3 "OK" 2 "Not_Within_Specifications" 1 "No_Data_Exists" 0 "Faulty" ;
VAL_ 376 DynoMde_B_Cmd 1 "Two_Wheel_Dyno" 0 "Normal_Operation" ;
VAL_ 376 AirAmb_P_Actl 63 "Fault" 62 "NoDataExists" ;
VAL_ 1068 HvacAirFullOut_B_Rq_UB 1 "Fresh_data" 0 "Unchanged_data" ;
VAL_ 1068 HvacAirFullOut_B_Rq 1 "Yes" 0 "No" ;
VAL_ 1068 HvacCmprLim_D_Stat_UB 1 "Fresh_data" 0 "Unchanged_data" ;
VAL_ 1068 HvacCmprLim_D_Stat 7 "NotUsed_2" 6 "NotUsed_1" 5 "CompressorHeadPressure" 4 "AvailableTorque" 3 "PedalPosition" 2 "RPM" 1 "ECT" 0 "NoLimit" ;
VAL_ 1068 HvacAirFlw_B_RqBatt_UB 1 "Fresh_data" 0 "Unchanged_data" ;
VAL_ 1068 HvacAirFlw_B_RqBatt 1 "Request" 0 "NoRequest" ;
VAL_ 1068 HvacRec_D_RqMxBatt_UB 1 "Fresh_data" 0 "Unchanged_data" ;
VAL_ 1068 HvacRec_D_RqMxBatt 15 "NotUsed5" 14 "NotUsed4" 13 "NotUsed3" 12 "NotUsed2" 11 "NotUsed1" 10 "No_Override" 9 "90Percent_RecircMax" 8 "80Percent_RecircMax" 7 "70Percent_RecircMax" 6 "60Percent_RecircMax" 5 "50Percent_RecircMax" 4 "40Percent_RecircMax" 3 "30Percent_RecircMax" 2 "20Percent_RecircMax" 1 "10Percent_RecircMax" 0 "0Percent_RecircFullOpen" ;
VAL_ 1068 Batt_Lo_SoC_B_UB 1 "Fresh_data" 0 "Unchanged_data" ;
VAL_ 1068 Batt_Lo_SoC_B 1 "Active" 0 "Inactive" ;
VAL_ 1068 Batt_Crit_SoC_B_UB 1 "Fresh_data" 0 "Unchanged_data" ;
VAL_ 1068 Batt_Crit_SoC_B 1 "Active" 0 "Inactive" ;
VAL_ 1068 Shed_T_Eng_Off_B_UB 1 "Fresh_data" 0 "Unchanged_data" ;
VAL_ 1068 Shed_T_Eng_Off_B 1 "Active" 0 "Inactive" ;
VAL_ 1068 Shed_Level_Req_UB 1 "Fresh_data" 0 "Unchanged_data" ;
VAL_ 1068 Shed_Level_Req 7 "Unused_2" 6 "Loads_On" 5 "SHED_ENG_OFF" 4 "SOON_ENG_OFF" 3 "SHED2_CONTIN" 2 "SHED2_TRANS" 1 "SHED1" 0 "NO_SHED" ;
VAL_ 1068 Shed_Feature_Group_ID_UB 1 "Fresh_data" 0 "Unchanged_data" ;
VAL_ 1068 Shed_Feature_Group_ID 16 "PtcHeater" 14 "HtdMirr" 13 "HvacRearBlwr_Third" 12 "HvacRearBlwr_Second" 11 "HvacRearBlwr_First" 31 "All LSHED1 Features" 10 "Htd_Windscrn" 9 "SpltHtdBcklight_HtdMirr" 8 "HtdBcklight_HtdMirr" 7 "HtdCoolSeat_FrtDriver" 6 "HtdCoolSeat_FrtPass" 5 "HtdCoolSeat_RearPass" 4 "HtdCoolSeat_RearDriver" 3 "SmartTrlrTowBattCharge" 2 "Htd_StrWhl" 1 "Htd_Washer_Fluid" 0 "No_LSHED1_Features" 15 "Engine_Coolant_Fan" ;
VAL_ 1068 Shed_Drain_Eng_Off_B_UB 1 "Fresh_data" 0 "Unchanged_data" ;
VAL_ 1068 Shed_Drain_Eng_Off_B 1 "Active" 0 "Inactive" ;
VAL_ 1068 AirCondRec_B_Rq_UB 1 "Fresh_data" 0 "Unchanged_data" ;
VAL_ 1068 AirCondFluidHi_P_Actl_UB 1 "Fresh_data" 0 "Unchanged_data" ;
VAL_ 1068 AirCondFluidHi_P_Actl 255 "Fault" 254 "Unknown" ;
VAL_ 1068 AirCondClutch_B_Stats 1 "Yes" 0 "No" ;
VAL_ 1068 AirCondClutch_B_Stats_UB 1 "Fresh_data" 0 "Unchanged_data" ;
VAL_ 1068 AirCondRec_B_Rq 1 "Yes" 0 "No" ;
VAL_ 963 Illuminated_Entry_Stat 3 "Invalid" 2 "Unknown" 1 "On" 0 "Off" ;
VAL_ 963 Dr_Courtesy_Light_Stat 3 "Invalid" 2 "Unknown" 1 "On" 0 "Off" ;
VAL_ 963 ImpactEvntFdbck_D_Stat 3 "NotUsed" 2 "EventComplete" 1 "EventInProgress" 0 "Normal" ;
VAL_ 963 PudLampPsngr_D_Rq 3 "Ramp_Down" 2 "Ramp_Up" 1 "On" 0 "Off" ;
VAL_ 963 HeadLampLoOut_B_Stat 1 "Out" 0 "Null" ;
VAL_ 963 HeadLghtHiFdbck_D_Stat 3 "NotUsed" 2 "Cancel" 1 "Hold" 0 "Allow_Change" ;
VAL_ 963 PrkLightChime_B_Rq 1 "On" 0 "Off" ;
VAL_ 963 TrnNotInPrkChime_B_Rq 1 "On" 0 "Off" ;
VAL_ 963 HomeSafeLtChime_B_Rq 1 "On" 0 "Off" ;
VAL_ 963 StopLghtOn_B_Stat 1 "On" 0 "Off" ;
VAL_ 963 RvrseLghtOn_B_Stat 1 "On" 0 "Off" ;
VAL_ 963 PrkLght_D_Stat 3 "Park_Both" 2 "Park_Right" 1 "Park_Left" 0 "Off" ;
VAL_ 963 HeadLghtSwtch_D_Stat 3 "Autolamp" 2 "Headlamp" 1 "Parklamp" 0 "Off" ;
VAL_ 963 KeyInIgnWarn_B_Cmd 1 "On" 0 "Off" ;
VAL_ 963 HeadLampLoFrOn_B_Stat 1 "Low" 0 "Not_Low" ;
VAL_ 963 HeadLampLoFlOn_B_Stat 1 "Low" 0 "Not_Low" ;
VAL_ 963 Headlamp_On_Wrning_Cmd 1 "On" 0 "Off" ;
VAL_ 963 HeadLampLoActv_B_Stat 1 "On" 0 "Off" ;
VAL_ 963 HeadLghtHiOn_B_Stat 1 "On" 0 "Off" ;
VAL_ 963 Park_Brake_Chime_Rqst 1 "On" 0 "Off" ;
VAL_ 963 BrkWarnInd_B_Rq 1 "On" 0 "Off" ;
VAL_ 963 Brk_Fluid_Lvl_Low 3 "Invalid" 2 "Unknown" 1 "Low" 0 "OK" ;
VAL_ 963 ReducedGuard_D_Stat 3 "NotUsed" 2 "Alarm_On" 1 "Alarm_Off_Previously_On" 0 "Alarm_Off" ;
VAL_ 963 Courtesy_BSave_Stat 3 "Invalid" 2 "Unknown" 1 "No_Effect" 0 "Off" ;
VAL_ 963 DayRnngLampOn_B_Stat 1 "On" 0 "Off" ;
VAL_ 963 PerimeterAlarmChimeRq 1 "On" 0 "Off" ;
VAL_ 963 PudLampDrv_D_Rq 3 "Ramp_Down" 2 "Ramp_Up" 1 "On" 0 "Off" ;
VAL_ 963 Courtesy_Delay_Status 3 "Invalid" 2 "Unknown" 1 "On" 0 "Off" ;
VAL_ 963 Perimeter_Alarm_Status 3 "Activated" 2 "Armed" 1 "Prearmed" 0 "Disarmed" ;
VAL_ 963 WndwGlbl_D_Cmd 7 "NotUsed3" 6 "NotUsed2" 5 "NotUsed1" 4 "GLEARN" 3 "GCLOSE" 2 "GOPEN" 1 "GSTOP" 0 "Null" ;
VAL_ 963 PudLamp_D_Rq 3 "RAMP_DOWN" 2 "RAMP_UP" 1 "ON" 0 "OFF" ;
VAL_ 964 FohEng_D_Rq_UB 1 "Fresh_data" 0 "Unchanged_data" ;
VAL_ 964 FohEng_D_Rq 3 "AutoEnable_ParkEnable" 2 "AutoDisable_ParkEnable" 1 "AutoEnable_ParkDisable" 0 "Disable_Stop" ;
VAL_ 964 EcoMode_B_Stat_UB 1 "Fresh_data" 0 "Unchanged_data" ;
VAL_ 964 Cta_D_Rq_UB 1 "Fresh_data" 0 "Unchanged_data" ;
VAL_ 964 Cta_D_Rq 3 "Unused" 2 "NoDataExists" 1 "On" 0 "Off" ;
VAL_ 964 GearRvrse_D_Actl_UB 1 "Fresh_data" 0 "Unchanged_data" ;
VAL_ 964 GearRvrse_D_Actl 7 "Fault" 6 "NotUsed_3" 5 "NotUsed_2" 4 "NotUsed_1" 3 "Active_confirmed" 2 "Active_not_confirmed" 1 "Inactive_confirmed" 0 "Inactive_not_confirmed" ;
VAL_ 964 TurnLghtSwtch_D_Stat_UB 1 "Fresh_data" 0 "Unchanged_data" ;
VAL_ 964 TurnLghtSwtch_D_Stat 3 "Unused_Treat_As_Off" 2 "Right" 1 "Left" 0 "Off" ;
VAL_ 964 Power_Liftgate_Mode_Cmd_UB 1 "Fresh_data" 0 "Unchanged_data" ;
VAL_ 964 Power_Liftgate_Mode_Cmd 1 "Enable" 0 "Disable" ;
VAL_ 964 EcoMode_B_Stat 1 "On" 0 "Off" ;
VAL_ 964 MetricActvTe_B_Actl_UB 1 "Fresh_data" 0 "Unchanged_data" ;
VAL_ 964 MetricActvTe_B_Actl 1 "Active" 0 "Inactive" ;
VAL_ 964 EngClntTe_D_Qf 3 "OK" 2 "Not_Within_Specifications" 1 "No_Data_Exists" 0 "Faulty" ;
VAL_ 964 Sod_D_Rq 2 "BLIS_On_Second_Warning_ON" 1 "BLIS_On_Second_Warning_OFF" 0 "Off" ;
VAL_ 964 MetricActv_B_Actl 1 "Active" 0 "Inactive" ;
VAL_ 964 MetricActv_B_Actl_UB 1 "Fresh_data" 0 "Unchanged_data" ;
VAL_ 964 EngClnt_Te_Actl_UB 1 "Fresh_data" 0 "Unchanged_data" ;
VAL_ 964 OCSSensrDataUpperLim_UB 1 "Fresh_data" 0 "Unchanged_data" ;
VAL_ 964 OCSSensrDataUpperLim 255 "Invalid" ;
VAL_ 964 OCSSensrDataLowerLim_UB 1 "Fresh_data" 0 "Unchanged_data" ;
VAL_ 964 PrkAid_D_Falt 7 "NotUsed2" 6 "NotUsed1" 5 "Failure_Front_PSM_Sensors" 4 "No_Data_Exists" 3 "Failure_Rear_Sensors" 2 "Speaker_Fault" 1 "ECU_Fault" 0 "No_Fault" ;
VAL_ 964 OCSSensrDataLowerLim 255 "Invalid" ;
VAL_ 964 PrkAid_D_Falt_UB 1 "Fresh_data" 0 "Unchanged_data" ;
VAL_ 964 WiprFront_D_Stat_UB 1 "Fresh_data" 0 "Unchanged_data" ;
VAL_ 964 WiprFront_D_Stat 15 "NO_DATA_EXISTS" 14 "STALLED" 13 "RESERVED" 12 "AUTO_ADJUST" 11 "COURTESYWIPE" 10 "AUTO_HIGH" 9 "AUTO_LOW" 8 "WASH" 7 "MIST_FLICK" 6 "MAN_HIGH" 5 "MAN_LOW" 4 "MAN_INT_ON" 3 "MAN_INT_OFF" 2 "OFF_MOVING" 1 "AUTO_OFF" 0 "OFF" ;
VAL_ 964 CamraDefog_B_Req_UB 1 "Fresh_data" 0 "Unchanged_data" ;
VAL_ 964 Sod_D_Rq_UB 1 "Fresh_data" 0 "Unchanged_data" ;
VAL_ 964 CamraDefog_B_Req 1 "On" 0 "Off" ;
VAL_ 993 EmButtn_D_Stat 7 "ButtonAssociationFailed" 6 "ButtonAssociationExited" 5 "ButtonAssociationEntered" 4 "Button4Pressed" 3 "Button3Pressed" 2 "Button2Pressed" 1 "Button1Pressed" 0 "Null" ;
VAL_ 993 PersStore_D_Actl 3 "Unused" 2 "Null" 1 "InProgress" 0 "Complete" ;
VAL_ 993 MemSwtch_D_RqRecall 7 "Unused_3" 6 "Unused_2" 5 "Unused_1" 4 "PERS_4" 3 "PERS_3" 2 "PERS_2" 1 "PERS_1" 0 "Null" ;
VAL_ 993 MemSwtch_D_RqAssoc 7 "Unused_3" 6 "Unused_2" 5 "Unused_1" 4 "PERS_4" 3 "PERS_3" 2 "PERS_2" 1 "PERS_1" 0 "Null" ;
VAL_ 993 PersIndexDsm_D_Actl 7 "Unused_3" 6 "Unused_2" 5 "Unused_1" 4 "Vehicle" 3 "PERS_4" 2 "PERS_3" 1 "PERS_2" 0 "PERS_1" ;
VAL_ 320 PwSldDrIntSwL_B_Stat 1 "Pressed" 0 "Null" ;
VAL_ 320 LPwrSlideDr_Unlock_Rq 1 "Unlock" 0 "Null" ;
VAL_ 313 PwSldDrIntSwR_B_Stat 1 "Pressed" 0 "Null" ;
VAL_ 313 RPwrSlideDr_Unlock_Rq 1 "Unlock" 0 "Null" ;
